VERSION "HNNBNNNYNNNNNNNNNNNNNNNNNNNNNNNNNNNNNNNNNN/4/%%%/4/'%**4NNN///"

NS_ :

BS_:

BU_: BAP_Tester BedienDisp_mi BedienDisp_vo_mi CDI ConMod_CD DashCAM Gateway_Max ICC_IO_Node LSH OCU RDK_RS3 Sound_MIB_ab_Gen3 STH ZR_MIB_EINSTIEG_ab_Gen3 ZR_MIB_OPTION_ab_Gen3 ZR_MIB_TOP_ab_Gen3

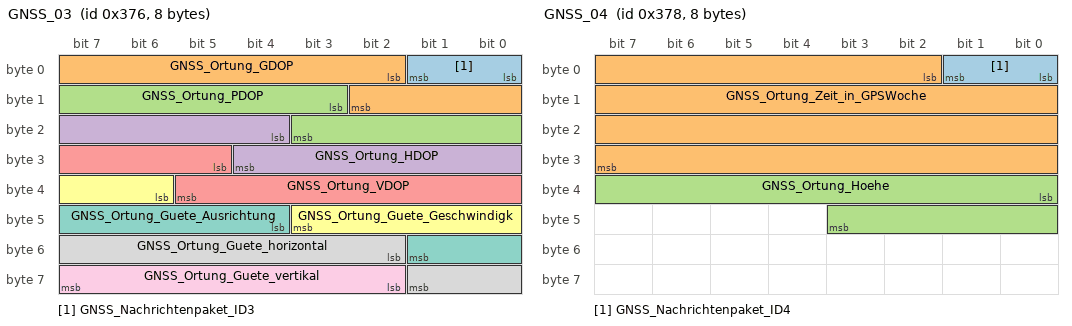
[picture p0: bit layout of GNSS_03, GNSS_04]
BO_ 886 GNSS_03: 8 OCU
 SG_ GNSS_Nachrichtenpaket_ID3 : 0|2@1+ (1,0) [0|3] "Unit_Bit"  Gateway_Max,ZR_MIB_EINSTIEG_ab_Gen3,ZR_MIB_TOP_ab_Gen3
 SG_ GNSS_Ortung_GDOP : 2|9@1+ (0.1,0) [0.0|50.0] "Unit_None"  Gateway_Max,ZR_MIB_EINSTIEG_ab_Gen3,ZR_MIB_TOP_ab_Gen3
 SG_ GNSS_Ortung_PDOP : 11|9@1+ (0.1,0) [0.0|50.0] "Unit_None"  Gateway_Max,ZR_MIB_EINSTIEG_ab_Gen3,ZR_MIB_TOP_ab_Gen3
 SG_ GNSS_Ortung_HDOP : 20|9@1+ (0.1,0) [0.0|50.0] "Unit_None"  Gateway_Max,ZR_MIB_EINSTIEG_ab_Gen3,ZR_MIB_TOP_ab_Gen3
 SG_ GNSS_Ortung_VDOP : 29|9@1+ (0.1,0) [0.0|50.0] "Unit_None"  Gateway_Max,ZR_MIB_EINSTIEG_ab_Gen3,ZR_MIB_TOP_ab_Gen3
 SG_ GNSS_Ortung_Guete_Geschwindigk : 38|6@1+ (0.05,0) [0.00|3.05] "Unit_MeterPerSecon"  Gateway_Max,ZR_MIB_EINSTIEG_ab_Gen3,ZR_MIB_TOP_ab_Gen3
 SG_ GNSS_Ortung_Guete_Ausrichtung : 44|6@1+ (0.15,0) [0.00|9.15] "Unit_DegreOfArc"  Gateway_Max,ZR_MIB_EINSTIEG_ab_Gen3,ZR_MIB_TOP_ab_Gen3
 SG_ GNSS_Ortung_Guete_horizontal : 50|8@1+ (1,0) [0|250] "Unit_Meter"  Gateway_Max,ZR_MIB_EINSTIEG_ab_Gen3,ZR_MIB_TOP_ab_Gen3
 SG_ GNSS_Ortung_Guete_vertikal : 58|6@1+ (2,0) [0|122] "Unit_Meter"  Gateway_Max,ZR_MIB_EINSTIEG_ab_Gen3,ZR_MIB_TOP_ab_Gen3

BO_ 888 GNSS_04: 8 OCU
 SG_ GNSS_Nachrichtenpaket_ID4 : 0|2@1+ (1,0) [0|3] "Unit_Bit"  Gateway_Max,ZR_MIB_EINSTIEG_ab_Gen3,ZR_MIB_TOP_ab_Gen3
 SG_ GNSS_Ortung_Zeit_in_GPSWoche : 2|30@1+ (1,0) [0|604800001] "Unit_MilliSecon"  Gateway_Max,ZR_MIB_EINSTIEG_ab_Gen3,ZR_MIB_TOP_ab_Gen3
 SG_ GNSS_Ortung_Hoehe : 32|12@1+ (2,-500) [-500|7686] "Unit_Meter"  Gateway_Max,ZR_MIB_EINSTIEG_ab_Gen3,ZR_MIB_TOP_ab_Gen3

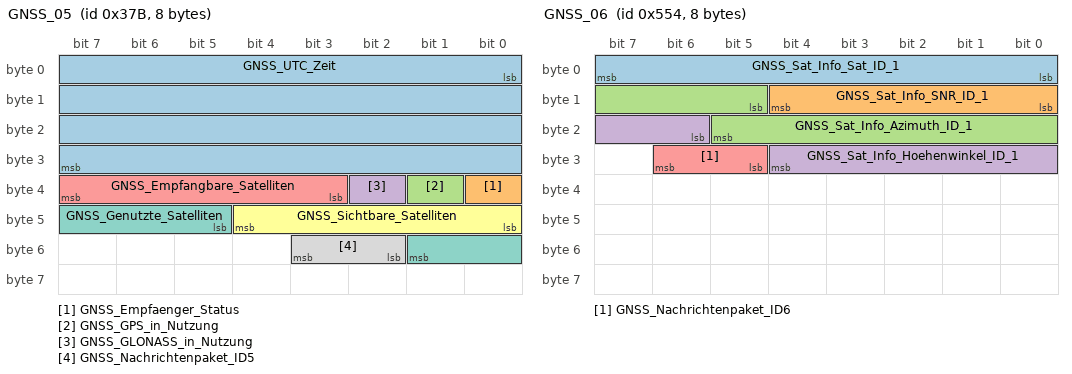
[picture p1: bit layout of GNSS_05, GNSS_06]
BO_ 891 GNSS_05: 8 OCU
 SG_ GNSS_UTC_Zeit : 0|32@1+ (1,0) [1|4294967295] "Unit_Secon"  Gateway_Max,ZR_MIB_EINSTIEG_ab_Gen3,ZR_MIB_TOP_ab_Gen3
 SG_ GNSS_Empfaenger_Status : 32|1@1+ (1.0,0.0) [0.0|1] ""  Gateway_Max,ZR_MIB_EINSTIEG_ab_Gen3,ZR_MIB_TOP_ab_Gen3
 SG_ GNSS_GPS_in_Nutzung : 33|1@1+ (1.0,0.0) [0.0|1] ""  Gateway_Max,ZR_MIB_EINSTIEG_ab_Gen3,ZR_MIB_TOP_ab_Gen3
 SG_ GNSS_GLONASS_in_Nutzung : 34|1@1+ (1.0,0.0) [0.0|1] ""  Gateway_Max,ZR_MIB_EINSTIEG_ab_Gen3,ZR_MIB_TOP_ab_Gen3
 SG_ GNSS_Empfangbare_Satelliten : 35|5@1+ (1,0) [1|30] "Unit_None"  Gateway_Max,ZR_MIB_EINSTIEG_ab_Gen3,ZR_MIB_TOP_ab_Gen3
 SG_ GNSS_Sichtbare_Satelliten : 40|5@1+ (1,0) [1|30] "Unit_None"  Gateway_Max,ZR_MIB_EINSTIEG_ab_Gen3,ZR_MIB_TOP_ab_Gen3
 SG_ GNSS_Genutzte_Satelliten : 45|5@1+ (1,0) [1|30] "Unit_None"  Gateway_Max,ZR_MIB_EINSTIEG_ab_Gen3,ZR_MIB_TOP_ab_Gen3
 SG_ GNSS_Nachrichtenpaket_ID5 : 50|2@1+ (1,0) [0|3] "Unit_Bit"  Gateway_Max,ZR_MIB_EINSTIEG_ab_Gen3,ZR_MIB_TOP_ab_Gen3

BO_ 1364 GNSS_06: 8 OCU
 SG_ GNSS_Sat_Info_Sat_ID_1 : 0|8@1+ (1,0) [0|255] ""  ZR_MIB_EINSTIEG_ab_Gen3,ZR_MIB_TOP_ab_Gen3
 SG_ GNSS_Sat_Info_SNR_ID_1 : 8|5@1+ (2,0) [0|60] "Unit_DeziBel"  ZR_MIB_EINSTIEG_ab_Gen3,ZR_MIB_TOP_ab_Gen3
 SG_ GNSS_Sat_Info_Azimuth_ID_1 : 13|9@1+ (1,0) [0|359] "Unit_DegreOfArc"  ZR_MIB_EINSTIEG_ab_Gen3,ZR_MIB_TOP_ab_Gen3
 SG_ GNSS_Sat_Info_Hoehenwinkel_ID_1 : 22|7@1+ (1,0) [0|90] "Unit_DegreOfArc"  ZR_MIB_EINSTIEG_ab_Gen3,ZR_MIB_TOP_ab_Gen3
 SG_ GNSS_Nachrichtenpaket_ID6 : 29|2@1+ (1,0) [0|3] "Unit_Bit"  ZR_MIB_EINSTIEG_ab_Gen3,ZR_MIB_TOP_ab_Gen3

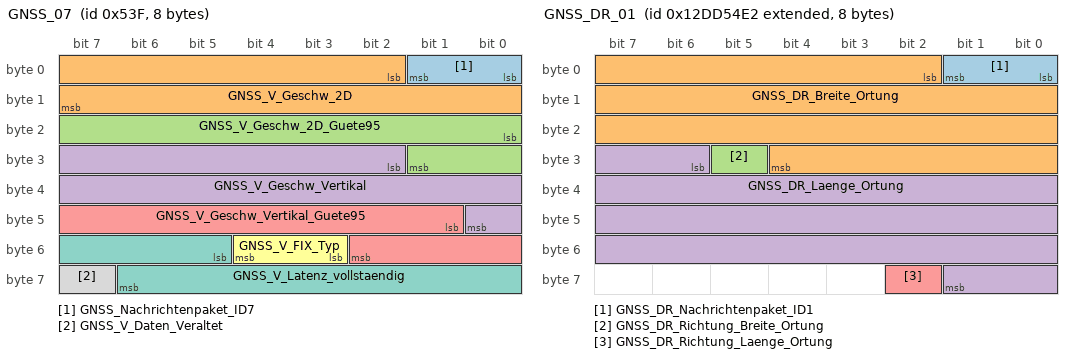
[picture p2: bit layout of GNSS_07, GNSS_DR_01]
BO_ 1343 GNSS_07: 8 OCU
 SG_ GNSS_Nachrichtenpaket_ID7 : 0|2@1+ (1,0) [0|3] "Unit_None"  Gateway_Max
 SG_ GNSS_V_Geschw_2D : 2|14@1+ (0.01,0) [0.00|163.00] "Unit_MeterPerSecon"  Gateway_Max
 SG_ GNSS_V_Geschw_2D_Guete95 : 16|10@1+ (0.01,0) [0.00|10.00] "Unit_MeterPerSecon"  Gateway_Max
 SG_ GNSS_V_Geschw_Vertikal : 26|15@1+ (0.01,-163) [-163.00|163.00] "Unit_MeterPerSecon"  Gateway_Max
 SG_ GNSS_V_Geschw_Vertikal_Guete95 : 41|10@1+ (0.01,0) [0.00|10.00] "Unit_MeterPerSecon"  Gateway_Max
 SG_ GNSS_V_FIX_Typ : 51|2@1+ (1.0,0.0) [0.0|3] ""  Gateway_Max
 SG_ GNSS_V_Latenz_vollstaendig : 53|10@1+ (1,0) [0|1021] "Unit_MilliSecon"  Gateway_Max
 SG_ GNSS_V_Daten_Veraltet : 63|1@1+ (1.0,0.0) [0.0|1] ""  Gateway_Max

BO_ 2463978722 GNSS_DR_01: 8 Gateway_Max
 SG_ GNSS_DR_Nachrichtenpaket_ID1 : 0|2@1+ (1,0) [0|3] "Unit_Bit"  Gateway_Max,ZR_MIB_EINSTIEG_ab_Gen3
 SG_ GNSS_DR_Breite_Ortung : 2|27@1+ (0.000001,0) [0.000000|90.000000] "Unit_DegreOfArc"  Gateway_Max,ZR_MIB_EINSTIEG_ab_Gen3
 SG_ GNSS_DR_Richtung_Breite_Ortung : 29|1@1+ (1.0,0.0) [0.0|1] ""  Gateway_Max,ZR_MIB_EINSTIEG_ab_Gen3
 SG_ GNSS_DR_Laenge_Ortung : 30|28@1+ (0.000001,0) [0.000000|180.000000] "Unit_DegreOfArc"  Gateway_Max,ZR_MIB_EINSTIEG_ab_Gen3
 SG_ GNSS_DR_Richtung_Laenge_Ortung : 58|1@1+ (1.0,0.0) [0.0|1] ""  Gateway_Max,ZR_MIB_EINSTIEG_ab_Gen3

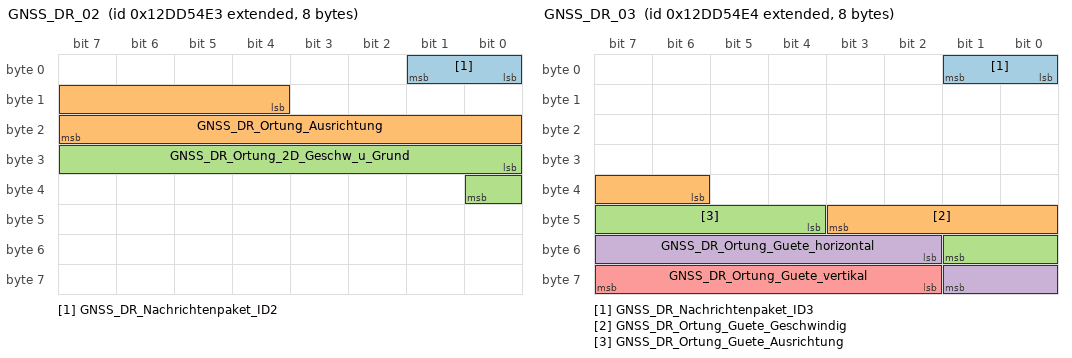
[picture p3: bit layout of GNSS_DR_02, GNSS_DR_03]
BO_ 2463978723 GNSS_DR_02: 8 Gateway_Max
 SG_ GNSS_DR_Nachrichtenpaket_ID2 : 0|2@1+ (1,0) [0|3] "Unit_Bit"  Gateway_Max,ZR_MIB_EINSTIEG_ab_Gen3
 SG_ GNSS_DR_Ortung_Ausrichtung : 12|12@1+ (0.1,0) [0.0|359.9] "Unit_DegreOfArc"  Gateway_Max,ZR_MIB_EINSTIEG_ab_Gen3
 SG_ GNSS_DR_Ortung_2D_Geschw_u_Grund : 24|9@1+ (0.25,0) [0.00|125.00] "Unit_MeterPerSecon"  Gateway_Max,ZR_MIB_EINSTIEG_ab_Gen3

BO_ 2463978724 GNSS_DR_03: 8 Gateway_Max
 SG_ GNSS_DR_Nachrichtenpaket_ID3 : 0|2@1+ (1,0) [0|3] "Unit_Bit"  Gateway_Max,ZR_MIB_EINSTIEG_ab_Gen3
 SG_ GNSS_DR_Ortung_Guete_Geschwindig : 38|6@1+ (0.05,0) [0.00|3.05] "Unit_MeterPerSecon"  ZR_MIB_EINSTIEG_ab_Gen3
 SG_ GNSS_DR_Ortung_Guete_Ausrichtung : 44|6@1+ (0.15,0) [0.00|9.15] "Unit_DegreOfArc"  ZR_MIB_EINSTIEG_ab_Gen3
 SG_ GNSS_DR_Ortung_Guete_horizontal : 50|8@1+ (1,0) [0|250] "Unit_Meter"  Gateway_Max,ZR_MIB_EINSTIEG_ab_Gen3
 SG_ GNSS_DR_Ortung_Guete_vertikal : 58|6@1+ (2,0) [0|122] "Unit_Meter"  ZR_MIB_EINSTIEG_ab_Gen3

BO_ 2463978726 GNSS_DR_05: 8 Gateway_Max
 SG_ GNSS_DR_UTC_Zeit : 0|32@1+ (1,0) [1|4294967295] "Unit_Secon"  Gateway_Max,ZR_MIB_EINSTIEG_ab_Gen3

BO_ 299 GRA_ACC_01: 8 Gateway_Max
 SG_ GRA_ACC_01_CRC : 0|8@1+ (1,0) [0|255] ""  OCU
 SG_ GRA_ACC_01_BZ : 8|4@1+ (1,0) [0|15] ""  OCU
 SG_ GRA_Hauptschalter : 12|1@1+ (1.0,0.0) [0.0|1] ""  OCU
 SG_ GRA_Abbrechen : 13|1@1+ (1.0,0.0) [0.0|1] ""  OCU
 SG_ GRA_Typ_Hauptschalter : 14|1@1+ (1.0,0.0) [0.0|1] ""  OCU
 SG_ GRA_Limiter : 15|1@1+ (1.0,0.0) [0.0|1] ""  OCU
 SG_ GRA_Tip_Setzen : 16|1@1+ (1.0,0.0) [0.0|1] ""  OCU
 SG_ GRA_Tip_Hoch : 17|1@1+ (1.0,0.0) [0.0|1] ""  OCU
 SG_ GRA_Tip_Runter : 18|1@1+ (1.0,0.0) [0.0|1] ""  OCU
 SG_ GRA_Tip_Wiederaufnahme : 19|1@1+ (1.0,0.0) [0.0|1] ""  OCU
 SG_ GRA_Verstellung_Zeitluecke : 20|2@1+ (1.0,0.0) [0.0|3] ""  OCU
 SG_ GRA_Codierung : 22|2@1+ (1.0,0.0) [0.0|3] ""  OCU
 SG_ GRA_Fehler : 24|1@1+ (1.0,0.0) [0.0|1] ""  OCU
 SG_ GRA_LIM_Taste_verfuegbar : 25|1@1+ (1.0,0.0) [0.0|1] ""  OCU
 SG_ GRA_Tip_Stufe_2 : 26|1@1+ (1.0,0.0) [0.0|1] ""  OCU
 SG_ GRA_Typ_Bedienteil : 27|3@1+ (1.0,0.0) [0.0|7] ""  OCU
 SG_ GRA_TravelAssist : 30|1@1+ (1.0,0.0) [0.0|1] ""  OCU
 SG_ GRA_PIT_Limiter : 31|1@1+ (1.0,0.0) [0.0|1] ""  OCU
 SG_ GRA_reserveByte5 : 32|8@1+ (1.0,0.0) [0.0|255] ""  OCU
 SG_ GRA_reserveByte6 : 40|8@1+ (1.0,0.0) [0.0|255] ""  OCU
 SG_ GRA_reserveByte7 : 48|8@1+ (1.0,0.0) [0.0|255] ""  OCU
 SG_ GRA_reserveByte8 : 56|8@1+ (1.0,0.0) [0.0|255] ""  OCU

BO_ 29 IMMO_OCU_Antwort: 8 Gateway_Max
 SG_ WFS_IMMO_OCU_CRC : 0|32@1+ (1.0,0.0) [0.0|4294967295] ""  OCU
 SG_ WFS_IMMO_OCU_RND : 32|32@1+ (1.0,0.0) [0.0|4294967295] ""  OCU

BO_ 2583720728 Info_El_AuthTime_Req: 8 ICC_IO_Node
 SG_ Info_El_AuthTime_Req_Data : 0|64@1+ (1.0,0.0) [0.0|18446744073709551615] ""  Gateway_Max

BO_ 2583851800 Info_El_AuthTime_Resp: 8 Gateway_Max
 SG_ Info_El_AuthTime_Resp_Data : 0|64@1+ (1.0,0.0) [0.0|18446744073709551615] ""  ICC_IO_Node,ZR_MIB_EINSTIEG_ab_Gen3,ZR_MIB_OPTION_ab_Gen3,ZR_MIB_TOP_ab_Gen3

BO_ 1895 ISO_eCall_Req: 8 Gateway_Max
 SG_ ISO_eCall_Req_Data : 0|64@1+ (1.0,0.0) [0.0|18446744073709551615] ""  ConMod_CD,OCU

BO_ 2001 ISO_eCall_Resp: 8 ConMod_CD
 SG_ ISO_eCall_Resp_Data : 0|64@1+ (1.0,0.0) [0.0|18446744073709551615] ""  Gateway_Max

BO_ 2549351183 ISO_FoD_ManFoD_Req: 8 Gateway_Max
 SG_ ISO_FoD_ManFoD_Req_Data : 0|64@1+ (1.0,0.0) [0.0|18446744073709551615] ""  ConMod_CD,OCU

BO_ 2549485315 ISO_FoD_ManFoD_Resp: 8 ConMod_CD
 SG_ ISO_FoD_ManFoD_Resp_Data : 0|64@1+ (1.0,0.0) [0.0|18446744073709551615] ""  Gateway_Max

BO_ 1792 ISO_Funktionaler_Req_All: 8 Gateway_Max
 SG_ ISO_ALL_01_Req_Data : 0|64@1+ (1.0,0.0) [0.0|18446744073709551615] ""  BedienDisp_mi,BedienDisp_vo_mi,ConMod_CD,ICC_IO_Node,LSH,OCU,RDK_RS3,STH,ZR_MIB_EINSTIEG_ab_Gen3,ZR_MIB_OPTION_ab_Gen3,ZR_MIB_TOP_ab_Gen3

BO_ 1907 ISO_Info_El_Req: 8 Gateway_Max
 SG_ ISO_Info_El_Req_Data : 0|64@1+ (1.0,0.0) [0.0|18446744073709551615] ""  ZR_MIB_EINSTIEG_ab_Gen3,ZR_MIB_OPTION_ab_Gen3,ZR_MIB_TOP_ab_Gen3

BO_ 2013 ISO_Info_El_Resp: 8 ZR_MIB_EINSTIEG_ab_Gen3
 SG_ ISO_Info_El_Resp_Data : 0|64@1+ (1.0,0.0) [0.0|18446744073709551615] ""  Gateway_Max

BO_ 2549354243 ISO_ManFoD_FoD_Req: 8 ConMod_CD
 SG_ ISO_ManFoD_FoD_Req_Data : 0|64@1+ (1.0,0.0) [0.0|18446744073709551615] ""  Gateway_Max

BO_ 2549482255 ISO_ManFoD_FoD_Resp: 8 Gateway_Max
 SG_ ISO_ManFoD_FoD_Resp_Data : 0|64@1+ (1.0,0.0) [0.0|18446744073709551615] ""  ConMod_CD,OCU

BO_ 1803 ISO_RDK_Req: 8 Gateway_Max
 SG_ ISO_RDK_Req_Data : 0|64@1+ (1.0,0.0) [0.0|18446744073709551615] ""  RDK_RS3

BO_ 1909 ISO_RDK_Resp: 8 RDK_RS3
 SG_ ISO_RDK_Resp_Data : 0|64@1+ (1.0,0.0) [0.0|18446744073709551615] ""  Gateway_Max

BO_ 1898 ISO_STH_Req: 8 Gateway_Max
 SG_ ISO_STH_Req_Data : 0|64@1+ (1.0,0.0) [0.0|18446744073709551615] ""  STH

BO_ 2004 ISO_STH_Resp: 8 STH
 SG_ ISO_STH_Resp_Data : 0|64@1+ (1.0,0.0) [0.0|18446744073709551615] ""  Gateway_Max

BO_ 1901 ISO_TV_Tuner_Req: 8 Gateway_Max
 SG_ ISO_TV_Tuner_Req_Data : 0|64@1+ (1.0,0.0) [0.0|18446744073709551615] ""  ZR_MIB_TOP_ab_Gen3

BO_ 2007 ISO_TV_Tuner_Resp: 8 ZR_MIB_TOP_ab_Gen3
 SG_ ISO_TV_Tuner_Resp_Data : 0|64@1+ (1.0,0.0) [0.0|18446744073709551615] ""  Gateway_Max

BO_ 2550399028 ISOx_BedienDisp_m_Req: 8 Gateway_Max
 SG_ ISOx_BedienDisp_m_Req_Data : 0|64@1+ (1.0,0.0) [0.0|18446744073709551615] ""  BedienDisp_mi

BO_ 2550530100 ISOx_BedienDisp_m_Resp: 8 BedienDisp_mi
 SG_ ISOx_BedienDisp_m_Resp_Data : 0|64@1+ (1.0,0.0) [0.0|18446744073709551615] ""  Gateway_Max

BO_ 2549874850 ISOx_BedienDisp_vm_Req: 8 Gateway_Max
 SG_ ISOx_BedienDisp_vm_Req_Data : 0|64@1+ (1.0,0.0) [0.0|18446744073709551615] ""  BedienDisp_vo_mi

BO_ 2550005922 ISOx_BedienDisp_vm_Resp: 8 BedienDisp_vo_mi
 SG_ ISOx_BedienDisp_vm_Resp_Data : 0|64@1+ (1.0,0.0) [0.0|18446744073709551615] ""  Gateway_Max

BO_ 2549874852 ISOx_LSH_Req: 8 Gateway_Max
 SG_ ISOx_LSH_Req_Data : 0|64@1+ (1.0,0.0) [0.0|18446744073709551615] ""  LSH

BO_ 2550005924 ISOx_LSH_Resp: 8 LSH
 SG_ ISOx_LSH_Resp_Data : 0|64@1+ (1.0,0.0) [0.0|18446744073709551615] ""  Gateway_Max

BO_ 2549874853 ISOx_WLC1_Req: 8 Gateway_Max
 SG_ ISOx_WLC1_Req_Data : 0|64@1+ (1.0,0.0) [0.0|18446744073709551615] ""  ZR_MIB_OPTION_ab_Gen3,ZR_MIB_TOP_ab_Gen3

BO_ 2550005925 ISOx_WLC1_Resp: 8 ZR_MIB_OPTION_ab_Gen3
 SG_ ISOx_WLC1_Resp_Data : 0|64@1+ (1.0,0.0) [0.0|18446744073709551615] ""  Gateway_Max

BO_ 1426 Kessy_04: 8 Gateway_Max
 SG_ KY_ID_Geber1_im_Fzg : 12|1@1+ (1.0,0.0) [0.0|1] ""  Vector__XXX
 SG_ KY_ID_Geber2_im_Fzg : 13|1@1+ (1.0,0.0) [0.0|1] ""  Vector__XXX
 SG_ KY_ID_Geber3_im_Fzg : 14|1@1+ (1.0,0.0) [0.0|1] ""  Vector__XXX
 SG_ KY_ID_Geber4_im_Fzg : 15|1@1+ (1.0,0.0) [0.0|1] ""  Vector__XXX
 SG_ KY_Startknopf_Bel : 16|1@1+ (1.0,0.0) [0.0|1] ""  Vector__XXX
 SG_ KY_ID_Geber_Suche : 17|1@1+ (1.0,0.0) [0.0|1] ""  Vector__XXX
 SG_ KY_Meldungen : 18|4@1+ (1.0,0.0) [0.0|15] ""  Vector__XXX
 SG_ KY_Gong_600 : 22|1@1+ (1.0,0.0) [0.0|1] ""  Vector__XXX
 SG_ KY_Passiv_Autolock_Menue : 23|1@1+ (1.0,0.0) [0.0|1] ""  Vector__XXX
 SG_ KY_Passiv_Autolock_Akt : 24|1@1+ (1.0,0.0) [0.0|1] ""  Vector__XXX
 SG_ KY_Passiv_Autolock : 25|1@1+ (1.0,0.0) [0.0|1] ""  Vector__XXX
 SG_ KY_Passiv_Autounlock : 26|1@1+ (1.0,0.0) [0.0|1] ""  Vector__XXX
 SG_ KY_Gestik_HD : 27|1@1+ (1.0,0.0) [0.0|1] ""  Vector__XXX
 SG_ KY_StartStopp_Info : 28|2@1+ (1.0,0.0) [0.0|3] ""  Vector__XXX
 SG_ KY_Fzg_Verlassen_erkannt : 30|1@1+ (1.0,0.0) [0.0|1] ""  Vector__XXX
 SG_ KY_Fzg_Zugang_erkannt : 31|1@1+ (1.0,0.0) [0.0|1] ""  Vector__XXX
 SG_ KY_EasyClose_Abbruch : 32|1@1+ (1.0,0.0) [0.0|1] ""  Vector__XXX
 SG_ KY_EasyClose_Status : 33|3@1+ (1.0,0.0) [0.0|7] ""  Vector__XXX
 SG_ KY_HD_Auffahrt : 36|1@1+ (1.0,0.0) [0.0|1] ""  Vector__XXX
 SG_ KY_HD_Zufahrt : 37|1@1+ (1.0,0.0) [0.0|1] ""  Vector__XXX
 SG_ KY_Aktive_LFScans : 38|4@1+ (1.0,0.0) [0.0|15] ""  Vector__XXX
 SG_ KY_LF_Aktiv : 42|1@1+ (1.0,0.0) [0.0|1] ""  ZR_MIB_EINSTIEG_ab_Gen3,ZR_MIB_OPTION_ab_Gen3,ZR_MIB_TOP_ab_Gen3
 SG_ KY_AnzKoord_Info : 43|2@1+ (1.0,0.0) [0.0|3] ""  Vector__XXX
 SG_ KY_Schluesselposition_9 : 45|2@1+ (1.0,0.0) [0.0|3] ""  Vector__XXX
 SG_ KY_Schluesselposition_1 : 48|2@1+ (1.0,0.0) [0.0|3] ""  Vector__XXX
 SG_ KY_Schluesselposition_2 : 50|2@1+ (1.0,0.0) [0.0|3] ""  Vector__XXX
 SG_ KY_Schluesselposition_3 : 52|2@1+ (1.0,0.0) [0.0|3] ""  Vector__XXX
 SG_ KY_Schluesselposition_4 : 54|2@1+ (1.0,0.0) [0.0|3] ""  Vector__XXX
 SG_ KY_Schluesselposition_5 : 56|2@1+ (1.0,0.0) [0.0|3] ""  Vector__XXX
 SG_ KY_Schluesselposition_6 : 58|2@1+ (1.0,0.0) [0.0|3] ""  Vector__XXX
 SG_ KY_Schluesselposition_7 : 60|2@1+ (1.0,0.0) [0.0|3] ""  Vector__XXX
 SG_ KY_Schluesselposition_8 : 62|2@1+ (1.0,0.0) [0.0|3] ""  Vector__XXX

BO_ 960 Klemmen_Status_01: 4 Gateway_Max
 SG_ Klemmen_Status_01_CRC : 0|8@1+ (1,0) [0|255] ""  ICC_IO_Node,ZR_MIB_EINSTIEG_ab_Gen3,ZR_MIB_OPTION_ab_Gen3,ZR_MIB_TOP_ab_Gen3
 SG_ Klemmen_Status_01_BZ : 8|4@1+ (1,0) [0|15] ""  ICC_IO_Node,ZR_MIB_EINSTIEG_ab_Gen3,ZR_MIB_OPTION_ab_Gen3,ZR_MIB_TOP_ab_Gen3
 SG_ RSt_Fahrerhinweise : 12|4@1+ (1.0,0.0) [0.0|15] ""  ICC_IO_Node,ZR_MIB_EINSTIEG_ab_Gen3,ZR_MIB_OPTION_ab_Gen3,ZR_MIB_TOP_ab_Gen3
 SG_ ZAS_Kl_S : 16|1@1+ (1.0,0.0) [0.0|1] ""  BedienDisp_mi,BedienDisp_vo_mi,CDI,ConMod_CD,ICC_IO_Node,LSH,OCU,STH,ZR_MIB_EINSTIEG_ab_Gen3,ZR_MIB_OPTION_ab_Gen3,ZR_MIB_TOP_ab_Gen3
 SG_ ZAS_Kl_15 : 17|1@1+ (1.0,0.0) [0.0|1] ""  BedienDisp_mi,BedienDisp_vo_mi,CDI,ConMod_CD,DashCAM,ICC_IO_Node,LSH,OCU,RDK_RS3,STH,ZR_MIB_EINSTIEG_ab_Gen3,ZR_MIB_OPTION_ab_Gen3,ZR_MIB_TOP_ab_Gen3
 SG_ ZAS_Kl_X : 18|1@1+ (1.0,0.0) [0.0|1] ""  ICC_IO_Node,ZR_MIB_EINSTIEG_ab_Gen3,ZR_MIB_OPTION_ab_Gen3,ZR_MIB_TOP_ab_Gen3
 SG_ ZAS_Kl_50_Startanforderung : 19|1@1+ (1.0,0.0) [0.0|1] ""  ICC_IO_Node,ZR_MIB_EINSTIEG_ab_Gen3,ZR_MIB_OPTION_ab_Gen3,ZR_MIB_TOP_ab_Gen3
 SG_ BCM_Remotestart_Betrieb : 20|1@1+ (1.0,0.0) [0.0|1] ""  ICC_IO_Node,OCU,ZR_MIB_EINSTIEG_ab_Gen3,ZR_MIB_OPTION_ab_Gen3,ZR_MIB_TOP_ab_Gen3
 SG_ ZAS_Kl_Infotainment : 21|1@1+ (1.0,0.0) [0.0|1] ""  ICC_IO_Node,ZR_MIB_EINSTIEG_ab_Gen3,ZR_MIB_OPTION_ab_Gen3,ZR_MIB_TOP_ab_Gen3
 SG_ BCM_Remotestart_KL15_Anf : 22|1@1+ (1.0,0.0) [0.0|1] ""  ICC_IO_Node,ZR_MIB_EINSTIEG_ab_Gen3,ZR_MIB_OPTION_ab_Gen3,ZR_MIB_TOP_ab_Gen3
 SG_ BCM_Remotestart_MO_Start : 23|1@1+ (1.0,0.0) [0.0|1] ""  ICC_IO_Node,ZR_MIB_EINSTIEG_ab_Gen3,ZR_MIB_OPTION_ab_Gen3,ZR_MIB_TOP_ab_Gen3
 SG_ KST_Warn_P1_ZST_def : 24|1@1+ (1.0,0.0) [0.0|1] ""  ICC_IO_Node,ZR_MIB_EINSTIEG_ab_Gen3,ZR_MIB_OPTION_ab_Gen3,ZR_MIB_TOP_ab_Gen3
 SG_ KST_Warn_P2_ZST_def : 25|1@1+ (1.0,0.0) [0.0|1] ""  ICC_IO_Node,ZR_MIB_EINSTIEG_ab_Gen3,ZR_MIB_OPTION_ab_Gen3,ZR_MIB_TOP_ab_Gen3
 SG_ KST_Fahrerhinweis_1 : 26|1@1+ (1.0,0.0) [0.0|1] ""  ICC_IO_Node,ZR_MIB_EINSTIEG_ab_Gen3,ZR_MIB_OPTION_ab_Gen3,ZR_MIB_TOP_ab_Gen3
 SG_ KST_Fahrerhinweis_2 : 27|1@1+ (1.0,0.0) [0.0|1] ""  ICC_IO_Node,ZR_MIB_EINSTIEG_ab_Gen3,ZR_MIB_OPTION_ab_Gen3,ZR_MIB_TOP_ab_Gen3
 SG_ BCM_Ausparken_Betrieb : 28|1@1+ (1.0,0.0) [0.0|1] ""  ICC_IO_Node,ZR_MIB_EINSTIEG_ab_Gen3,ZR_MIB_OPTION_ab_Gen3,ZR_MIB_TOP_ab_Gen3
 SG_ KST_Fahrerhinweis_4 : 29|1@1+ (1.0,0.0) [0.0|1] ""  ICC_IO_Node,ZR_MIB_EINSTIEG_ab_Gen3,ZR_MIB_OPTION_ab_Gen3,ZR_MIB_TOP_ab_Gen3
 SG_ KST_Fahrerhinweis_5 : 30|1@1+ (1.0,0.0) [0.0|1] ""  ICC_IO_Node,ZR_MIB_EINSTIEG_ab_Gen3,ZR_MIB_OPTION_ab_Gen3,ZR_MIB_TOP_ab_Gen3
 SG_ KST_Fahrerhinweis_6 : 31|1@1+ (1.0,0.0) [0.0|1] ""  ICC_IO_Node,ZR_MIB_EINSTIEG_ab_Gen3,ZR_MIB_OPTION_ab_Gen3,ZR_MIB_TOP_ab_Gen3

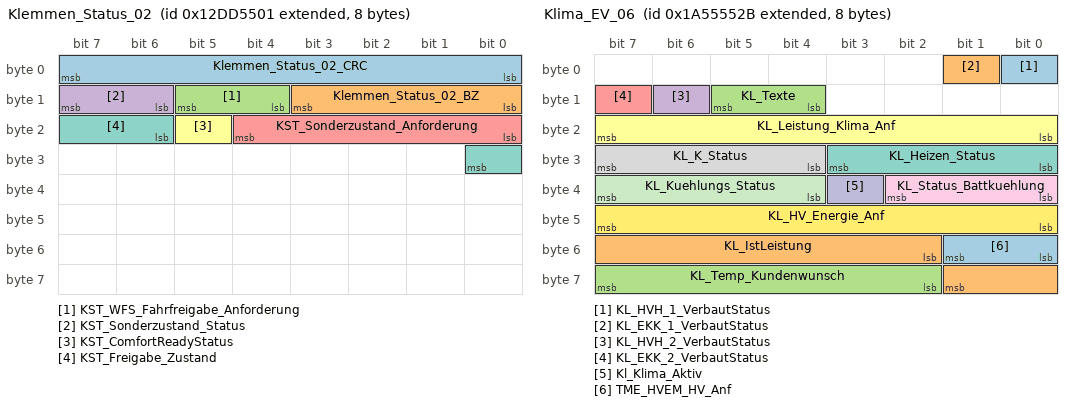
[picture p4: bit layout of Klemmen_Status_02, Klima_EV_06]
BO_ 2463978753 Klemmen_Status_02: 8 Gateway_Max
 SG_ Klemmen_Status_02_CRC : 0|8@1+ (1,0) [0|255] ""  Vector__XXX
 SG_ Klemmen_Status_02_BZ : 8|4@1+ (1,0) [0|15] ""  Vector__XXX
 SG_ KST_WFS_Fahrfreigabe_Anforderung : 12|2@1+ (1.0,0.0) [0.0|3] ""  Vector__XXX
 SG_ KST_Sonderzustand_Status : 14|2@1+ (1.0,0.0) [0.0|3] ""  ZR_MIB_EINSTIEG_ab_Gen3,ZR_MIB_OPTION_ab_Gen3,ZR_MIB_TOP_ab_Gen3
 SG_ KST_Sonderzustand_Anforderung : 16|5@1+ (1.0,0.0) [0.0|31] ""  ZR_MIB_EINSTIEG_ab_Gen3,ZR_MIB_OPTION_ab_Gen3,ZR_MIB_TOP_ab_Gen3
 SG_ KST_ComfortReadyStatus : 21|1@1+ (1.0,0.0) [0.0|1] ""  Vector__XXX
 SG_ KST_Freigabe_Zustand : 22|3@1+ (1.0,0.0) [0.0|7] ""  ZR_MIB_EINSTIEG_ab_Gen3,ZR_MIB_OPTION_ab_Gen3

BO_ 1646 Klima_03: 8 Gateway_Max
 SG_ KL_STL_aktiv : 0|1@1+ (1.0,0.0) [0.0|1] ""  LSH,STH
 SG_ KL_STH_aktiv : 1|1@1+ (1.0,0.0) [0.0|1] ""  LSH
 SG_ KL_Solarluefter_aktiv : 2|1@1+ (1.0,0.0) [0.0|1] ""  Vector__XXX
 SG_ KL_Umluft_Taste : 3|1@1+ (1.0,0.0) [0.0|1] ""  OCU
 SG_ KL_Geblaese_Fond_Status : 4|4@1+ (1.0,0.0) [0.0|15] ""  Vector__XXX
 SG_ KL_STH_Ansteuerung : 8|2@1+ (1.0,0.0) [0.0|3] ""  LSH,STH
 SG_ KL_STH_Betriebsdauer : 10|6@1+ (1,0) [0|60] "Unit_Minut"  LSH,STH
 SG_ KL_Magnetventil : 16|1@1+ (1.0,0.0) [0.0|1] ""  STH
 SG_ KL_WaPu : 17|1@1+ (1.0,0.0) [0.0|1] ""  STH
 SG_ KL_Geblaese_Status : 18|4@1+ (1.0,0.0) [0.0|15] ""  BedienDisp_vo_mi,OCU
 SG_ KL_Restwaerme_aktiv : 22|1@1+ (1.0,0.0) [0.0|1] ""  Vector__XXX
 SG_ KL_Kompressorkupplung : 23|1@1+ (1.0,0.0) [0.0|1] ""  Vector__XXX
 SG_ KL_BCmE_Livetip_Freigabe : 24|1@1+ (1.0,0.0) [0.0|1] ""  Vector__XXX
 SG_ KL_SH_Soll_hl : 25|3@1+ (1.0,0.0) [0.0|7] ""  OCU
 SG_ KL_SH_Soll_hr : 28|3@1+ (1.0,0.0) [0.0|7] ""  OCU
 SG_ KL_ErwVK_Anf : 31|1@1+ (1.0,0.0) [0.0|1] ""  Vector__XXX
 SG_ KL_Innen_Temp : 32|8@1+ (0.5,-50) [-50.0|76.0] "Unit_DegreCelsi"  ConMod_CD,OCU,ZR_MIB_EINSTIEG_ab_Gen3,ZR_MIB_OPTION_ab_Gen3
 SG_ KL_I_Geblaese_Fond : 40|8@1+ (0.25,0) [0.00|63.50] "Unit_Amper"  Vector__XXX
 SG_ KL_Anf_AussenspiegelHzg : 48|1@1+ (1.0,0.0) [0.0|1] ""  OCU
 SG_ KL_Heizkreisventilstellung : 49|2@1+ (1.0,0.0) [0.0|3] ""  STH
 SG_ KL_FSH_Automatikbetrieb : 51|1@1+ (1.0,0.0) [0.0|1] ""  Vector__XXX
 SG_ KL_SIH_LEH_Verteilung_VL : 52|3@1+ (1.0,0.0) [0.0|7] ""  Vector__XXX
 SG_ KL_SIH_LEL_Verteilung_VL : 55|3@1+ (1.0,0.0) [0.0|7] ""  Vector__XXX
 SG_ KL_SIH_LEH_Verteilung_VR : 58|3@1+ (1.0,0.0) [0.0|7] ""  Vector__XXX
 SG_ KL_SIH_LEL_Verteilung_VR : 61|3@1+ (1.0,0.0) [0.0|7] ""  Vector__XXX

BO_ 1649 Klima_06: 8 Gateway_Max
 SG_ KL_ZZ_Minute : 0|6@1+ (1,0) [0|59] "Unit_Minut"  Vector__XXX
 SG_ KL_ZZ_Status_Timer : 6|2@1+ (1.0,0.0) [0.0|3] ""  Vector__XXX
 SG_ KL_ZZ_Monat : 8|4@1+ (1,0) [1|12] "Unit_Month"  Vector__XXX
 SG_ KL_ErwVK_Scheibenheizung : 12|1@1+ (1.0,0.0) [0.0|1] ""  Vector__XXX
 SG_ KL_ErwVK_Heckzone2_links : 13|1@1+ (1.0,0.0) [0.0|1] ""  Vector__XXX
 SG_ KL_ErwVK_Heckzone2_rechts : 14|1@1+ (1.0,0.0) [0.0|1] ""  Vector__XXX
 SG_ KL_ZZ_Stunde : 16|5@1+ (1,0) [0|23] "Unit_Hours"  Vector__XXX
 SG_ KL_ZZ_Betriebsmodus : 21|3@1+ (1.0,0.0) [0.0|7] ""  Vector__XXX
 SG_ KL_ZZ_Tag : 24|5@1+ (1,0) [1|31] "Unit_Day"  Vector__XXX
 SG_ KL_Betriebsmodus_FH : 29|3@1+ (1.0,0.0) [0.0|7] ""  Vector__XXX
 SG_ KL_Stopp_Wiederstart_Anz_01 : 32|1@1+ (1.0,0.0) [0.0|1] ""  Vector__XXX
 SG_ KL_Stopp_Wiederstart_Anz_02 : 33|1@1+ (1.0,0.0) [0.0|1] ""  Vector__XXX
 SG_ KL_Stopp_Wiederstart_Anz_03 : 34|1@1+ (1.0,0.0) [0.0|1] ""  Vector__XXX
 SG_ KL_Stopp_Wiederstart_Anz_04 : 35|1@1+ (1.0,0.0) [0.0|1] ""  Vector__XXX
 SG_ KL_Stopp_Wiederstart_Anz_05 : 36|1@1+ (1.0,0.0) [0.0|1] ""  Vector__XXX
 SG_ KL_Stopp_Wiederstart_Anz_06 : 37|1@1+ (1.0,0.0) [0.0|1] ""  Vector__XXX
 SG_ KL_Stopp_Wiederstart_Anz_07 : 38|1@1+ (1.0,0.0) [0.0|1] ""  Vector__XXX
 SG_ KL_Stopp_Wiederstart_Anz_08 : 39|1@1+ (1.0,0.0) [0.0|1] ""  Vector__XXX
 SG_ KL_Stopp_Wiederstart_Anz_09 : 40|1@1+ (1.0,0.0) [0.0|1] ""  Vector__XXX
 SG_ KL_Stopp_Wiederstart_Anz_Std1 : 41|1@1+ (1.0,0.0) [0.0|1] ""  Vector__XXX
 SG_ KL_Stopp_Wiederstart_Anz_Std2 : 42|1@1+ (1.0,0.0) [0.0|1] ""  Vector__XXX
 SG_ KL_STH_Betriebsdauer_lang : 43|7@1+ (1,0) [0|120] "Unit_Minut"  STH
 SG_ KL_Meldung_Status : 50|4@1+ (1.0,0.0) [0.0|15] ""  Vector__XXX
 SG_ KL_ErwVK_Status : 54|4@1+ (1.0,0.0) [0.0|15] ""  Vector__XXX
 SG_ KL_Hinweis_Kuehlmodus : 58|2@1+ (1.0,0.0) [0.0|3] ""  Vector__XXX
 SG_ KL_ErwVK_Beifahrerzone : 60|1@1+ (1.0,0.0) [0.0|1] ""  Vector__XXX
 SG_ KL_ErwVK_Fahrerzone : 61|1@1+ (1.0,0.0) [0.0|1] ""  Vector__XXX
 SG_ KL_ErwVK_Heckzone_links : 62|1@1+ (1.0,0.0) [0.0|1] ""  Vector__XXX
 SG_ Kl_ErwVK_Heckzone_rechts : 63|1@1+ (1.0,0.0) [0.0|1] ""  Vector__XXX

BO_ 949 Klima_11: 8 Gateway_Max
 SG_ KL_Drehz_Anh : 0|1@1+ (1.0,0.0) [0.0|1] ""  Vector__XXX
 SG_ KL_Vorwarn_Komp_ein : 1|1@1+ (1.0,0.0) [0.0|1] ""  Vector__XXX
 SG_ KL_AC_Schalter : 2|1@1+ (1.0,0.0) [0.0|1] ""  OCU
 SG_ KL_Komp_Moment_alt : 3|1@1+ (1.0,0.0) [0.0|1] ""  Vector__XXX
 SG_ KL_Vorwarn_Zuheizer_ein : 6|1@1+ (1.0,0.0) [0.0|1] ""  Vector__XXX
 SG_ KL_Zustand : 7|1@1+ (1.0,0.0) [0.0|1] ""  OCU
 SG_ KL_Kompressorkupplung_linear : 8|8@1+ (20,0) [0|4000] "Unit_MilliAmper"  Vector__XXX
 SG_ KL_Charisma_FahrPr : 16|4@1+ (1.0,0.0) [0.0|15] ""  Vector__XXX
 SG_ KL_Charisma_Status : 20|2@1+ (1.0,0.0) [0.0|3] ""  Vector__XXX
 SG_ KL_nachtr_Stopp_Anf : 22|1@1+ (1.0,0.0) [0.0|1] ""  Vector__XXX
 SG_ KL_T_Charge : 23|1@1+ (1.0,0.0) [0.0|1] ""  Vector__XXX
 SG_ KL_Last_Kompr : 24|8@1+ (0.25,0) [0.00|63.50] "Unit_NewtoMeter"  Vector__XXX
 SG_ KL_Spannungs_Anf : 32|2@1+ (1.0,0.0) [0.0|3] ""  Vector__XXX
 SG_ KL_Thermomanagement : 34|2@1+ (1.0,0.0) [0.0|3] ""  OCU,STH
 SG_ KL_StartStopp_Info : 36|2@1+ (1.0,0.0) [0.0|3] ""  OCU
 SG_ KL_Freilauf_Info : 38|2@1+ (1.0,0.0) [0.0|3] ""  Vector__XXX
 SG_ KL_Anf_KL : 40|8@1+ (0.4,0) [0.0|101.6] "Unit_PerCent"  Vector__XXX
 SG_ KL_el_Zuheizer_Stufe : 48|3@1+ (1.0,0.0) [0.0|7] ""  Vector__XXX
 SG_ KL_Ausstattung_Klima : 51|3@1+ (1.0,0.0) [0.0|7] ""  Vector__XXX
 SG_ KL_Variante_Standheizung : 54|2@1+ (1.0,0.0) [0.0|3] ""  Vector__XXX
 SG_ KL_AirCleaner_aktiv : 56|1@1+ (1.0,0.0) [0.0|1] ""  Vector__XXX
 SG_ KL_Anf_KV : 57|7@1+ (1,0) [0|100] "Unit_PerCent"  Vector__XXX

BO_ 1640 Klima_12: 8 Gateway_Max
 SG_ KL_LRH_Taster : 0|1@1+ (1.0,0.0) [0.0|1] ""  OCU
 SG_ KL_LRH_Stufe : 1|2@1+ (1.0,0.0) [0.0|3] ""  OCU
 SG_ HSH_Taster : 3|2@1+ (1.0,0.0) [0.0|3] ""  Vector__XXX
 SG_ FSH_Taster : 5|1@1+ (1.0,0.0) [0.0|1] ""  Vector__XXX
 SG_ KL_Zuheizer_Freigabe : 6|1@1+ (1.0,0.0) [0.0|1] ""  LSH,STH
 SG_ KL_Beschlagsgefahr : 7|1@1+ (1.0,0.0) [0.0|1] ""  Vector__XXX
 SG_ KL_SIH_Soll_li : 8|3@1+ (1,0) [0|6] ""  OCU
 SG_ KL_SIH_Soll_re : 11|3@1+ (1,0) [0|6] ""  OCU
 SG_ KRH_Soll_li : 14|2@1+ (1.0,0.0) [0.0|3] ""  Vector__XXX
 SG_ KL_SIL_Soll_li : 16|3@1+ (1,0) [0|6] ""  OCU
 SG_ KL_SIL_Soll_re : 19|3@1+ (1,0) [0|6] ""  OCU
 SG_ KRH_Soll_re : 22|2@1+ (1.0,0.0) [0.0|3] ""  Vector__XXX
 SG_ KL_Geblspng_Soll : 24|8@1+ (0.05,1.45) [1.50|14.00] "Unit_Volt"  ZR_MIB_EINSTIEG_ab_Gen3,ZR_MIB_TOP_ab_Gen3
 SG_ KL_Geblspng_Fond_Soll : 32|8@1+ (0.05,1.45) [1.50|14.00] "Unit_Volt"  ZR_MIB_TOP_ab_Gen3
 SG_ KL_I_Geblaese : 40|8@1+ (0.25,0) [0.00|63.50] "Unit_Amper"  ZR_MIB_TOP_ab_Gen3
 SG_ KL_Kompressorstrom_soll : 48|10@1+ (1,0) [0|1021] ""  Vector__XXX
 SG_ KL_Umluftklappe_Status : 58|4@1+ (1.0,0.0) [0.0|15] ""  OCU
 SG_ KL_PTC_Verbauinfo : 62|2@1+ (1.0,0.0) [0.0|3] ""  Vector__XXX

BO_ 2527679635 Klima_16: 8 Gateway_Max
 SG_ KL_Voko_Status : 0|4@1+ (1.0,0.0) [0.0|15] ""  Vector__XXX
 SG_ KL_LRH_PWM : 4|7@1+ (1,0) [0|100] "Unit_PerCent"  Vector__XXX
 SG_ KL_LRH_Soll : 11|1@1+ (1.0,0.0) [0.0|1] ""  Vector__XXX
 SG_ KL_AL_VR_Anf : 12|2@1+ (1.0,0.0) [0.0|3] ""  Vector__XXX
 SG_ KL_AL_VL_Anf : 14|2@1+ (1.0,0.0) [0.0|3] ""  Vector__XXX
 SG_ KL_AL_HR_Anf : 16|2@1+ (1.0,0.0) [0.0|3] ""  Vector__XXX
 SG_ KL_AL_HL_Anf : 18|2@1+ (1.0,0.0) [0.0|3] ""  Vector__XXX
 SG_ KL_HSH_Soll : 20|1@1+ (1.0,0.0) [0.0|1] ""  Vector__XXX
 SG_ KL_FSH_Soll : 21|1@1+ (1.0,0.0) [0.0|1] ""  Vector__XXX
 SG_ KL_ZR_Anforderung : 22|2@1+ (1.0,0.0) [0.0|3] ""  ZR_MIB_EINSTIEG_ab_Gen3,ZR_MIB_OPTION_ab_Gen3,ZR_MIB_TOP_ab_Gen3
 SG_ KL_VoKo_LED : 24|1@1+ (1.0,0.0) [0.0|1] ""  Vector__XXX
 SG_ KL_Defrost_LED : 25|1@1+ (1.0,0.0) [0.0|1] ""  Vector__XXX
 SG_ KL_HSH_LED : 26|1@1+ (1.0,0.0) [0.0|1] ""  Vector__XXX
 SG_ HSH_Relais_Anf : 27|1@1+ (1.0,0.0) [0.0|1] ""  Vector__XXX
 SG_ FSH_Status : 28|2@1+ (1.0,0.0) [0.0|3] ""  Vector__XXX
 SG_ SIH_Stufe_LED_li : 30|3@1+ (1.0,0.0) [0.0|7] ""  Vector__XXX
 SG_ SIH_Stufe_LED_re : 33|3@1+ (1.0,0.0) [0.0|7] ""  Vector__XXX
 SG_ KL_FSH_LED : 36|1@1+ (1.0,0.0) [0.0|1] ""  Vector__XXX
 SG_ KL_HUP_aktiv : 37|1@1+ (1.0,0.0) [0.0|1] ""  STH
 SG_ KL_LSH_DBetr_Ein : 38|1@1+ (1.0,0.0) [0.0|1] ""  LSH
 SG_ KL_LSH_DBetr_Bestaet : 39|1@1+ (1.0,0.0) [0.0|1] ""  LSH
 SG_ KL_Klappe_Status : 40|3@1+ (1.0,0.0) [0.0|7] ""  LSH
 SG_ KL_LSH_Ansteuerung : 43|2@1+ (1.0,0.0) [0.0|3] ""  LSH
 SG_ KL_Heizstufe_LSH : 45|4@1+ (1.0,0.0) [0.0|15] ""  LSH
 SG_ KL_LSH_Betriebsdauer : 49|7@1+ (1,0) [0|120] "Unit_Minut"  LSH,STH
 SG_ KL_Temp_ZH_Soll : 56|8@1+ (0.5,0) [0.5|127.0] "Unit_DegreCelsi"  STH

BO_ 2589283627 Klima_EV_06: 8 Gateway_Max
 SG_ KL_HVH_1_VerbautStatus : 0|1@1+ (1.0,0.0) [0.0|1] ""  Vector__XXX
 SG_ KL_EKK_1_VerbautStatus : 1|1@1+ (1.0,0.0) [0.0|1] ""  Vector__XXX
 SG_ KL_Texte : 12|2@1+ (1.0,0.0) [0.0|3] ""  ZR_MIB_EINSTIEG_ab_Gen3,ZR_MIB_OPTION_ab_Gen3
 SG_ KL_HVH_2_VerbautStatus : 14|1@1+ (1.0,0.0) [0.0|1] ""  Vector__XXX
 SG_ KL_EKK_2_VerbautStatus : 15|1@1+ (1.0,0.0) [0.0|1] ""  Vector__XXX
 SG_ KL_Leistung_Klima_Anf : 16|8@1+ (50,0) [0|12650] "Unit_Watt"  Vector__XXX
 SG_ KL_Heizen_Status : 24|4@1+ (1.0,0.0) [0.0|15] ""  Vector__XXX
 SG_ KL_K_Status : 28|4@1+ (1.0,0.0) [0.0|15] ""  Vector__XXX
 SG_ KL_Status_Battkuehlung : 32|3@1+ (1.0,0.0) [0.0|7] ""  Vector__XXX
 SG_ Kl_Klima_Aktiv : 35|1@1+ (1.0,0.0) [0.0|1] ""  Vector__XXX
 SG_ KL_Kuehlungs_Status : 36|4@1+ (1.0,0.0) [0.0|15] ""  Vector__XXX
 SG_ KL_HV_Energie_Anf : 40|8@1+ (50,0) [0|12600] "Unit_WattHour"  Vector__XXX
 SG_ TME_HVEM_HV_Anf : 48|2@1+ (1.0,0.0) [0.0|3] ""  Vector__XXX
 SG_ KL_IstLeistung : 50|8@1+ (50,0) [0|12650] "Unit_Watt"  OCU
 SG_ KL_Temp_Kundenwunsch : 58|6@1+ (0.5,15) [16.0|29.5] "Unit_DegreCelsi"  OCU

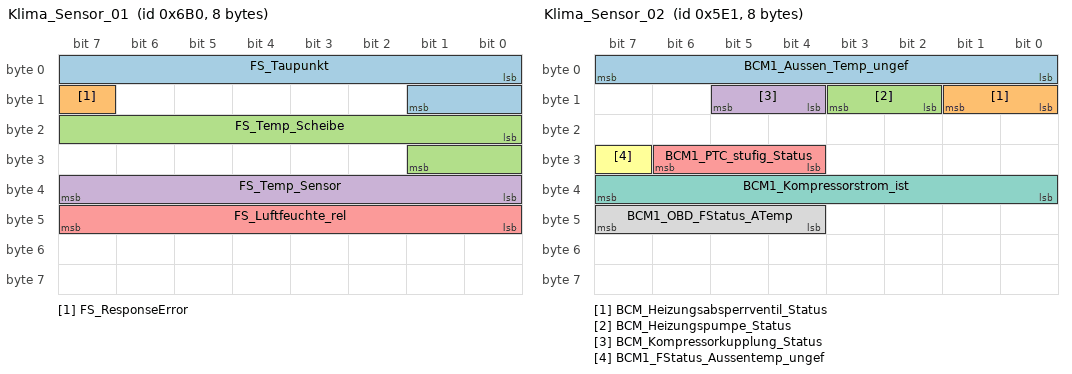
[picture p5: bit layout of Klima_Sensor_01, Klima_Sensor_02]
BO_ 1712 Klima_Sensor_01: 8 Gateway_Max
 SG_ FS_Taupunkt : 0|10@1+ (0.1,-39.6) [-39.5|60.4] "Unit_DegreCelsi"  Vector__XXX
 SG_ FS_ResponseError : 15|1@1+ (1.0,0.0) [0.0|1] ""  Vector__XXX
 SG_ FS_Temp_Scheibe : 16|10@1+ (0.1,-39.6) [-39.5|60.4] "Unit_DegreCelsi"  Vector__XXX
 SG_ FS_Temp_Sensor : 32|8@1+ (0.5,-40) [-39.5|87.0] "Unit_DegreCelsi"  Vector__XXX
 SG_ FS_Luftfeuchte_rel : 40|8@1+ (0.5,-0.5) [0.0|100.0] "Unit_PerCent"  OCU

BO_ 1505 Klima_Sensor_02: 8 Gateway_Max
 SG_ BCM1_Aussen_Temp_ungef : 0|8@1+ (0.5,-50) [-50.0|76.0] "Unit_DegreCelsi"  LSH,OCU,STH
 SG_ BCM_Heizungsabsperrventil_Status : 8|2@1+ (1.0,0.0) [0.0|3] ""  Vector__XXX
 SG_ BCM_Heizungspumpe_Status : 10|2@1+ (1.0,0.0) [0.0|3] ""  Vector__XXX
 SG_ BCM_Kompressorkupplung_Status : 12|2@1+ (1.0,0.0) [0.0|3] ""  Vector__XXX
 SG_ BCM1_PTC_stufig_Status : 28|3@1+ (1.0,0.0) [0.0|7] ""  Vector__XXX
 SG_ BCM1_FStatus_Aussentemp_ungef : 31|1@1+ (1.0,0.0) [0.0|1] ""  OCU
 SG_ BCM1_Kompressorstrom_ist : 32|8@1+ (4,0) [0|1000] "Unit_MilliAmper"  Vector__XXX
 SG_ BCM1_OBD_FStatus_ATemp : 44|4@1+ (1.0,0.0) [0.0|15] ""  OCU

BO_ 1717 Klima_Sensor_03: 8 Gateway_Max
 SG_ FSA_Taupunkt : 0|10@1+ (0.1,-40) [-40.0|60.0] "Unit_DegreCelsi"  Vector__XXX
 SG_ FSA_Err_Defekt_Tsens_TF : 10|1@1+ (1.0,0.0) [0.0|1] ""  Vector__XXX
 SG_ FSA_Luftfeuchte_TNCTOC : 11|1@1+ (1.0,0.0) [0.0|1] ""  Vector__XXX
 SG_ FSA_Luftfeuchte_TF : 12|1@1+ (1.0,0.0) [0.0|1] ""  Vector__XXX
 SG_ FSA_Err_Unterspannung_TF : 13|1@1+ (1.0,0.0) [0.0|1] ""  Vector__XXX
 SG_ FSA_Err_RAMROM_Check_TF : 14|1@1+ (1.0,0.0) [0.0|1] ""  Vector__XXX
 SG_ FSA_ResponseError : 15|1@1+ (1.0,0.0) [0.0|1] ""  Vector__XXX
 SG_ FSA_Temp_Luft : 16|10@1+ (0.1,-40) [-40.0|61.0] "Unit_DegreCelsi"  Vector__XXX
 SG_ FSA_Err_RAMROM_Check_TNCTOC : 26|1@1+ (1.0,0.0) [0.0|1] ""  Vector__XXX
 SG_ FSA_Err_Ueberspannung_TF : 30|1@1+ (1.0,0.0) [0.0|1] ""  Vector__XXX
 SG_ FSA_Luftfeuchte_rel : 32|8@1+ (0.5,0) [0.0|126.0] "Unit_PerCent"  OCU
 SG_ FSA_HW : 40|4@1+ (1,0) [0|15] ""  Vector__XXX
 SG_ FSA_SW : 44|4@1+ (1,0) [0|15] ""  Vector__XXX
 SG_ FSA_Temp_Sensor : 48|11@1+ (0.1,-40) [-40.0|90.0] "Unit_DegreCelsi"  OCU
 SG_ FSA_Sensorheizung_Status : 59|1@1+ (1.0,0.0) [0.0|1] ""  Vector__XXX
 SG_ FSA_Err_Defekt_HumSense_TF : 60|1@1+ (1.0,0.0) [0.0|1] ""  Vector__XXX
 SG_ FSA_Err_Defekt_HumSens_TNCTOC : 61|1@1+ (1.0,0.0) [0.0|1] ""  Vector__XXX
 SG_ FSA_ErrMemState : 62|2@1+ (1.0,0.0) [0.0|3] ""  Vector__XXX

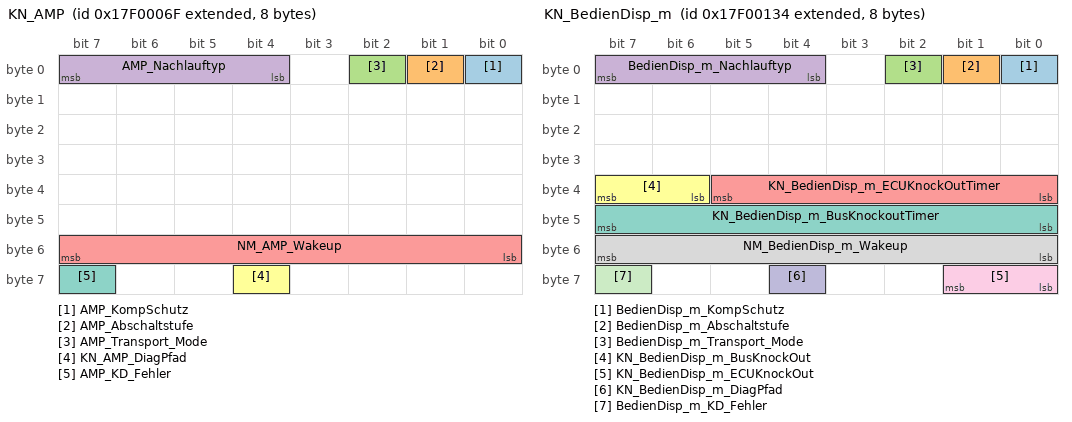
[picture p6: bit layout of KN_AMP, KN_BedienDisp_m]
BO_ 2549088367 KN_AMP: 8 Sound_MIB_ab_Gen3
 SG_ AMP_KompSchutz : 0|1@1+ (1.0,0.0) [0.0|1] ""  Vector__XXX
 SG_ AMP_Abschaltstufe : 1|1@1+ (1.0,0.0) [0.0|1] ""  Vector__XXX
 SG_ AMP_Transport_Mode : 2|1@1+ (1.0,0.0) [0.0|1] ""  Vector__XXX
 SG_ AMP_Nachlauftyp : 4|4@1+ (1.0,0.0) [0.0|15] ""  Gateway_Max
 SG_ NM_AMP_Wakeup : 48|8@1+ (1.0,0.0) [0.0|255] ""  Vector__XXX
 SG_ KN_AMP_DiagPfad : 60|1@1+ (1.0,0.0) [0.0|1] ""  Gateway_Max
 SG_ AMP_KD_Fehler : 63|1@1+ (1.0,0.0) [0.0|1] ""  Gateway_Max

BO_ 2549088564 KN_BedienDisp_m: 8 BedienDisp_mi
 SG_ BedienDisp_m_KompSchutz : 0|1@1+ (1.0,0.0) [0.0|1] ""  Vector__XXX
 SG_ BedienDisp_m_Abschaltstufe : 1|1@1+ (1.0,0.0) [0.0|1] ""  Vector__XXX
 SG_ BedienDisp_m_Transport_Mode : 2|1@1+ (1.0,0.0) [0.0|1] ""  Vector__XXX
 SG_ BedienDisp_m_Nachlauftyp : 4|4@1+ (1.0,0.0) [0.0|15] ""  Gateway_Max
 SG_ KN_BedienDisp_m_ECUKnockOutTimer : 32|6@1+ (1,0) [0|62] "Unit_Minut"  Vector__XXX
 SG_ KN_BedienDisp_m_BusKnockOut : 38|2@1+ (1.0,0.0) [0.0|3] ""  Vector__XXX
 SG_ KN_BedienDisp_m_BusKnockoutTimer : 40|8@1+ (1,0) [0|254] ""  Vector__XXX
 SG_ NM_BedienDisp_m_Wakeup : 48|8@1+ (1.0,0.0) [0.0|255] ""  Vector__XXX
 SG_ KN_BedienDisp_m_ECUKnockOut : 56|2@1+ (1.0,0.0) [0.0|3] ""  Vector__XXX
 SG_ KN_BedienDisp_m_DiagPfad : 60|1@1+ (1.0,0.0) [0.0|1] ""  Gateway_Max
 SG_ BedienDisp_m_KD_Fehler : 63|1@1+ (1.0,0.0) [0.0|1] ""  Gateway_Max

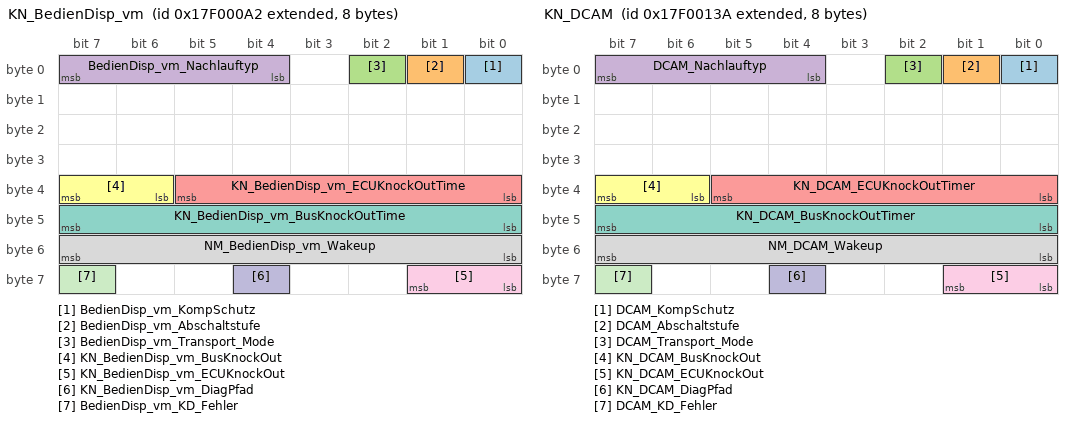
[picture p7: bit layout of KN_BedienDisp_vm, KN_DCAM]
BO_ 2549088418 KN_BedienDisp_vm: 8 BedienDisp_vo_mi
 SG_ BedienDisp_vm_KompSchutz : 0|1@1+ (1.0,0.0) [0.0|1] ""  Vector__XXX
 SG_ BedienDisp_vm_Abschaltstufe : 1|1@1+ (1.0,0.0) [0.0|1] ""  Vector__XXX
 SG_ BedienDisp_vm_Transport_Mode : 2|1@1+ (1.0,0.0) [0.0|1] ""  Vector__XXX
 SG_ BedienDisp_vm_Nachlauftyp : 4|4@1+ (1.0,0.0) [0.0|15] ""  Gateway_Max
 SG_ KN_BedienDisp_vm_ECUKnockOutTime : 32|6@1+ (1,0) [0|62] "Unit_Minut"  Vector__XXX
 SG_ KN_BedienDisp_vm_BusKnockOut : 38|2@1+ (1.0,0.0) [0.0|3] ""  Vector__XXX
 SG_ KN_BedienDisp_vm_BusKnockOutTime : 40|8@1+ (1,0) [0|254] ""  Vector__XXX
 SG_ NM_BedienDisp_vm_Wakeup : 48|8@1+ (1.0,0.0) [0.0|255] ""  Vector__XXX
 SG_ KN_BedienDisp_vm_ECUKnockOut : 56|2@1+ (1.0,0.0) [0.0|3] ""  Vector__XXX
 SG_ KN_BedienDisp_vm_DiagPfad : 60|1@1+ (1.0,0.0) [0.0|1] ""  Gateway_Max
 SG_ BedienDisp_vm_KD_Fehler : 63|1@1+ (1.0,0.0) [0.0|1] ""  Gateway_Max

BO_ 2549088570 KN_DCAM: 8 DashCAM
 SG_ DCAM_KompSchutz : 0|1@1+ (1.0,0.0) [0.0|1] ""  Vector__XXX
 SG_ DCAM_Abschaltstufe : 1|1@1+ (1.0,0.0) [0.0|1] ""  Vector__XXX
 SG_ DCAM_Transport_Mode : 2|1@1+ (1.0,0.0) [0.0|1] ""  Vector__XXX
 SG_ DCAM_Nachlauftyp : 4|4@1+ (1.0,0.0) [0.0|15] ""  Gateway_Max
 SG_ KN_DCAM_ECUKnockOutTimer : 32|6@1+ (1,0) [0|62] "Unit_Minut"  Vector__XXX
 SG_ KN_DCAM_BusKnockOut : 38|2@1+ (1.0,0.0) [0.0|3] ""  Vector__XXX
 SG_ KN_DCAM_BusKnockOutTimer : 40|8@1+ (1,0) [0|254] ""  Vector__XXX
 SG_ NM_DCAM_Wakeup : 48|8@1+ (1.0,0.0) [0.0|255] ""  Vector__XXX
 SG_ KN_DCAM_ECUKnockOut : 56|2@1+ (1.0,0.0) [0.0|3] ""  Vector__XXX
 SG_ KN_DCAM_DiagPfad : 60|1@1+ (1.0,0.0) [0.0|1] ""  Gateway_Max
 SG_ DCAM_KD_Fehler : 63|1@1+ (1.0,0.0) [0.0|1] ""  Gateway_Max

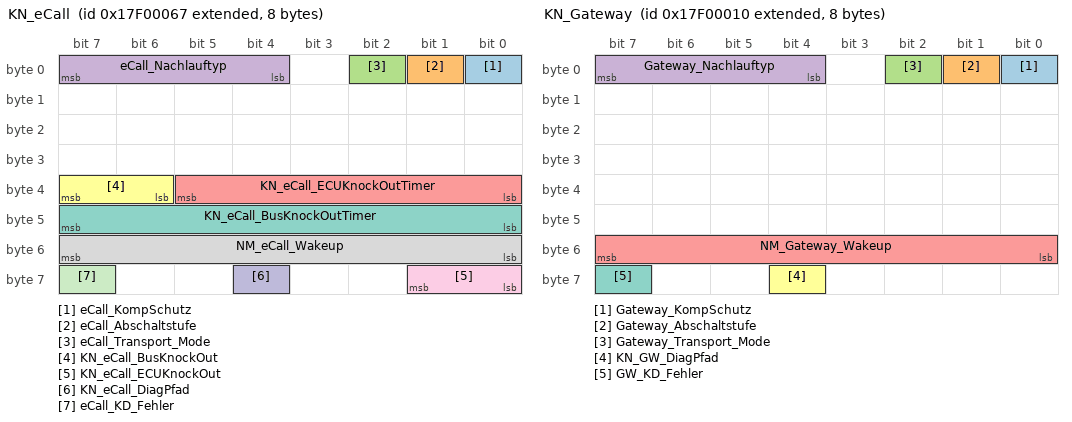
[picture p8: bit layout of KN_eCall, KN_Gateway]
BO_ 2549088359 KN_eCall: 8 ConMod_CD
 SG_ eCall_KompSchutz : 0|1@1+ (1.0,0.0) [0.0|1] ""  Vector__XXX
 SG_ eCall_Abschaltstufe : 1|1@1+ (1.0,0.0) [0.0|1] ""  Vector__XXX
 SG_ eCall_Transport_Mode : 2|1@1+ (1.0,0.0) [0.0|1] ""  Vector__XXX
 SG_ eCall_Nachlauftyp : 4|4@1+ (1.0,0.0) [0.0|15] ""  Gateway_Max
 SG_ KN_eCall_ECUKnockOutTimer : 32|6@1+ (1,0) [0|62] "Unit_Minut"  Vector__XXX
 SG_ KN_eCall_BusKnockOut : 38|2@1+ (1.0,0.0) [0.0|3] ""  Vector__XXX
 SG_ KN_eCall_BusKnockOutTimer : 40|8@1+ (1,0) [0|254] ""  Vector__XXX
 SG_ NM_eCall_Wakeup : 48|8@1+ (1.0,0.0) [0.0|255] ""  Vector__XXX
 SG_ KN_eCall_ECUKnockOut : 56|2@1+ (1.0,0.0) [0.0|3] ""  Vector__XXX
 SG_ KN_eCall_DiagPfad : 60|1@1+ (1.0,0.0) [0.0|1] ""  Gateway_Max
 SG_ eCall_KD_Fehler : 63|1@1+ (1.0,0.0) [0.0|1] ""  Gateway_Max

BO_ 2549088272 KN_Gateway: 8 Gateway_Max
 SG_ Gateway_KompSchutz : 0|1@1+ (1.0,0.0) [0.0|1] ""  Vector__XXX
 SG_ Gateway_Abschaltstufe : 1|1@1+ (1.0,0.0) [0.0|1] ""  Vector__XXX
 SG_ Gateway_Transport_Mode : 2|1@1+ (1.0,0.0) [0.0|1] ""  Vector__XXX
 SG_ Gateway_Nachlauftyp : 4|4@1+ (1.0,0.0) [0.0|15] ""  Vector__XXX
 SG_ NM_Gateway_Wakeup : 48|8@1+ (1.0,0.0) [0.0|255] ""  Vector__XXX
 SG_ KN_GW_DiagPfad : 60|1@1+ (1.0,0.0) [0.0|1] ""  Vector__XXX
 SG_ GW_KD_Fehler : 63|1@1+ (1.0,0.0) [0.0|1] ""  Vector__XXX

BO_TX_BU_ 2463978722 :Gateway_Max,OCU;
BO_TX_BU_ 2463978723 :Gateway_Max,OCU;
BO_TX_BU_ 2463978724 :Gateway_Max,OCU;
BO_TX_BU_ 2463978726 :Gateway_Max,OCU;
BO_TX_BU_ 2583720728 :ICC_IO_Node,ZR_MIB_EINSTIEG_ab_Gen3,ZR_MIB_OPTION_ab_Gen3,ZR_MIB_TOP_ab_Gen3;
BO_TX_BU_ 2001 :ConMod_CD,OCU;
BO_TX_BU_ 2549485315 :ConMod_CD,OCU;
BO_TX_BU_ 2013 :ZR_MIB_EINSTIEG_ab_Gen3,ZR_MIB_OPTION_ab_Gen3,ZR_MIB_TOP_ab_Gen3;
BO_TX_BU_ 2549354243 :ConMod_CD,OCU;
BO_TX_BU_ 2550005925 :ZR_MIB_OPTION_ab_Gen3,ZR_MIB_TOP_ab_Gen3;
BO_TX_BU_ 2549088359 :ConMod_CD,OCU;
CM_ BO_ 886 "Nachricht 3 für Ortung:
Qualität der Ortung.";
CM_ BO_ 888 "Nachricht 4 für Ortung:
Zeitstempel der Ortung.";
CM_ BO_ 891 "Nachricht 5:
Empfängerstatus und UTC.";
CM_ BO_ 1364 "Nachricht 6:
Enthält Informationen über die Satelliten. Die Daten des stärksten Satelliten werden übertragen";
CM_ BO_ 1343 "Nachricht 7:
Ermittlung genaue Geschwindigkeiten EURO/NCAP";
CM_ BO_ 960 "MQB";
CM_ BO_ 1646 "ab MQB 7.3";
CM_ BO_ 949 "ab MQB 7.4";
CM_ BO_ 1640 "ab MQB IS-4";
CM_ BO_ 1712 "1:1 LIN-CAN Botschaft, Originalsender ist Regen-/Licht-/Feuchtesensor auf dem BCM-LIN1";
CM_ BO_ 1505 "ab MQB 7.3";
CM_ BO_ 1717 "ab D4 gültig  --  geänderter Wertebereich und Signalnamen
1:1 LIN-CAN Botschaft vom BCM1, nur bei Kl.15 EIN gesendet";

CM_ SG_ 886 GNSS_Nachrichtenpaket_ID3 "+1 für jedes neue Paket. Zyklische ID-Vergabe (Zähler). Zur Identifizierung zusammenhängender Nachrichten, die die Daten derselben GNSS-Ortung enthalten und somit zum selben Zyklus gehören. D.h. Daten in den Nachrichten wurden zur selben Zeit erzeugt. Der";
CM_ SG_ 886 GNSS_Ortung_GDOP "Synthetischer Wert für den Verlust an Präzision der Postions- und Zeitmessung auf Grund der Satellitenkonstellation";
CM_ SG_ 886 GNSS_Ortung_Guete_Ausrichtung "Gesamtgenauigkeit bezüglich der Ausrichtung (Kurswinkel)";
CM_ SG_ 886 GNSS_Ortung_Guete_Geschwindigk "Gesamtgenauigkeit bezüglich Geschwindigkeit am Erdboden";
CM_ SG_ 886 GNSS_Ortung_Guete_horizontal "Gesamtgenauigkeit bezüglich der 2D-Position (horzontal)";
CM_ SG_ 886 GNSS_Ortung_Guete_vertikal "Gesamtgenauigkeit bezüglich der 1D-Position (vertikal)";
CM_ SG_ 886 GNSS_Ortung_HDOP "Synthetischer Wert für den Verlust an Präzision der 2D-Postionsmessung (horizontal) auf Grund der Satellitenkonstellation";
CM_ SG_ 886 GNSS_Ortung_PDOP "Synthetischer Wert für den Verlust an Präzision der Postionsmessung auf Grund der Satellitenkonstellation";
CM_ SG_ 886 GNSS_Ortung_VDOP "Synthetischer Wert für den Verlust an Präzision der 1D-Postionsmessung (vertikal) auf Grund der Satellitenkonstellation";

CM_ SG_ 888 GNSS_Nachrichtenpaket_ID4 "+1 für jedes neue Paket. Zyklische ID-Vergabe (Zähler). Zur Identifizierung zusammenhängender Nachrichten, die die Daten derselben GNSS-Ortung enthalten und somit zum selben Zyklus gehören. D.h. Daten in den Nachrichten wurden zur selben Zeit erzeugt. Der";
CM_ SG_ 888 GNSS_Ortung_Hoehe "Höhe über dem Meeresspiegel";
CM_ SG_ 888 GNSS_Ortung_Zeit_in_GPSWoche "Zeitstempel für die Jitter-Prüfung aso. Zeit muss sychron zur Zeit der GNSS-Ortung sein.";

CM_ SG_ 891 GNSS_Empfaenger_Status "Im 'Backup Mode' wird z.B. die UTC Zeit durch eine gepufferte 'Realtime Clock' bereitgestellt.
Im 'Live Mode' wird die UTC Zeit durch das GNSS Modul bereitgestellt. ";
CM_ SG_ 891 GNSS_Empfangbare_Satelliten "Anzahl der Satelliten, welche bei der aktuellen Satellitenkonfiguration ptentiell verfügbar sind";
CM_ SG_ 891 GNSS_Genutzte_Satelliten "Anzahl der Satelliten, welche für die aktuelle Ortung verwendet werden";
CM_ SG_ 891 GNSS_GLONASS_in_Nutzung "1: das genannte GNSS wurde für die Ortung verwendet";
CM_ SG_ 891 GNSS_GPS_in_Nutzung "1: das genannte GNSS wurde für die Ortung verwendet";
CM_ SG_ 891 GNSS_Nachrichtenpaket_ID5 "+1 für jedes neue Paket. Zyklische ID-Vergabe (Zähler). Zur Identifizierung zusammenhängender Nachrichten, die die Daten derselben GNSS-Ortung enthalten und somit zum selben Zyklus gehören. D.h. Daten in den Nachrichten wurden zur selben Zeit erzeugt. Der";
CM_ SG_ 891 GNSS_Sichtbare_Satelliten "Anzahl der Satelliten, welche aktuell empfangen werden";
CM_ SG_ 891 GNSS_UTC_Zeit "UTC-Zeit, Sekunden seit dem 01.01.1970 00:00";

CM_ SG_ 1364 GNSS_Nachrichtenpaket_ID6 "+1 für jedes neue Paket. Zyklische ID-Vergabe (Zähler). Zur Identifizierung zusammenhängender Nachrichten, die die Daten derselben GNSS-Ortung enthalten und somit zum selben Zyklus gehören. D.h. Daten in den Nachrichten wurden zur selben Zeit erzeugt. Der";
CM_ SG_ 1364 GNSS_Sat_Info_Azimuth_ID_1 "Azimut des Satelliten";
CM_ SG_ 1364 GNSS_Sat_Info_Hoehenwinkel_ID_1 "Höhenwinkel des Satelliten";
CM_ SG_ 1364 GNSS_Sat_Info_Sat_ID_1 "ID des Satelliten";
CM_ SG_ 1364 GNSS_Sat_Info_SNR_ID_1 "Signal-Rausch-Verhältnis des Satelliten";

CM_ SG_ 1343 GNSS_Nachrichtenpaket_ID7 "+1 für jedes neue Paket. Zyklische ID-Vergabe (Zähler). Zur Identifizierung zusammenhängender Nachrichten, die die Daten derselben GNSS-Ortung enthalten und somit zum selben Zyklus gehören. D.h. Daten in den Nachrichten wurden zur selben Zeit erzeugt. Der";
CM_ SG_ 1343 GNSS_V_Daten_Veraltet "Gibt an, ob der Sendezyklus einen neuen Datensatz vom GNSS-Chip enthält. Das heißt, der Datensatz wurde noch nicht in einem Zyklus zuvor verwendet.
Veraltet = Datensatz ist veraltet
Neu = Datensatz ist neu";
CM_ SG_ 1343 GNSS_V_FIX_Typ "Art des 'GNSS-Fix' für die aktuelle Position.";
CM_ SG_ 1343 GNSS_V_Geschw_2D "2D-Geschwindigkeit in m pro Sekunde entsprechend dem GNSS-Empfänger (= 2D-Geschwindigkeit bzgl. WGS-Oberfläche, WGS Geschwindigkeit über Grund)";
CM_ SG_ 1343 GNSS_V_Geschw_2D_Guete95 "Geschätzte Genauigkeit der 2D-Geschwindigkeit vom GNSS-Empfänger
Geforderte Konfidenz = 95%.";
CM_ SG_ 1343 GNSS_V_Geschw_Vertikal "Geschwindigkeit  in m pro Sekunde in vertikaler Richtung (aufwärts, vertikal bzgl. WGS-Oberfläche) entsprechend dem GNSS-Empfänger";
CM_ SG_ 1343 GNSS_V_Geschw_Vertikal_Guete95 "Geschätzte Genauigkeit der vertikalen GNSS-Geschwindigkeit (vertikal bzgl. WGS-Oberfläche). 
Geforderte Konfidenz = 95%.";
CM_ SG_ 1343 GNSS_V_Latenz_vollstaendig "Vollständige Latenz zwischen GNSS-Messung und aktueller Verteilung über CAN-Bus.
Wert = Latenz 1 + Latenz2; 
Latenz1 = interne Chip-Latenz (Zeidbedarf der GNSS-Messung; =Alter des GNSS-Zeitstempels beim Empfang am GNSS-Chip); 
Latenz2 =  Restzeit (Zeit";

CM_ SG_ 2463978722 GNSS_DR_Breite_Ortung "Dead Reckoning Breitengrad des Ortungsergebnisses nach WGS84 als Kombination von mehreren GNSSen";
CM_ SG_ 2463978722 GNSS_DR_Laenge_Ortung "Dead Reckoning Längengrad des Ortungsergebnisses nach WGS84 als Kombination von mehreren GNSSen";
CM_ SG_ 2463978722 GNSS_DR_Nachrichtenpaket_ID1 "+1 für jedes neue Paket. Zyklische ID-Vergabe (Zähler). Zur Identifizierung zusammenhängender Nachrichten, die die Daten derselben GNSS-Ortung enthalten und somit zum selben Zyklus gehören. D.h. Daten in den Nachrichten wurden zur selben Zeit erzeugt. Der";
CM_ SG_ 2463978722 GNSS_DR_Richtung_Breite_Ortung "Dead Reckoning Richtung des Breitengrads des Ortungsergebnisses nach WGS84 als Kombination von mehreren GNSSen";
CM_ SG_ 2463978722 GNSS_DR_Richtung_Laenge_Ortung "Dead Reckoning Richtung des Längengrads des Ortungsergebnisses nach WGS84 als Kombination von mehreren GNSSen";

CM_ SG_ 2463978723 GNSS_DR_Nachrichtenpaket_ID2 "+1 für jedes neue Paket. Zyklische ID-Vergabe (Zähler). Zur Identifizierung zusammenhängender Nachrichten, die die Daten derselben GNSS-Ortung enthalten und somit zum selben Zyklus gehören. D.h. Daten in den Nachrichten wurden zur selben Zeit erzeugt. Der";
CM_ SG_ 2463978723 GNSS_DR_Ortung_2D_Geschw_u_Grund "Dead Reckoning Geschwindigkeit in m pro Sekunde";
CM_ SG_ 2463978723 GNSS_DR_Ortung_Ausrichtung "Dead Reckoning Ausrichtung (Kurswinkel) der GNSS-Messung";

CM_ SG_ 2463978724 GNSS_DR_Nachrichtenpaket_ID3 "+1 für jedes neue Paket. Zyklische ID-Vergabe (Zähler). Zur Identifizierung zusammenhängender Nachrichten, die die Daten derselben GNSS-Ortung enthalten und somit zum selben Zyklus gehören. D.h. Daten in den Nachrichten wurden zur selben Zeit erzeugt. Der";
CM_ SG_ 2463978724 GNSS_DR_Ortung_Guete_Ausrichtung "Dead Reckoning Gesamtgenauigkeit bezüglich der Ausrichtung (Kurswinkel)";
CM_ SG_ 2463978724 GNSS_DR_Ortung_Guete_Geschwindig "Dead Reckoning Gesamtgenauigkeit bezüglich Geschwindigkeit am Erdboden";
CM_ SG_ 2463978724 GNSS_DR_Ortung_Guete_horizontal "Dead Reckoning Gesamtgenauigkeit bezüglich der 2D-Position (horzontal)";
CM_ SG_ 2463978724 GNSS_DR_Ortung_Guete_vertikal "Dead Reckoning Gesamtgenauigkeit bezüglich der 1D-Position (vertikal)";

CM_ SG_ 2463978726 GNSS_DR_UTC_Zeit "Dead Reckoning UTC-Zeit, Sekunden seit dem 01.01.1970 00:00";

CM_ SG_ 299 GRA_Abbrechen "GRA : aus mit speichern
ACC : Soft aus";
CM_ SG_ 299 GRA_ACC_01_BZ "4bit Botschaftszaehler, wird mit jeder Sendebotschaft inkrementiert";
CM_ SG_ 299 GRA_ACC_01_CRC "Für MLB:
'Berechnung siehe Lastenheft 'Kommunikationsabsicherung für FlexRay und CAN''

Ab MQB und MLBevo:
'Berechnung siehe Lastenheft 'End-to-End Kommunikationsabsicherung''

Endwerte siehe Begleitdokument 'S-PDU Kennungsfolgen'";
CM_ SG_ 299 GRA_Codierung "Das Signal zeigt an, ob das Sende-SG (SMLS/MFL) auf GRA- oder ACC-Bedienteil codiert ist:
0: kein GRA- oder ACC Bedienteil
1: GRA-Bedienteil
2: ACC-Bedienteil
3: Limiter_Only-Bedienteil";
CM_ SG_ 299 GRA_Fehler "Das Signal zeigt an, dass das Sende-SG (SMLS/MFG) einen Defekt des GRA-Bedienteils erkannt hat und hierzu ein FSPE abgelegt wurde.";
CM_ SG_ 299 GRA_Hauptschalter "Stellung des GRA/ACC-Hauptschalters: 
Bei gerastetem Hauptschalter:
0: Hauptschalter aus
1: Hauptschalter ein
Bei getastetem Hauptschalter:
0: Taster nicht betätigt
1: Taster betätigt";
CM_ SG_ 299 GRA_LIM_Taste_verfuegbar "Das Signal zeigt an, ob eine Limiter-Umschalttaste am jeweiligen GRA/ACC-Bedienelement vorhanden ist.";
CM_ SG_ 299 GRA_Limiter "Stellung des Limiter-Tasters";
CM_ SG_ 299 GRA_PIT_Limiter "Stellung der Taste PIT-Speed-Limiter";
CM_ SG_ 299 GRA_reserveByte5 "Zweck: Befüllen der reservierten Bitpositionen mit 0 (wg. LIN-Teilnehmer MFL)";
CM_ SG_ 299 GRA_reserveByte6 "Zweck: Befüllen der reservierten Bitpositionen mit 0 (wg. LIN-Teilnehmer MFL)";
CM_ SG_ 299 GRA_reserveByte7 "Zweck: Befüllen der reservierten Bitpositionen mit 0 (wg. LIN-Teilnehmer MFL)";
CM_ SG_ 299 GRA_reserveByte8 "Zweck: Befüllen der reservierten Bitpositionen mit 0 (wg. LIN-Teilnehmer MFL)";
CM_ SG_ 299 GRA_Tip_Hoch "Tippschalter Tip Up / Geschwindigkeit erhöhen";
CM_ SG_ 299 GRA_Tip_Runter "Tippschalter Tip Down / Geschwindigkeit reduzieren";
CM_ SG_ 299 GRA_Tip_Setzen "Tippschalter Set";
CM_ SG_ 299 GRA_Tip_Stufe_2 "Signal zeigt an, dass der zweistufige GRA/ACC-Hebel (8_Positions_Bedienteil) in der 2. Tip-Stufe betätigt wird. Das Signal wird nur gleichzeitig mit dem Signal GRA_Tip_Hoch oder GRA_Tip_Runter gesetzt, wobei die Bits GRA_Tip_Hoch bzw. GRA_Tip_Runter die R";
CM_ SG_ 299 GRA_Tip_Wiederaufnahme "Tippschalter Wiederaufnahme";
CM_ SG_ 299 GRA_TravelAssist "Taste für TravelAssist";
CM_ SG_ 299 GRA_Typ_Bedienteil "Das Signal kennzeichnet die Variante des GRA/ACC-Bedienteils:
0: Init
1: 4-Positionen-Bedienteil (z.B. GRA im Blinkerhebel)
2: 6-Positionen-Bedienteil (GRA/ACC-Bedienteil mit separaten Stellungen für Set/Resume/TipUp/TipDown) 
3: 8-Positionen-Bediente";
CM_ SG_ 299 GRA_Typ_Hauptschalter "Variante des GRA/ACC-Hauptschalters:
0: gerasteter Hauptschalter (bzw. Taster mit Speicherung des Status im SMLS (PAG))
1: getasteter Hauptschalter, keine Speicherung des Status im SMLS";
CM_ SG_ 299 GRA_Verstellung_Zeitluecke "Verstellung der Zeitlücke für ACC

DIST -1 = Zeitluecke um 1 Stufe kleiner
DIST +1 = Zeitluecke um 1 Stufe groeßer
DIST Toggle = Zeitlücke um 1 Stufe kleiner, von kleinster Stufe auf größte Stufe";

CM_ SG_ 29 WFS_IMMO_OCU_CRC "WFS_IMMO_OCU_CRC";
CM_ SG_ 29 WFS_IMMO_OCU_RND "WFS_IMMO_OCU_RND";

CM_ SG_ 2583720728 Info_El_AuthTime_Req_Data "AuthTime - Authentische Zeit
ISO-TP Datenkanal - NA2FID
Request Knoten 0x73 Info_El (Zentralrechner)

Zentralrechner an Funktion Authentische Zeit (Request)";

CM_ SG_ 2583851800 Info_El_AuthTime_Resp_Data "AuthTime - Authentische Zeit
ISO-TP Datenkanal - NA2FID
Response Funktion 0x18 AuthTime

Funktion Authentische Zeit an Zentralrechner (Response)";

CM_ SG_ 1895 ISO_eCall_Req_Data "OffBoard Tester Diagnose Request eCall";

CM_ SG_ 2001 ISO_eCall_Resp_Data "OffBoard Tester Diagnose Response eCall";

CM_ SG_ 2549351183 ISO_FoD_ManFoD_Req_Data "Function On Demand
ISO-TP Datenkanal - FID2FID
Request Funktion 0x03 FoD an Funktion 0x0F ManFoD
FoD Master -> FoD Manager";

CM_ SG_ 2549485315 ISO_FoD_ManFoD_Resp_Data "Function On Demand
ISO-TP Datenkanal - FID2FID
Response Funktion 0x0F ManFoD an Funktion 0x03 FoD
FoD Manager -> FoD Master";

CM_ SG_ 1792 ISO_ALL_01_Req_Data "Funktionaler Request ALL";

CM_ SG_ 1907 ISO_Info_El_Req_Data "OffBoard Tester Diagnose Request Info_El";

CM_ SG_ 2013 ISO_Info_El_Resp_Data "OffBoard Tester Diagnose Response Info_El";

CM_ SG_ 2549354243 ISO_ManFoD_FoD_Req_Data "Function On Demand
ISO-TP Datenkanal - FID2FID
Request Funktion 0x0F ManFoD an Funktion 0x03 FoD
FoD Manager -> FoD Master";

CM_ SG_ 2549482255 ISO_ManFoD_FoD_Resp_Data "Function On Demand
ISO-TP Datenkanal - FID2FID
Response Funktion 0x03 FoD an Funktion 0x0F ManFoD
FoD Master -> FoD Manager";

CM_ SG_ 1803 ISO_RDK_Req_Data "OffBoard Tester Diagnose Request RDK";

CM_ SG_ 1909 ISO_RDK_Resp_Data "OffBoard Tester Diagnose Response RDK";

CM_ SG_ 1898 ISO_STH_Req_Data "OffBoard Tester Diagnose Request STH";

CM_ SG_ 2004 ISO_STH_Resp_Data "OffBoard Tester Diagnose Response STH";

CM_ SG_ 1901 ISO_TV_Tuner_Req_Data "Diagnose Request TV-Tuner";

CM_ SG_ 2007 ISO_TV_Tuner_Resp_Data "Diagnose Response TV-Tuner";

CM_ SG_ 2550399028 ISOx_BedienDisp_m_Req_Data "Diagnose Request";

CM_ SG_ 2550530100 ISOx_BedienDisp_m_Resp_Data "Diagnose Response";

CM_ SG_ 2549874850 ISOx_BedienDisp_vm_Req_Data "Diagnose Request";

CM_ SG_ 2550005922 ISOx_BedienDisp_vm_Resp_Data "Diagnose Response";

CM_ SG_ 2549874852 ISOx_LSH_Req_Data "VWAG Diagnose";

CM_ SG_ 2550005924 ISOx_LSH_Resp_Data "VWAG Diagnose";

CM_ SG_ 2549874853 ISOx_WLC1_Req_Data "OffBoard Tester Diagnose Request WLC1";

CM_ SG_ 2550005925 ISOx_WLC1_Resp_Data "OffBoard Tester Diagnose Response WLC1";

CM_ SG_ 1426 KY_Aktive_LFScans "Signalisierung eines aktiven Kessy-Scans (LF auf 125kHz) mit Angabe der Scanart";
CM_ SG_ 1426 KY_AnzKoord_Info "Signalisierung, ob beim Kessy-Scan ein Schlüssel gefunden wurde (1) oder nicht (2)";
CM_ SG_ 1426 KY_EasyClose_Abbruch "ID-Geber während HD-Zufahrt im Nahbereich EasyClose erkannt";
CM_ SG_ 1426 KY_EasyClose_Status "Signal zur LED Ansteuerung im HD-Verriegelungstaster für die Funktion EasyClose.";
CM_ SG_ 1426 KY_Fzg_Verlassen_erkannt "Fahrer/Schlüssel hat das Fahrzeug verlassen und FT wurde geschlossen";
CM_ SG_ 1426 KY_Fzg_Zugang_erkannt "Fahrer/Schlüssel hat Fahrzeug betreten und die FT geschlossen";
CM_ SG_ 1426 KY_Gestik_HD "Aktive Funktion (Gestikgesteuerte Heckklappe) im Kessy-SG";
CM_ SG_ 1426 KY_Gong_600 "Gong zum Meldungstext (1=aktiv)";
CM_ SG_ 1426 KY_HD_Auffahrt "Auffahrt HD nach Wiedereintritt ID-Geber in EasyClose Nahbereich";
CM_ SG_ 1426 KY_HD_Zufahrt "Zufahrt HD nach erfolgreicher Funktion EasyClose";
CM_ SG_ 1426 KY_ID_Geber1_im_Fzg "1 = ID-Geber 1 im Innenraum erkannt";
CM_ SG_ 1426 KY_ID_Geber2_im_Fzg "1 = ID-Geber 2 im Innenraum erkannt";
CM_ SG_ 1426 KY_ID_Geber3_im_Fzg "1 = ID-Geber 3 im Innenraum erkannt";
CM_ SG_ 1426 KY_ID_Geber4_im_Fzg "1 = ID-Geber 4 im Innenraum erkannt";
CM_ SG_ 1426 KY_ID_Geber_Suche "1 = Transponder Scan aktiv";
CM_ SG_ 1426 KY_LF_Aktiv "LF Schluesselkommunikation
";
CM_ SG_ 1426 KY_Meldungen "Kessy-Meldungen:
0 = keine Meldung
1 = Meldung: 'Schlüssel nicht gefunden!' bei Kl.15 ein
2= Meldung: 'Schlüssel im Kofferraum!'
3 = Meldung: 'Schlüssel im Fahrzeug'
4 = Meldung: 'KESSY defekt'
5-15: tbd";
CM_ SG_ 1426 KY_Passiv_Autolock "Aktive Funktion (Passiv Autolock) im Kessy-SG";
CM_ SG_ 1426 KY_Passiv_Autolock_Akt "1 = Funktionszustand im Kessy-SG: 'Passiv Autolock / Autounlock'";
CM_ SG_ 1426 KY_Passiv_Autolock_Menue "1 = Menue-Eintrag 'Passiv Autolock / Autounlock' aktivieren";
CM_ SG_ 1426 KY_Passiv_Autounlock "Aktive Funktion (Passiv Autounlock) im Kessy-SG";
CM_ SG_ 1426 KY_Schluesselposition_1 "Status des ID-Gebers 1 aus der letzten durchgeführten Schlüsselsuche für Remote Parkfunktionen

0 = nicht_gefunden
1 = im_Innenraum_gefunden
2 = im_Außenraum_gefunden_nah, Distanz <= parametrierter Schwelle
3 = im_Außenraum_gefunden_fern, Distanz > p";
CM_ SG_ 1426 KY_Schluesselposition_2 "Status des ID-Gebers 2 aus der letzten durchgeführten Schlüsselsuche für Remote Parkfunktionen

0 = nicht_gefunden
1 = im_Innenraum_gefunden
2 = im_Außenraum_gefunden_nah, Distanz <= parametrierter Schwelle
3 = im_Außenraum_gefunden_fern, Distanz > p";
CM_ SG_ 1426 KY_Schluesselposition_3 "Status des ID-Gebers 3 aus der letzten durchgeführten Schlüsselsuche für Remote Parkfunktionen

0 = nicht_gefunden
1 = im_Innenraum_gefunden
2 = im_Außenraum_gefunden_nah, Distanz <= parametrierter Schwelle
3 = im_Außenraum_gefunden_fern, Distanz > p";
CM_ SG_ 1426 KY_Schluesselposition_4 "Status des ID-Gebers 4 aus der letzten durchgeführten Schlüsselsuche für Remote Parkfunktionen

0 = nicht_gefunden
1 = im_Innenraum_gefunden
2 = im_Außenraum_gefunden_nah, Distanz <= parametrierter Schwelle
3 = im_Außenraum_gefunden_fern, Distanz > p";
CM_ SG_ 1426 KY_Schluesselposition_5 "Status des ID-Gebers 5 aus der letzten durchgeführten Schlüsselsuche für Remote Parkfunktionen

0 = nicht_gefunden
1 = im_Innenraum_gefunden
2 = im_Außenraum_gefunden_nah, Distanz <= parametrierter Schwelle
3 = im_Außenraum_gefunden_fern, Distanz > p";
CM_ SG_ 1426 KY_Schluesselposition_6 "Status des ID-Gebers 6 aus der letzten durchgeführten Schlüsselsuche für Remote Parkfunktionen

0 = nicht_gefunden
1 = im_Innenraum_gefunden
2 = im_Außenraum_gefunden_nah, Distanz <= parametrierter Schwelle
3 = im_Außenraum_gefunden_fern, Distanz > p";
CM_ SG_ 1426 KY_Schluesselposition_7 "Status des ID-Gebers 7 aus der letzten durchgeführten Schlüsselsuche für Remote Parkfunktionen

0 = nicht_gefunden
1 = im_Innenraum_gefunden
2 = im_Außenraum_gefunden_nah, Distanz <= parametrierter Schwelle
3 = im_Außenraum_gefunden_fern, Distanz > p";
CM_ SG_ 1426 KY_Schluesselposition_8 "Status des ID-Gebers 8 aus der letzten durchgeführten Schlüsselsuche für Remote Parkfunktionen

0 = nicht_gefunden
1 = im_Innenraum_gefunden
2 = im_Außenraum_gefunden_nah, Distanz <= parametrierter Schwelle
3 = im_Außenraum_gefunden_fern, Distanz > p";
CM_ SG_ 1426 KY_Schluesselposition_9 "Status des ID-Gebers 9 (MDK) aus der letzten durchgeführten Schlüsselsuche für Remote Parkfunktionen

0 = nicht_gefunden
1 = im_Innenraum_gefunden
2 = im_Außenraum_gefunden_nah, Distanz <= parametrierter Schwelle
3 = im_Außenraum_gefunden_fern, Dista";
CM_ SG_ 1426 KY_Startknopf_Bel "Startknopf beleuchten";
CM_ SG_ 1426 KY_StartStopp_Info "Stopp-Freigabe und Start-Anforderung an den Start-Stopp-Koordinator";

CM_ SG_ 960 BCM_Ausparken_Betrieb "Anforderung zur erneuten Lampenaufprüfung und Anzeige von Warnhinweisen nach einem pilotierten Ausparkvorgang (Trigger: fallende Flanke)";
CM_ SG_ 960 BCM_Remotestart_Betrieb "Zeigt den Status des RemoteStarts an, d.h. KL15_RSt ist aktiviert und der Motorlauf ist im RSt-Betrieb aktiv.";
CM_ SG_ 960 BCM_Remotestart_KL15_Anf "Zeigt den Status der Aktivierung der KL15_RST durch das BCM an.";
CM_ SG_ 960 BCM_Remotestart_MO_Start "Nachdem das BCM die Remotestart MSG Freigabe sicher erkannt hat, fordert das BCM wiederum über dieses Signal vom MSG einen Motorstart durchzuführen.";
CM_ SG_ 960 Klemmen_Status_01_BZ "4bit Botschaftszaehler; wird in jeder Sendebotschaft inkrementiert";
CM_ SG_ 960 Klemmen_Status_01_CRC "Für MLB:
'Berechnung siehe Lastenheft 'Kommunikationsabsicherung für FlexRay und CAN''

Ab MQB und MLBevo:
'Berechnung siehe Lastenheft 'End-to-End Kommunikationsabsicherung''

Endwerte siehe Begleitdokument 'S-PDU Kennungsfolgen'";
CM_ SG_ 960 KST_Fahrerhinweis_1 "Signalisierung Fahrerhinweis 1 der Klemmensteuerung an das Kombi";
CM_ SG_ 960 KST_Fahrerhinweis_2 "Signalisierung Fahrerhinweis 2 der Klemmensteuerung an das Kombi";
CM_ SG_ 960 KST_Fahrerhinweis_4 "Signalisierung Fahrerhinweis 4 der Klemmensteuerung an das Kombi";
CM_ SG_ 960 KST_Fahrerhinweis_5 "Anzeigesignal für RemoteStart";
CM_ SG_ 960 KST_Fahrerhinweis_6 "Signal aktiviert die Kombi-Anzeigeinstrumente (Drehzahl, Tankinhalt, Kühlmitteltemperatur) während aktiviertem RemoteStart-Betrieb";
CM_ SG_ 960 KST_Warn_P1_ZST_def "Kombi Prio Warnung Klemmensteuerung 
Zündschloß defekt, Service aufsuchen!";
CM_ SG_ 960 KST_Warn_P2_ZST_def "Kombi Prio Warnung Klemmensteuerung
Zündschloß defekt!
";
CM_ SG_ 960 RSt_Fahrerhinweise "Über das Signal fordert das BCM Fahrerhinweise im Kombi für die Funktion RemoteStart an.";
CM_ SG_ 960 ZAS_Kl_15 "Klemme 15: Zuendung (SW-Kl.15)
";
CM_ SG_ 960 ZAS_Kl_50_Startanforderung "Klemme 50: Startwunsch Fahrer
";
CM_ SG_ 960 ZAS_Kl_Infotainment "Separate Klemmeninformation für das Infotainment. Signal entspricht im wesentlichen einer Klemme S Information, kann aber über einen Vor - bzw. Nachlauf zu Klemme S verfügen. 
Ein konkreter Anwendungsfall für einen Nachlauf ist die Abschaltung der Klemme";
CM_ SG_ 960 ZAS_Kl_S "Klemme S: S-Kontakt (Schluessel steckt)
";
CM_ SG_ 960 ZAS_Kl_X "Klemme 75
";

CM_ SG_ 2463978753 Klemmen_Status_02_BZ "4bit Botschaftszähler, wird mit jeder Sendebotschaft inkrementiert";
CM_ SG_ 2463978753 Klemmen_Status_02_CRC "Für MLB:
Berechnung siehe Lastenheft 'Kommunikationsabsicherung für FlexRay und CAN'
Ab MQB und MLBevo:
Berechnung siehe Lastenheft 'End-to-End Kommunikationsabsicherung'

Endwerte siehe Begleitdokument 'S-PDU Kennungsfolgen'";
CM_ SG_ 2463978753 KST_ComfortReadyStatus "Zustand des ComfortReadyStatus über den Komfortfunktionen aktiviert werden können.";
CM_ SG_ 2463978753 KST_Freigabe_Zustand "Gibt den Sperr- bzw. Freigabezustand der Klemmensteuerung während SW-Update (z. B. Infotainment) an";
CM_ SG_ 2463978753 KST_Sonderzustand_Anforderung "Hiermit wird die aktive bzw. aktuell angeforderte (s. KST_Sonderzustand_Status) Sonderfunktion identifiziert";
CM_ SG_ 2463978753 KST_Sonderzustand_Status "Hiermit wird signalisiert, dass eine Sonderfunktion aktiv ist und die Klemme 15 durch diese angefordert wurde bzw. ein Übergang von Sonderfunktionen stattfindet";
CM_ SG_ 2463978753 KST_WFS_Fahrfreigabe_Anforderung "Hiermit wird den Wegfahrsperren-Teilnehmern signalisiert welche Art der Fahrfreigabe von der anfordernden Sonderfunktion benötigt wird";

CM_ SG_ 1646 KL_Anf_AussenspiegelHzg "Anforderung Außenspiegelheizung seitens Klimafunktion (z.B. bei Erweiterter VoKo)";
CM_ SG_ 1646 KL_BCmE_Livetip_Freigabe "Status der Klimaanlage. 
Zeigt an, ob der Livetip 'Fenster schließen wegen Ineffizienz Klimaanlage' sinvollerweise angezeigt werden soll";
CM_ SG_ 1646 KL_ErwVK_Anf "Erweiterte Voko angefordertert / aktiv";
CM_ SG_ 1646 KL_FSH_Automatikbetrieb "Ermöglicht eine Unterscheidung von Anforderung FSH durch Kundenwunsch und Anforderung FSH durch Regelung des Klimasteuergeräts.
Das Signal liegt als Pegel an.";
CM_ SG_ 1646 KL_Geblaese_Fond_Status "Status Geblaese









";
CM_ SG_ 1646 KL_Geblaese_Status "Status Geblaese









";
CM_ SG_ 1646 KL_Heizkreisventilstellung "Bei MQB PHEV: Stellung Heizkreisventil Motor";
CM_ SG_ 1646 KL_I_Geblaese_Fond "Stromaufnahme Gebläse Heck";
CM_ SG_ 1646 KL_Innen_Temp "Innentemperatur

";
CM_ SG_ 1646 KL_Kompressorkupplung "Signal zur Aktivierung/Deaktivierung der Kompressorkupplung";
CM_ SG_ 1646 KL_Magnetventil "Anforderung des Bypassventils.";
CM_ SG_ 1646 KL_Restwaerme_aktiv "Signal zur Aktivierung/Deaktivierung der Wasserpumpe bei Restwärme; 
reduzierte IRÜ Empfindlichkeit";
CM_ SG_ 1646 KL_SH_Soll_hl "Einstellung Sitzheizung hinten links (0...6)";
CM_ SG_ 1646 KL_SH_Soll_hr "Einstellung Sitzheizung hinten rechts (0...6)";
CM_ SG_ 1646 KL_SIH_LEH_Verteilung_VL "Vom Kunden eingestellte Aufteilung der Heizleistung auf Sitzfläche und Lehnefläche für Sitz vorne links";
CM_ SG_ 1646 KL_SIH_LEH_Verteilung_VR "Vom Kunden eingestellte Aufteilung der Heizleistung auf Sitzfläche und Lehnefläche für Sitz vorne rechts";
CM_ SG_ 1646 KL_SIH_LEL_Verteilung_VL "Vom Kunden eingestellte Aufteilung der Lüftungsleistung auf Sitzfläche und Lehnenfläche für Sitz vorne links";
CM_ SG_ 1646 KL_SIH_LEL_Verteilung_VR "Vom Kunden eingestellte Aufteilung der Lüftungsleistung auf Sitzfläche und Lehnenfläche für Sitz vorne rechts";
CM_ SG_ 1646 KL_Solarluefter_aktiv "Betriebsstatus Solarluefter
";
CM_ SG_ 1646 KL_STH_aktiv "Betriebsstatus Standheizung
";
CM_ SG_ 1646 KL_STH_Ansteuerung "Ansteuerung STH

";
CM_ SG_ 1646 KL_STH_Betriebsdauer "Betriebsdauer STH";
CM_ SG_ 1646 KL_STL_aktiv "Betriebsstatus Standlueftung
";
CM_ SG_ 1646 KL_Umluft_Taste "Betaetigung Umlufttaste
";
CM_ SG_ 1646 KL_WaPu "Ansteuerung der Standheizungswasserpumpe";

CM_ SG_ 1649 KL_Betriebsmodus_FH "Synchronisation des Betriebsmodus zwischen Front und Fond";
CM_ SG_ 1649 KL_ErwVK_Beifahrerzone "Erweiterte Voko Beifahrerseite";
CM_ SG_ 1649 KL_ErwVK_Fahrerzone "Erweiterte Voko Fahrerseite";
CM_ SG_ 1649 KL_ErwVK_Heckzone2_links "Anforderung der Heckzone dritte Sitzreihe links";
CM_ SG_ 1649 KL_ErwVK_Heckzone2_rechts "Anforderung der Heckzone dritte Sitzreihe rechts";
CM_ SG_ 1649 KL_ErwVK_Heckzone_links "Erweiterte Voko Heckzone links";
CM_ SG_ 1649 Kl_ErwVK_Heckzone_rechts "Erweiterte Voko Heckzone rechts.";
CM_ SG_ 1649 KL_ErwVK_Scheibenheizung "Erweiterte Voko Scheibenheizung";
CM_ SG_ 1649 KL_ErwVK_Status "Erweiterte Voko angefordert für
   Fahrerzone_aktiv
   Alle Zonen_aktiv
   Beifahrerzone_aktiv
   Heckzone_aktiv
   Scheibenheizung_aktiv";
CM_ SG_ 1649 KL_Hinweis_Kuehlmodus "Signal generiert einen Kundenhinweis, ob eine normale Klimatisierung umgesetzt werden kann, oder ein Sondermodus aktiv ist";
CM_ SG_ 1649 KL_Meldung_Status "Klima gibt den Status der Fahrermeldungen aus.";
CM_ SG_ 1649 KL_STH_Betriebsdauer_lang "Betriebsdauer STH im Falle eines möglichen 120min Betriebes.";
CM_ SG_ 1649 KL_Stopp_Wiederstart_Anz_01 "Dieses Signal gibt die detaillierte Begründung für eine Stoppverbot-/Wiederstartanfrage der Klima-SG an.";
CM_ SG_ 1649 KL_Stopp_Wiederstart_Anz_02 "Dieses Signal gibt die detaillierte Begründung für eine Stoppverbot-/Wiederstartanfrage der Klima-SG an.";
CM_ SG_ 1649 KL_Stopp_Wiederstart_Anz_03 "Dieses Signal gibt die detaillierte Begründung für eine Stoppverbot-/Wiederstartanfrage der Klima-SG an.";
CM_ SG_ 1649 KL_Stopp_Wiederstart_Anz_04 "Dieses Signal gibt die detaillierte Begründung für eine Stoppverbot-/Wiederstartanfrage der Klima-SG an.";
CM_ SG_ 1649 KL_Stopp_Wiederstart_Anz_05 "Dieses Signal gibt die detaillierte Begründung für eine Stoppverbot-/Wiederstartanfrage der Klima-SG an.";
CM_ SG_ 1649 KL_Stopp_Wiederstart_Anz_06 "Dieses Signal gibt die detaillierte Begründung für eine Stoppverbot-/Wiederstartanfrage der Klima-SG an.";
CM_ SG_ 1649 KL_Stopp_Wiederstart_Anz_07 "Dieses Signal gibt die detaillierte Begründung für eine Stoppverbot-/Wiederstartanfrage der Klima-SG an.";
CM_ SG_ 1649 KL_Stopp_Wiederstart_Anz_08 "Dieses Signal gibt die detaillierte Begründung für eine Stoppverbot-/Wiederstartanfrage der Klima-SG an.";
CM_ SG_ 1649 KL_Stopp_Wiederstart_Anz_09 "Dieses Signal gibt die detaillierte Begründung für eine Stoppverbot-/Wiederstartanfrage der Klima-SG an.";
CM_ SG_ 1649 KL_Stopp_Wiederstart_Anz_Std1 "Dieses Signal gibt die detaillierte Begründung für eine Stoppverbot-/Wiederstartanfrage der Klima-SG an.";
CM_ SG_ 1649 KL_Stopp_Wiederstart_Anz_Std2 "Dieses Signal gibt die detaillierte Begründung für eine Stoppverbot-/Wiederstartanfrage der Klima-SG an.";
CM_ SG_ 1649 KL_ZZ_Betriebsmodus "Betriebsdauerberechnung anhand Aussentemperaturauswertung mit Faktor 'ZZ_Betriebsmodus'";
CM_ SG_ 1649 KL_ZZ_Minute "Zielzeittimeranzeige im Display der Funkfernbedienung (Minute); Initwert ist der zuletzt gültige Wert";
CM_ SG_ 1649 KL_ZZ_Monat "Zielzeittimeranzeige im Display der Funkfernbedienung (Datum, Monat); Initwert ist der zuletzt gültige Wert";
CM_ SG_ 1649 KL_ZZ_Status_Timer "Timerstatusanzeige im Display der Funkfernbedienung (Timer aktiv/n.aktiv)";
CM_ SG_ 1649 KL_ZZ_Stunde "Zielzeittimeranzeige im Display der Funkfernbedienung (Stunde); Initwert ist der zuletzt gültige Wert";
CM_ SG_ 1649 KL_ZZ_Tag "Zielzeittimeranzeige im Display der Funkfernbedienung (Datum, Tag); Initwert ist der zuletzt gültige Wert";

CM_ SG_ 949 KL_AC_Schalter "AC Schalter
";
CM_ SG_ 949 KL_AirCleaner_aktiv "Status des Zustands der AirCare Funktion (Umluft) im Fahrzeug";
CM_ SG_ 949 KL_Anf_KL "Anforderung Kühlerlüfter der Klimaanlage in Prozent

";
CM_ SG_ 949 KL_Anf_KV "Anforderung des Kühlerrollos in %";
CM_ SG_ 949 KL_Ausstattung_Klima "Austtattungsart der Klimabedienung";
CM_ SG_ 949 KL_Charisma_FahrPr "MLBevo: Aktuelles Fahrprogramm des Charisma-Teilnehmers (siehe Systemlastenheft Drive Select)
MQB: Istwert der Kennlinie (siehe Systemlastenheft MQB FPA)";
CM_ SG_ 949 KL_Charisma_Status "Charisma Systemstatus des Charisma-Teilnehmers

Wert 0x3 ist nur für Fahrzeuge ab MQB relevant";
CM_ SG_ 949 KL_Drehz_Anh "Drehzahlanhebung vom Motor angefordert

";
CM_ SG_ 949 KL_el_Zuheizer_Stufe "Vorgabe für Motorsteuergeraet PTC-Stufe; im MLB-B8 und MQB nur Stufe 0...3

";
CM_ SG_ 949 KL_Freilauf_Info "Freilauf Informationssignal von Klima zum Freilaufkoordinator. Klima kann über dieses Signal den Freilauf freigeben, verhindern bzw. explizit anfordern.";
CM_ SG_ 949 KL_Kompressorkupplung_linear "Sollwert zur Ansteuerung der Kompressorkupplung";
CM_ SG_ 949 KL_Last_Kompr "Aktuelles Verlustmoment der Klimaanlage bezogen auf die Kurbelwelle. Wird der Klimakompressor nicht angesteuert, ist das Schleppmoment bezogen auf die Kurbelwelle zu senden.";
CM_ SG_ 949 KL_nachtr_Stopp_Anf "Dieses Signal dient dem Motor als Trigger, dass ein nachträglicher Motorstopp eingeleitet werden kann, wenn es die Bedingungen des StSt Koordinators dies zulassen. ";
CM_ SG_ 949 KL_Spannungs_Anf "Forderung des Klima-SG's zur Spannungsanhebung.";
CM_ SG_ 949 KL_StartStopp_Info "Stopp-Freigabe und Start-Anforderung an den Start-Stopp-Koordinator";
CM_ SG_ 949 KL_T_Charge "Signal für Tastenbetätigung Charge-Taste (SOC Increasing)";
CM_ SG_ 949 KL_Thermomanagement "Stufen des Thermomanagements;
Bei Klemme 15 AUS und erkannten Timeout zum Klimabedienteil (z.B. Klimabedienteil während des Motorsteuergeräte-Kommunikations-Nachlaufs bereits im NM-Zustand ¿Bus Sleep¿)
erfolgt keine Ansteuerung der Wasserpumpe durch die";
CM_ SG_ 949 KL_Variante_Standheizung "Identifikation der Variante der Standheizungen zur Berechnung der energetischen Zielzeit";
CM_ SG_ 949 KL_Vorwarn_Komp_ein "Vorwarnung Kompressor ein; 140ms vorher; Information für Motor zum Aufbau Momentenreserve";
CM_ SG_ 949 KL_Vorwarn_Zuheizer_ein "Vorwarnung Zuheizerbetrieb
";
CM_ SG_ 949 KL_Zustand "Beschreibt den Zustand des Klima-/Heizungsbedienteils. (OFF-Mode Bedienteil)

PAG (MLB): Beschreibt den Zustand des Kompressors";

CM_ SG_ 1640 FSH_Taster "Tasterbetätigung Frontscheibenheizung
";
CM_ SG_ 1640 HSH_Taster "An-/Abforderung Heckscheibenheizung über spezielles Tastersignal
";
CM_ SG_ 1640 KL_Beschlagsgefahr "Beschlagsgefahr auf der Frontscheibe im Bereich des Spiegelfusses. Dient zur präventiven Ansteuerung der  Kamera-Scheibenheizung, um Kamera-Blindheit zu vermeiden
PHEV: volle Leistungsfreigabe 
HV Heizer und HV EKK bei Scheibenbeschlag ";
CM_ SG_ 1640 KL_Geblspng_Fond_Soll "Ausgabe des Sollwertes für die Spannung des Klimagebläsemotores hinten.






";
CM_ SG_ 1640 KL_Geblspng_Soll "Ausgabe des Sollwertes für die Spannung des Klimagebläsemotores vorne.







";
CM_ SG_ 1640 KL_I_Geblaese "Stromaufnahme Gebläse";
CM_ SG_ 1640 KL_Kompressorstrom_soll "Sollvorgabe Klima-Kompressorstrom";
CM_ SG_ 1640 KL_LRH_Stufe "Eingestellte Temperaturstufe der Lenkradheizung";
CM_ SG_ 1640 KL_LRH_Taster "Tasterbetätigung Lenkradheizung";
CM_ SG_ 1640 KL_PTC_Verbauinfo "Im Klima- bzw. Heizungsbedienteil wird der Verbau eines PTCs und dessen elektr. Leistungsklasse codiert";
CM_ SG_ 1640 KL_SIH_Soll_li "Einstellung Sitzheizung Fahrer (0...6)";
CM_ SG_ 1640 KL_SIH_Soll_re "Einstellung Sitzheizung Beifahrer (0...6)";
CM_ SG_ 1640 KL_SIL_Soll_li "Einstellung Sitzlüftung Fahrer (0...6)";
CM_ SG_ 1640 KL_SIL_Soll_re "Einstellung Sitzlüftung Beifahrer (0...6)";
CM_ SG_ 1640 KL_Umluftklappe_Status "Status Umluftklappe";
CM_ SG_ 1640 KL_Zuheizer_Freigabe "Freigabe Zuheizer
";
CM_ SG_ 1640 KRH_Soll_li "Ausgabe des Sollwertes für die Kopfraumheizung links.";
CM_ SG_ 1640 KRH_Soll_re "Ausgabe des Sollwertes für die Kopfraumheizung rechts.";

CM_ SG_ 2527679635 FSH_Status "Fehlerstatus der Frontscheibenheizung
";
CM_ SG_ 2527679635 HSH_Relais_Anf "Relaisanforderung Heckscheibenheizung";
CM_ SG_ 2527679635 KL_AL_HL_Anf "Anforderung an das funktionale Ambientelicht eine Solltemperaturveränderung hinten links darzustellen.";
CM_ SG_ 2527679635 KL_AL_HR_Anf "Anforderung an das funktionale Ambientelicht eine Solltemperaturveränderung hinten rechts darzustellen.";
CM_ SG_ 2527679635 KL_AL_VL_Anf "Anforderung an das funktionale Ambientelicht eine Solltemperaturveränderung vorn links darzustellen.";
CM_ SG_ 2527679635 KL_AL_VR_Anf "Anforderung an das funktionale Ambientelicht eine Solltemperaturveränderung vorn rechts darzustellen.";
CM_ SG_ 2527679635 KL_Defrost_LED "Beleuchtung LED Defrost";
CM_ SG_ 2527679635 KL_FSH_LED "Beleuchtung LED Frontscheibenheizung";
CM_ SG_ 2527679635 KL_FSH_Soll "Sollstatus der Frontscheibenheizung";
CM_ SG_ 2527679635 KL_Heizstufe_LSH "Vom Klimabedienteil gesendete Heizstufe der Luftstandheizung";
CM_ SG_ 2527679635 KL_HSH_LED "Beleuchtung LED Heckscheibenheizung";
CM_ SG_ 2527679635 KL_HSH_Soll "Sollstatus Heckscheibenheizung";
CM_ SG_ 2527679635 KL_HUP_aktiv "Signal des Klimabedienteils ob HUP aktiv ist.

0 = HUP aus
1 = HUP ein";
CM_ SG_ 2527679635 KL_Klappe_Status "Status Luftklappe";
CM_ SG_ 2527679635 KL_LRH_PWM "LRH PWM Signal zur Ansteuerung der Treiberstufe im SMLS (0% - 100%)";
CM_ SG_ 2527679635 KL_LRH_Soll "Sollstatus der Lenkradheizung";
CM_ SG_ 2527679635 KL_LSH_Ansteuerung "Ansteuerung LSH";
CM_ SG_ 2527679635 KL_LSH_Betriebsdauer "Betriebsdauer LSH";
CM_ SG_ 2527679635 KL_LSH_DBetr_Bestaet "Bestätigung des Klimabedienteils an die LSH das Dauerbetrieb tatsächlich angefordert ist.";
CM_ SG_ 2527679635 KL_LSH_DBetr_Ein "Dauerbetrieb der Luftstandheizung Ein";
CM_ SG_ 2527679635 KL_Temp_ZH_Soll "Übertragung der Temperaturvorgabe der Klimaanlage an die Wasserzusatzheizung";
CM_ SG_ 2527679635 KL_VoKo_LED "Signalisierung Vorkonditionierung";
CM_ SG_ 2527679635 KL_Voko_Status "Status der Vorkonditionierung.

0 = aus
1 = ein

14 = Init
15 = Fehler";
CM_ SG_ 2527679635 KL_ZR_Anforderung "Anforderung an MIB die Displays zu aktivieren";
CM_ SG_ 2527679635 SIH_Stufe_LED_li "Statusmeldung Sitzheizung links";
CM_ SG_ 2527679635 SIH_Stufe_LED_re "Statusmeldung Sitzheizung rechts";

CM_ SG_ 2589283627 KL_EKK_1_VerbautStatus "Verbaustatus EKK1";
CM_ SG_ 2589283627 KL_EKK_2_VerbautStatus "Verbau Information zweiter EKK";
CM_ SG_ 2589283627 KL_Heizen_Status "Anforderungspriorität Unterkomponente zur Priorisierung und Leistungsverteilung im HV-EM";
CM_ SG_ 2589283627 KL_HV_Energie_Anf "Anforderung HV - Energiebedarf, für VoKo 
";
CM_ SG_ 2589283627 KL_HVH_1_VerbautStatus "Verbau Information HV_Heizer1";
CM_ SG_ 2589283627 KL_HVH_2_VerbautStatus "Verbau Information zusaetzlicher Heizer";
CM_ SG_ 2589283627 KL_IstLeistung "Gesamt-Ist-Leistung für Komfort- und Thermomanagement";
CM_ SG_ 2589283627 KL_K_Status "Satus der Klimatisierung und Wärmepumpe wird ausgegeben.";
CM_ SG_ 2589283627 Kl_Klima_Aktiv "Rückmeldung über HV Klimaaktivität durch Klimasteuergerät für BEV/PHEV";
CM_ SG_ 2589283627 KL_Kuehlungs_Status "Anforderungspriorität Unterkomponente zur Priorisierung und Leistungsverteilung im HV-EM";
CM_ SG_ 2589283627 KL_Leistung_Klima_Anf "Leistungsanforderung ans HVEM von Klima";
CM_ SG_ 2589283627 KL_Status_Battkuehlung "Statusinformation über den akuellen Zustand der aktiven Batteriekühlung durch die Klimaanlage";
CM_ SG_ 2589283627 KL_Temp_Kundenwunsch "Temeratur, die auf der Fahrerseite der Climatronic vom Kunden vorgegeben wird.";
CM_ SG_ 2589283627 KL_Texte "Ein Defizit in Heizleistung bzw. Kühlleistung soll dem Kunden angezeigt werden";
CM_ SG_ 2589283627 TME_HVEM_HV_Anf "Anforderung 'HV-Netz aktivieren' wegen Innenraumkonditionierung mit HV-Komponente";

CM_ SG_ 1712 FS_Luftfeuchte_rel "gemessene relative Luftfeuchte";
CM_ SG_ 1712 FS_ResponseError "siehe LIN2.0-Specification
(Darf nicht über ein Fehlergueltigkeitsbit abgesichtert werden!)";
CM_ SG_ 1712 FS_Taupunkt "berechneter Taupunkt";
CM_ SG_ 1712 FS_Temp_Scheibe "gemessene Frontscheibentemperatur";
CM_ SG_ 1712 FS_Temp_Sensor "gemessene Sensortemperatur";

CM_ SG_ 1505 BCM1_Aussen_Temp_ungef "ungefilterter Wert des Aussentemperatursensors
";
CM_ SG_ 1505 BCM1_FStatus_Aussentemp_ungef "Fehlerstatus für Aussentemperatur (Kombianzeige)";
CM_ SG_ 1505 BCM1_Kompressorstrom_ist "IST-Strom vom Klima-Kompressor";
CM_ SG_ 1505 BCM1_OBD_FStatus_ATemp "Fehlerstatus Umgebungstemperatursensor (OBD relevanter Sensor)
";
CM_ SG_ 1505 BCM1_PTC_stufig_Status "Status des BCM1-Heizverbrauchers PTC (stufig)";
CM_ SG_ 1505 BCM_Heizungsabsperrventil_Status "Das Signal beschreibt den Zustand des Heizungsabsperrventils, welches als Portexpander vom BCM1 elektrisch angesteuert wird.";
CM_ SG_ 1505 BCM_Heizungspumpe_Status "Das Signal beschreibt den Zustand der Heizungspumpe, welche als Portexpander vom BCM1 elektrisch angesteuert wird.";
CM_ SG_ 1505 BCM_Kompressorkupplung_Status "Das Signal beschreibt den Zustand der Klimakompressorkupplung, welche als Portexpander vom BCM1 elektrisch angesteuert wird.";

CM_ SG_ 1717 FSA_Err_Defekt_HumSens_TNCTOC "OBD TestNotCompletedThisOperationCycle nach LIN LAH für Feuchteelement, testNotCompletedThisOperationCycle (TNCTOC)";
CM_ SG_ 1717 FSA_Err_Defekt_HumSense_TF "OBD TestFailed Flag, Statusbotschaft für Feuchtesensor außen, testFailed (TF)";
CM_ SG_ 1717 FSA_Err_Defekt_Tsens_TF "OBD TestFailed Flag, Statusbotschaft für diden Feuchtesensor, testFailed (TF)";
CM_ SG_ 1717 FSA_Err_RAMROM_Check_TF "OBD TestFailed Flag, Statusbotschaft für den Feuchtesensor, testFailed (TF)";
CM_ SG_ 1717 FSA_Err_RAMROM_Check_TNCTOC "Signal meldet den Status der Diagnosen nach OBD LIN-LAH, testNotCompletedThisOperationCycle (TNCTOC)";
CM_ SG_ 1717 FSA_Err_Ueberspannung_TF "OBD TestFailed Flag, Statusbotschaft für den Feuchtesensor Außen, testFailed (TF)";
CM_ SG_ 1717 FSA_Err_Unterspannung_TF "OBD TestFailed Flag, Statusbotschaft für den Feuchtesensor, testFailed (TF)";
CM_ SG_ 1717 FSA_ErrMemState "OBD Signal statusbotschaft für den Feuchtesensor außen";
CM_ SG_ 1717 FSA_HW "Hardwarestand";
CM_ SG_ 1717 FSA_Luftfeuchte_rel "Maximaler Feuchtebereich bis 126% für theoretisch errechnete Feuchtewerte des Sensors. Signalwerte >100% bedeuten  rel. Feuchte = 100%";
CM_ SG_ 1717 FSA_Luftfeuchte_TF "OBD TestFailed Flag, Statusbotschaft für den Feuchtesensor, testFailed (TF)";
CM_ SG_ 1717 FSA_Luftfeuchte_TNCTOC "Signal meldet den Status der Diagnosen nach OBD LIN-LAH, testNotCompletedThisOperationCycle (TNCTOC)";
CM_ SG_ 1717 FSA_ResponseError "siehe LIN2.0-Specification
(Darf nicht über ein Fehlergueltigkeitsbit abgesichtert werden!)";
CM_ SG_ 1717 FSA_Sensorheizung_Status "Status der Heizung im Feuchteelement (z.B. SHT10).
0 (=inaktiv) auch bei nicht verbaut";
CM_ SG_ 1717 FSA_SW "Softwarestand";
CM_ SG_ 1717 FSA_Taupunkt "'Init' falls nicht verbaut";
CM_ SG_ 1717 FSA_Temp_Luft "gemessene Temperatur im Luftstrom (z.B. NTC am Sensor)
'Init' falls nicht verbaut
(+61°C bedeutet: Temp_Luft > 60,9°C !)";

CM_ SG_ 2549088367 AMP_Abschaltstufe "Funktionseinschränkung aufgrund aktiver Abschaltstufe";
CM_ SG_ 2549088367 AMP_KD_Fehler "Bei gesetztem Bit ist mindestens ein Kundendienstfehler eingetragen";
CM_ SG_ 2549088367 AMP_KompSchutz "Funktionseinschränkung aufgrund Komponentenschutz aktiv";
CM_ SG_ 2549088367 AMP_Nachlauftyp "Abgebildet wird die von der Hardware vorgegebene Möglichkeit, die Kommunikation nach Klemme 15 = AUS aufrecht zu erhalten. Es wird ein Init-Wert gesendet.";
CM_ SG_ 2549088367 AMP_Transport_Mode "Funktionseinschränkung aufgrund aktivem Transport Mode und/oder Transport Schutz";
CM_ SG_ 2549088367 KN_AMP_DiagPfad "Kennzeichnung der Diagnosefähigkeit des BusInterfaces eines Steuergerätes (Knoten)
Umfang LAH 80127

Bei Nutzung des Signal explizit pro angebundenem BusInterface zu setzen:
MQB AB auf I-CAN = 0 (aktiv)
MQB A0 auf K-CAN = 0 (aktiv)
MQB2020 auf VLAN-";
CM_ SG_ 2549088367 NM_AMP_Wakeup "enthält die Weckursache; stehen mehrere Weckursachen parallel an, dann muss der kleinste Wert übertragen werden";

CM_ SG_ 2549088564 BedienDisp_m_Abschaltstufe "Funktionseinschränkung aufgrund aktiver Abschaltstufe";
CM_ SG_ 2549088564 BedienDisp_m_KD_Fehler "Bei gesetztem Bit ist mindestens ein Kundendienstfehler eingetragen";
CM_ SG_ 2549088564 BedienDisp_m_KompSchutz "Funktionseinschränkung aufgrund Komponentenschutz aktiv";
CM_ SG_ 2549088564 BedienDisp_m_Nachlauftyp "Abgebildet wird die von der Hardware vorgegebene Möglichkeit, die Kommunikation nach Klemme 15 = AUS aufrecht zu erhalten. Es wird ein Init-Wert gesendet.
0 = Kommunikation nur bei KL15=EIN (kein Nachlauf, nicht weckfähig)
1 = Kommunikation nach KL15=AU";
CM_ SG_ 2549088564 BedienDisp_m_Transport_Mode "Funktionseinschränkung aufgrund aktivem Transport Mode und/oder Transport Schutz";
CM_ SG_ 2549088564 KN_BedienDisp_m_BusKnockOut "Ausgabe des BusKnockout-Status in der Knotenbotschaft";
CM_ SG_ 2549088564 KN_BedienDisp_m_BusKnockoutTimer "Ausgabe des BusKnockOut-Timer in der Knotenbotschaft";
CM_ SG_ 2549088564 KN_BedienDisp_m_DiagPfad "Kennzeichnung der Diagnosefähigkeit des BusInterfaces eines Steuergerätes (Knoten)
Umfang LAH 80127

Bei Nutzung des Signal explizit pro angebundenem BusInterface zu setzen:
MQBw_Baseline auf I-CANHS = 0 (aktiv)";
CM_ SG_ 2549088564 KN_BedienDisp_m_ECUKnockOut "Ausgabe des ECUKnockout-Status in der Knotenbotschaft";
CM_ SG_ 2549088564 KN_BedienDisp_m_ECUKnockOutTimer "Ausgabe des ECUKnockOut-Timer in der Knotenbotschaft";
CM_ SG_ 2549088564 NM_BedienDisp_m_Wakeup "enthält die Weckursache; stehen mehrere Weckursachen parallel an, dann muss der kleinste Wert übertragen werden";

CM_ SG_ 2549088418 BedienDisp_vm_Abschaltstufe "Funktionseinschränkung aufgrund aktiver Abschaltstufe";
CM_ SG_ 2549088418 BedienDisp_vm_KD_Fehler "Bei gesetztem Bit ist mindestens ein Kundendienstfehler eingetragen";
CM_ SG_ 2549088418 BedienDisp_vm_KompSchutz "Funktionseinschränkung aufgrund Komponentenschutz aktiv";
CM_ SG_ 2549088418 BedienDisp_vm_Nachlauftyp "Abgebildet wird die von der Hardware vorgegebene Möglichkeit, die Kommunikation nach Klemme 15 = AUS aufrecht zu erhalten. Es wird ein Init-Wert gesendet.
0 = Kommunikation nur bei KL15=EIN (kein Nachlauf, nicht weckfähig)
1 = Kommunikation nach KL15=AU";
CM_ SG_ 2549088418 BedienDisp_vm_Transport_Mode "Funktionseinschränkung aufgrund aktivem Transport Mode und/oder Transport Schutz";
CM_ SG_ 2549088418 KN_BedienDisp_vm_BusKnockOut "Ausgabe des BusKnockout-Status";
CM_ SG_ 2549088418 KN_BedienDisp_vm_BusKnockOutTime "Ausgabe des BusKnockOut-Timer";
CM_ SG_ 2549088418 KN_BedienDisp_vm_DiagPfad "Kennzeichnung der Diagnosefähigkeit des BusInterfaces eines Steuergerätes (Knoten)
Umfang LAH 80127

Bei Nutzung des Signal explizit pro angebundenem BusInterface zu setzen:
MQBw_Baseline auf I-CANHS = 0 (aktiv)
E_1_1_UNECE auf AB-CANFD = 0 (aktiv)";
CM_ SG_ 2549088418 KN_BedienDisp_vm_ECUKnockOut "Ausgabe des ECUKnockout-Status";
CM_ SG_ 2549088418 KN_BedienDisp_vm_ECUKnockOutTime "Ausgabe des ECUKnockOut-Timer";
CM_ SG_ 2549088418 NM_BedienDisp_vm_Wakeup "enthält die Weckursache; stehen mehrere Weckursachen parallel an, dann muss der kleinste Wert übertragen werden";

CM_ SG_ 2549088570 DCAM_Abschaltstufe "Funktionseinschränkung aufgrund aktiver Abschaltstufe";
CM_ SG_ 2549088570 DCAM_KD_Fehler "Bei gesetztem Bit ist mindestens ein Kundendienstfehler eingetragen";
CM_ SG_ 2549088570 DCAM_KompSchutz "Funktionseinschränkung aufgrund Komponentenschutz aktiv";
CM_ SG_ 2549088570 DCAM_Nachlauftyp "Abgebildet wird die von der Hardware vorgegebene Möglichkeit, die Kommunikation nach Klemme 15 = AUS aufrecht zu erhalten. Es wird ein Init-Wert gesendet.";
CM_ SG_ 2549088570 DCAM_Transport_Mode "Funktionseinschränkung aufgrund aktivem Transport Mode und/oder Transport Schutz";
CM_ SG_ 2549088570 KN_DCAM_BusKnockOut "Ausgabe des BusKnockout-Status in der Knotenbotschaft";
CM_ SG_ 2549088570 KN_DCAM_BusKnockOutTimer "Ausgabe des BusKnockOut-Timer in der Knotenbotschaft";
CM_ SG_ 2549088570 KN_DCAM_DiagPfad "Kennzeichnung der Diagnosefähigkeit des BusInterfaces eines Steuergerätes (Knoten)
Umfang LAH 80127

Bei Nutzung des Signal explizit pro angebundenem BusInterface zu setzen:
MQBw_Baseline auf VLAN Infotainment = 0 (aktiv)";
CM_ SG_ 2549088570 KN_DCAM_ECUKnockOut "Ausgabe des ECUKnockout-Status in der Knotenbotschaft";
CM_ SG_ 2549088570 KN_DCAM_ECUKnockOutTimer "Ausgabe des ECUKnockOut-Timer in der Knotenbotschaft";
CM_ SG_ 2549088570 NM_DCAM_Wakeup "enthält die Weckursache; stehen mehrere Weckursachen parallel an, dann muss der kleinste Wert übertragen werden";

CM_ SG_ 2549088359 eCall_Abschaltstufe "Funktionseinschränkung aufgrund aktiver Abschaltstufe";
CM_ SG_ 2549088359 eCall_KompSchutz "Funktionseinschränkung aufgrund Komponentenschutz aktiv";
CM_ SG_ 2549088359 eCall_Nachlauftyp "Abgebildet wird die von der Hardware vorgegebene Möglichkeit, die Kommunikation nach Klemme 15 = AUS aufrecht zu erhalten. Es wird ein Init-Wert gesendet.
0 = Kommunikation nur bei KL15=EIN (kein Nachlauf, nicht weckfähig)
1 = Kommunikation nach KL15=AU";
CM_ SG_ 2549088359 eCall_Transport_Mode "Funktionseinschränkung aufgrund aktivem Transport Mode und/oder Transport Schutz";
CM_ SG_ 2549088359 KN_eCall_BusKnockOut "Ausgabe des BusKnockout-Status";
CM_ SG_ 2549088359 KN_eCall_BusKnockOutTimer "Ausgabe des BusKnockOut-Timer";
CM_ SG_ 2549088359 KN_eCall_DiagPfad "Kennzeichnung der Diagnosefähigkeit des BusInterfaces eines Steuergerätes (Knoten)
Umfang LAH 80127

Bei Nutzung des Signal explizit pro angebundenem BusInterface zu setzen:
MQB AB auf K-CAN, I-CAN, T-CAN = 0 (aktiv)
MQB A0 auf K-CAN = 0 (aktiv)
MQB";
CM_ SG_ 2549088359 KN_eCall_ECUKnockOut "Ausgabe des ECUKnockout-Status";
CM_ SG_ 2549088359 KN_eCall_ECUKnockOutTimer "Ausgabe des ECUKnockOut-Timer";
CM_ SG_ 2549088359 NM_eCall_Wakeup "enthält die Weckursache; stehen mehrere Weckursachen parallel an, dann muss der kleinste Wert übertragen werden";

CM_ SG_ 2549088272 Gateway_Abschaltstufe "Funktionseinschränkung aufgrund aktiver Abschaltstufe";
CM_ SG_ 2549088272 Gateway_KompSchutz "Funktionseinschränkung aufgrund Komponentenschutz aktiv";
CM_ SG_ 2549088272 Gateway_Nachlauftyp "Abgebildet wird die von der Hardware vorgegebene Möglichkeit, die Kommunikation nach Klemme 15 = AUS aufrecht zu erhalten. Es wird ein Init-Wert gesendet.";
CM_ SG_ 2549088272 Gateway_Transport_Mode "Funktionseinschränkung aufgrund aktivem Transport Mode und/oder Transport Schutz";
CM_ SG_ 2549088272 GW_KD_Fehler "Kundendienstfehlerbit Gateway zur Anzeige eines im Gateway abgelegten Fehlerspeichereintrages.";
CM_ SG_ 2549088272 KN_GW_DiagPfad "Kennzeichnung der Diagnosefähigkeit des BusInterfaces eines Steuergerätes (Knoten)
Umfang LAH 80127

Bei Nutzung des Signal explizit pro angebundenem BusInterface zu setzen:
MQB auf Diag-CAN = 0 (aktiv)
MLBevo auf Diag-CAN = 0 (aktiv)
alle weiteren ";
CM_ SG_ 2549088272 NM_Gateway_Wakeup "enthält die Weckursache; stehen mehrere Weckursachen parallel an, dann muss der kleinste Wert übertragen werden";
BA_DEF_REL_ BU_SG_REL_  "GenSigTimeoutTime" INT 0 65535;
BA_DEF_ BO_  "DiagRequest" ENUM "No", "Yes";
BA_DEF_ BO_  "DiagResponse" ENUM "No", "Yes";
BA_DEF_ BO_  "DiagState" ENUM "No", "Yes";
BA_DEF_ BO_  "GenMsgChkConstant" HEX 0 4095;
BA_DEF_ BO_  "GenMsgCycleTime" INT 0 65535;
BA_DEF_ BO_  "GenMsgCycleTimeFast" INT 0 65535;
BA_DEF_ BO_  "GenMsgDelayTime" INT 0 100000;
BA_DEF_ BO_  "GenMsgILSupport" ENUM "No", "Yes";
BA_DEF_ BO_  "GenMsgNrOfRepetition" INT 0 100;
BA_DEF_ BO_  "GenMsgPDUConstants" STRING;
BA_DEF_ BO_  "GenMsgSendType" ENUM "Cyclic", "not_used", "not_used", "not_used", "not_used", "not_used", "not_used", "IfActive", "NoMsgSendType";
BA_DEF_ BO_  "GenMsgStartDelayTime" INT 0 100000;
BA_DEF_ BO_  "NmMessage" ENUM "No", "Yes";
BA_DEF_ BO_  "NmhMessage" ENUM "No", "Yes";
BA_DEF_ BO_  "MsgType" ENUM "Application", "NM ", "NMH", "TP2.0", "ISO-TP ", "BAP", "EID", "KS", "XCP_PRE_CONFIGURED", "XCP_RUNTIME_CONFIGURED";
BA_DEF_ BO_  "VAGTP20_API" HEX 0 255;
BA_DEF_ BO_  "VAGTP20_DynConnection" ENUM "No", "Yes";
BA_DEF_ BO_  "VAGTP20_DynSetup" ENUM "No", "Yes";
BA_DEF_ BO_  "VAGTP20_StatConnection" ENUM "No", "Yes";
BA_DEF_ SG_  "GenSigActiveRepetitions" INT -2147483648 2147483647;
BA_DEF_ SG_  "GenSigInactiveValue" INT -2147483648 2147483647;
BA_DEF_ SG_  "GenSigSendType" ENUM "Cyclic", "OnWrite", "OnWriteWithRepetition", "OnChange", "OnChangeWithRepetition", "IfActive", "IfActiveWithRepetition", "NoSigSendType", "OnChangeAndIfActive", "OnChangeAndIfActiveWithRepetition";
BA_DEF_ SG_  "GenSigStartValue" INT -2147483648 2147483647;
BA_DEF_ SG_  "NWM-WakeupAllowed" ENUM "No", "Yes";
BA_DEF_ SG_  "GenSigFuncType" ENUM "NoFunction", "MsgCounter", "CRC-8", "XOR", "XOR-2", "DatedBit", "SW-Kl15", "CHK", "Constant", "Protocol", "CRC-8-SAE_J1850", "CRC-32", "DataLength", "DataID", "MsgCounter16", "SOK-Signatur", "Cluster";
BA_DEF_ SG_  "GenSigSwitchedByIgnition" ENUM "No", "Yes";
BA_DEF_ SG_  "Fehlerwert" HEX 0 2147483647;
BA_DEF_ SG_  "GenSigMissingSourceValue" HEX 0 2147483647;
BA_DEF_DEF_REL_  "GenSigTimeoutTime" 0;
BA_DEF_DEF_  "DiagRequest" "No";
BA_DEF_DEF_  "DiagResponse" "No";
BA_DEF_DEF_  "DiagState" "No";
BA_DEF_DEF_  "GenMsgChkConstant" 0;
BA_DEF_DEF_  "GenMsgCycleTime" 0;
BA_DEF_DEF_  "GenMsgCycleTimeFast" 0;
BA_DEF_DEF_  "GenMsgDelayTime" 0;
BA_DEF_DEF_  "GenMsgILSupport" "No";
BA_DEF_DEF_  "GenMsgNrOfRepetition" 0;
BA_DEF_DEF_  "GenMsgPDUConstants" "";
BA_DEF_DEF_  "GenMsgSendType" "NoMsgSendType";
BA_DEF_DEF_  "GenMsgStartDelayTime" 0;
BA_DEF_DEF_  "NmMessage" "No";
BA_DEF_DEF_  "NmhMessage" "No";
BA_DEF_DEF_  "MsgType" "Application";
BA_DEF_DEF_  "VAGTP20_API" 0;
BA_DEF_DEF_  "VAGTP20_DynConnection" "No";
BA_DEF_DEF_  "VAGTP20_DynSetup" "No";
BA_DEF_DEF_  "VAGTP20_StatConnection" "No";
BA_DEF_DEF_  "GenSigActiveRepetitions" 0;
BA_DEF_DEF_  "GenSigInactiveValue" 0;
BA_DEF_DEF_  "GenSigSendType" "NoSigSendType";
BA_DEF_DEF_  "GenSigStartValue" 0;
BA_DEF_DEF_  "NWM-WakeupAllowed" "No";
BA_DEF_DEF_  "GenSigFuncType" "NoFunction";
BA_DEF_DEF_  "GenSigSwitchedByIgnition" "Yes";
BA_DEF_DEF_  "Fehlerwert" 0;
BA_DEF_DEF_  "GenSigMissingSourceValue" 0;
BA_ "GenMsgCycleTime" BO_ 886 1000;
BA_ "GenMsgILSupport" BO_ 886 1;
BA_ "GenMsgSendType" BO_ 886 0;
BA_ "GenMsgCycleTime" BO_ 888 1000;
BA_ "GenMsgILSupport" BO_ 888 1;
BA_ "GenMsgSendType" BO_ 888 0;
BA_ "GenMsgCycleTime" BO_ 891 1000;
BA_ "GenMsgILSupport" BO_ 891 1;
BA_ "GenMsgSendType" BO_ 891 0;
BA_ "GenMsgCycleTime" BO_ 1364 1000;
BA_ "GenMsgILSupport" BO_ 1364 1;
BA_ "GenMsgSendType" BO_ 1364 0;
BA_ "GenMsgCycleTime" BO_ 1343 1000;
BA_ "GenMsgILSupport" BO_ 1343 1;
BA_ "GenMsgSendType" BO_ 1343 0;
BA_ "GenMsgCycleTime" BO_ 2463978722 100;
BA_ "GenMsgILSupport" BO_ 2463978722 1;
BA_ "GenMsgSendType" BO_ 2463978722 0;
BA_ "GenMsgCycleTime" BO_ 2463978723 100;
BA_ "GenMsgILSupport" BO_ 2463978723 1;
BA_ "GenMsgSendType" BO_ 2463978723 0;
BA_ "GenMsgCycleTime" BO_ 2463978724 100;
BA_ "GenMsgILSupport" BO_ 2463978724 1;
BA_ "GenMsgSendType" BO_ 2463978724 0;
BA_ "GenMsgCycleTime" BO_ 2463978726 100;
BA_ "GenMsgILSupport" BO_ 2463978726 1;
BA_ "GenMsgSendType" BO_ 2463978726 0;
BA_ "GenMsgCycleTime" BO_ 299 30;
BA_ "GenMsgILSupport" BO_ 299 1;
BA_ "GenMsgPDUConstants" BO_ 299 "0x6a,0x38,0xb4,0x27,0x22,0xef,0xe1,0xbb,0xf8,0x80,0x84,0x49,0xc7,0x9e,0x1e,0x2b";
BA_ "GenMsgSendType" BO_ 299 0;
BA_ "MsgType" BO_ 2583720728 4;
BA_ "MsgType" BO_ 2583851800 4;
BA_ "DiagRequest" BO_ 1895 1;
BA_ "MsgType" BO_ 1895 4;
BA_ "DiagResponse" BO_ 2001 1;
BA_ "MsgType" BO_ 2001 4;
BA_ "MsgType" BO_ 2549351183 4;
BA_ "MsgType" BO_ 2549485315 4;
BA_ "DiagState" BO_ 1792 1;
BA_ "MsgType" BO_ 1792 4;
BA_ "DiagRequest" BO_ 1907 1;
BA_ "MsgType" BO_ 1907 4;
BA_ "DiagResponse" BO_ 2013 1;
BA_ "MsgType" BO_ 2013 4;
BA_ "MsgType" BO_ 2549354243 4;
BA_ "MsgType" BO_ 2549482255 4;
BA_ "DiagRequest" BO_ 1803 1;
BA_ "MsgType" BO_ 1803 4;
BA_ "DiagResponse" BO_ 1909 1;
BA_ "MsgType" BO_ 1909 4;
BA_ "DiagRequest" BO_ 1898 1;
BA_ "MsgType" BO_ 1898 4;
BA_ "DiagResponse" BO_ 2004 1;
BA_ "MsgType" BO_ 2004 4;
BA_ "DiagRequest" BO_ 1901 1;
BA_ "MsgType" BO_ 1901 4;
BA_ "DiagResponse" BO_ 2007 1;
BA_ "MsgType" BO_ 2007 4;
BA_ "DiagRequest" BO_ 2550399028 1;
BA_ "MsgType" BO_ 2550399028 4;
BA_ "DiagResponse" BO_ 2550530100 1;
BA_ "MsgType" BO_ 2550530100 4;
BA_ "DiagRequest" BO_ 2549874850 1;
BA_ "MsgType" BO_ 2549874850 4;
BA_ "DiagResponse" BO_ 2550005922 1;
BA_ "MsgType" BO_ 2550005922 4;
BA_ "DiagRequest" BO_ 2549874852 1;
BA_ "MsgType" BO_ 2549874852 4;
BA_ "DiagResponse" BO_ 2550005924 1;
BA_ "MsgType" BO_ 2550005924 4;
BA_ "DiagRequest" BO_ 2549874853 1;
BA_ "MsgType" BO_ 2549874853 4;
BA_ "DiagResponse" BO_ 2550005925 1;
BA_ "MsgType" BO_ 2550005925 4;
BA_ "GenMsgCycleTime" BO_ 1426 200;
BA_ "GenMsgDelayTime" BO_ 1426 20;
BA_ "GenMsgILSupport" BO_ 1426 1;
BA_ "GenMsgSendType" BO_ 1426 0;
BA_ "GenMsgChkConstant" BO_ 960 195;
BA_ "GenMsgCycleTime" BO_ 960 100;
BA_ "GenMsgDelayTime" BO_ 960 10;
BA_ "GenMsgILSupport" BO_ 960 1;
BA_ "GenMsgPDUConstants" BO_ 960 "0xc3,0xc3,0xc3,0xc3,0xc3,0xc3,0xc3,0xc3,0xc3,0xc3,0xc3,0xc3,0xc3,0xc3,0xc3,0xc3";
BA_ "GenMsgSendType" BO_ 960 0;
BA_ "GenMsgCycleTime" BO_ 2463978753 1000;
BA_ "GenMsgCycleTimeFast" BO_ 2463978753 100;
BA_ "GenMsgDelayTime" BO_ 2463978753 10;
BA_ "GenMsgILSupport" BO_ 2463978753 1;
BA_ "GenMsgNrOfRepetition" BO_ 2463978753 5;
BA_ "GenMsgPDUConstants" BO_ 2463978753 "0x80,0xf1,0xa5,0xaf,0x94,0x59,0xe8,0x8c,0x03,0xd4,0xf5,0x5e,0xec,0x73,0x81,0x50";
BA_ "GenMsgSendType" BO_ 2463978753 0;
BA_ "GenMsgCycleTime" BO_ 1646 2000;
BA_ "GenMsgDelayTime" BO_ 1646 200;
BA_ "GenMsgILSupport" BO_ 1646 1;
BA_ "GenMsgSendType" BO_ 1646 0;
BA_ "GenMsgCycleTime" BO_ 1649 2000;
BA_ "GenMsgDelayTime" BO_ 1649 200;
BA_ "GenMsgILSupport" BO_ 1649 1;
BA_ "GenMsgSendType" BO_ 1649 0;
BA_ "GenMsgCycleTime" BO_ 949 100;
BA_ "GenMsgILSupport" BO_ 949 1;
BA_ "GenMsgSendType" BO_ 949 0;
BA_ "GenMsgCycleTime" BO_ 1640 200;
BA_ "GenMsgCycleTimeFast" BO_ 1640 100;
BA_ "GenMsgDelayTime" BO_ 1640 50;
BA_ "GenMsgILSupport" BO_ 1640 1;
BA_ "GenMsgNrOfRepetition" BO_ 1640 5;
BA_ "GenMsgSendType" BO_ 1640 0;
BA_ "GenMsgCycleTime" BO_ 2527679635 2000;
BA_ "GenMsgDelayTime" BO_ 2527679635 200;
BA_ "GenMsgILSupport" BO_ 2527679635 1;
BA_ "GenMsgSendType" BO_ 2527679635 0;
BA_ "GenMsgCycleTime" BO_ 2589283627 500;
BA_ "GenMsgILSupport" BO_ 2589283627 1;
BA_ "GenMsgSendType" BO_ 2589283627 0;
BA_ "GenMsgCycleTime" BO_ 1712 500;
BA_ "GenMsgILSupport" BO_ 1712 1;
BA_ "GenMsgSendType" BO_ 1712 0;
BA_ "GenMsgCycleTime" BO_ 1505 200;
BA_ "GenMsgILSupport" BO_ 1505 1;
BA_ "GenMsgSendType" BO_ 1505 0;
BA_ "GenMsgCycleTime" BO_ 1717 500;
BA_ "GenMsgILSupport" BO_ 1717 1;
BA_ "GenMsgSendType" BO_ 1717 0;
BA_ "GenMsgCycleTime" BO_ 2549088367 500;
BA_ "GenMsgILSupport" BO_ 2549088367 1;
BA_ "GenMsgSendType" BO_ 2549088367 0;
BA_ "GenMsgCycleTime" BO_ 2549088564 500;
BA_ "GenMsgILSupport" BO_ 2549088564 1;
BA_ "GenMsgSendType" BO_ 2549088564 0;
BA_ "GenMsgCycleTime" BO_ 2549088418 500;
BA_ "GenMsgILSupport" BO_ 2549088418 1;
BA_ "GenMsgSendType" BO_ 2549088418 0;
BA_ "GenMsgCycleTime" BO_ 2549088570 500;
BA_ "GenMsgILSupport" BO_ 2549088570 1;
BA_ "GenMsgSendType" BO_ 2549088570 0;
BA_ "GenMsgCycleTime" BO_ 2549088359 500;
BA_ "GenMsgILSupport" BO_ 2549088359 1;
BA_ "GenMsgSendType" BO_ 2549088359 0;
BA_ "GenMsgCycleTime" BO_ 2549088272 500;
BA_ "GenMsgILSupport" BO_ 2549088272 1;
BA_ "GenMsgSendType" BO_ 2549088272 0;
BA_ "GenSigSendType" SG_ 886 GNSS_Nachrichtenpaket_ID3 0;
BA_ "GenSigSwitchedByIgnition" SG_ 886 GNSS_Nachrichtenpaket_ID3 0;
BA_ "GenSigSendType" SG_ 886 GNSS_Ortung_GDOP 0;
BA_ "GenSigStartValue" SG_ 886 GNSS_Ortung_GDOP 510;
BA_ "GenSigSwitchedByIgnition" SG_ 886 GNSS_Ortung_GDOP 0;
BA_ "Fehlerwert" SG_ 886 GNSS_Ortung_GDOP 511;
BA_ "GenSigSendType" SG_ 886 GNSS_Ortung_Guete_Ausrichtung 0;
BA_ "GenSigStartValue" SG_ 886 GNSS_Ortung_Guete_Ausrichtung 62;
BA_ "GenSigSwitchedByIgnition" SG_ 886 GNSS_Ortung_Guete_Ausrichtung 0;
BA_ "Fehlerwert" SG_ 886 GNSS_Ortung_Guete_Ausrichtung 63;
BA_ "GenSigSendType" SG_ 886 GNSS_Ortung_Guete_Geschwindigk 0;
BA_ "GenSigStartValue" SG_ 886 GNSS_Ortung_Guete_Geschwindigk 62;
BA_ "GenSigSwitchedByIgnition" SG_ 886 GNSS_Ortung_Guete_Geschwindigk 0;
BA_ "Fehlerwert" SG_ 886 GNSS_Ortung_Guete_Geschwindigk 63;
BA_ "GenSigSendType" SG_ 886 GNSS_Ortung_Guete_horizontal 0;
BA_ "GenSigStartValue" SG_ 886 GNSS_Ortung_Guete_horizontal 254;
BA_ "GenSigSwitchedByIgnition" SG_ 886 GNSS_Ortung_Guete_horizontal 0;
BA_ "Fehlerwert" SG_ 886 GNSS_Ortung_Guete_horizontal 255;
BA_ "GenSigSendType" SG_ 886 GNSS_Ortung_Guete_vertikal 0;
BA_ "GenSigStartValue" SG_ 886 GNSS_Ortung_Guete_vertikal 62;
BA_ "GenSigSwitchedByIgnition" SG_ 886 GNSS_Ortung_Guete_vertikal 0;
BA_ "Fehlerwert" SG_ 886 GNSS_Ortung_Guete_vertikal 63;
BA_ "GenSigSendType" SG_ 886 GNSS_Ortung_HDOP 0;
BA_ "GenSigStartValue" SG_ 886 GNSS_Ortung_HDOP 510;
BA_ "GenSigSwitchedByIgnition" SG_ 886 GNSS_Ortung_HDOP 0;
BA_ "Fehlerwert" SG_ 886 GNSS_Ortung_HDOP 511;
BA_ "GenSigSendType" SG_ 886 GNSS_Ortung_PDOP 0;
BA_ "GenSigStartValue" SG_ 886 GNSS_Ortung_PDOP 510;
BA_ "GenSigSwitchedByIgnition" SG_ 886 GNSS_Ortung_PDOP 0;
BA_ "Fehlerwert" SG_ 886 GNSS_Ortung_PDOP 511;
BA_ "GenSigSendType" SG_ 886 GNSS_Ortung_VDOP 0;
BA_ "GenSigStartValue" SG_ 886 GNSS_Ortung_VDOP 510;
BA_ "GenSigSwitchedByIgnition" SG_ 886 GNSS_Ortung_VDOP 0;
BA_ "Fehlerwert" SG_ 886 GNSS_Ortung_VDOP 511;
BA_ "GenSigSendType" SG_ 888 GNSS_Nachrichtenpaket_ID4 0;
BA_ "GenSigSwitchedByIgnition" SG_ 888 GNSS_Nachrichtenpaket_ID4 0;
BA_ "GenSigSendType" SG_ 888 GNSS_Ortung_Hoehe 0;
BA_ "GenSigStartValue" SG_ 888 GNSS_Ortung_Hoehe 4094;
BA_ "GenSigSwitchedByIgnition" SG_ 888 GNSS_Ortung_Hoehe 0;
BA_ "Fehlerwert" SG_ 888 GNSS_Ortung_Hoehe 4095;
BA_ "GenSigSendType" SG_ 888 GNSS_Ortung_Zeit_in_GPSWoche 0;
BA_ "GenSigStartValue" SG_ 888 GNSS_Ortung_Zeit_in_GPSWoche 1073741822;
BA_ "GenSigSwitchedByIgnition" SG_ 888 GNSS_Ortung_Zeit_in_GPSWoche 0;
BA_ "Fehlerwert" SG_ 888 GNSS_Ortung_Zeit_in_GPSWoche 1073741823;
BA_ "GenSigSendType" SG_ 891 GNSS_Empfaenger_Status 0;
BA_ "GenSigSwitchedByIgnition" SG_ 891 GNSS_Empfaenger_Status 0;
BA_ "GenSigSendType" SG_ 891 GNSS_Empfangbare_Satelliten 0;
BA_ "GenSigSwitchedByIgnition" SG_ 891 GNSS_Empfangbare_Satelliten 0;
BA_ "GenSigSendType" SG_ 891 GNSS_Genutzte_Satelliten 0;
BA_ "GenSigSwitchedByIgnition" SG_ 891 GNSS_Genutzte_Satelliten 0;
BA_ "GenSigSendType" SG_ 891 GNSS_GLONASS_in_Nutzung 0;
BA_ "GenSigSwitchedByIgnition" SG_ 891 GNSS_GLONASS_in_Nutzung 0;
BA_ "GenSigSendType" SG_ 891 GNSS_GPS_in_Nutzung 0;
BA_ "GenSigSwitchedByIgnition" SG_ 891 GNSS_GPS_in_Nutzung 0;
BA_ "GenSigSendType" SG_ 891 GNSS_Nachrichtenpaket_ID5 0;
BA_ "GenSigSwitchedByIgnition" SG_ 891 GNSS_Nachrichtenpaket_ID5 0;
BA_ "GenSigSendType" SG_ 891 GNSS_Sichtbare_Satelliten 0;
BA_ "GenSigSwitchedByIgnition" SG_ 891 GNSS_Sichtbare_Satelliten 0;
BA_ "GenSigSendType" SG_ 891 GNSS_UTC_Zeit 0;
BA_ "GenSigSwitchedByIgnition" SG_ 891 GNSS_UTC_Zeit 0;
BA_ "GenSigSendType" SG_ 1364 GNSS_Nachrichtenpaket_ID6 0;
BA_ "GenSigSwitchedByIgnition" SG_ 1364 GNSS_Nachrichtenpaket_ID6 0;
BA_ "GenSigSendType" SG_ 1364 GNSS_Sat_Info_Azimuth_ID_1 0;
BA_ "GenSigStartValue" SG_ 1364 GNSS_Sat_Info_Azimuth_ID_1 511;
BA_ "GenSigSwitchedByIgnition" SG_ 1364 GNSS_Sat_Info_Azimuth_ID_1 0;
BA_ "GenSigSendType" SG_ 1364 GNSS_Sat_Info_Hoehenwinkel_ID_1 0;
BA_ "GenSigStartValue" SG_ 1364 GNSS_Sat_Info_Hoehenwinkel_ID_1 127;
BA_ "GenSigSwitchedByIgnition" SG_ 1364 GNSS_Sat_Info_Hoehenwinkel_ID_1 0;
BA_ "GenSigSendType" SG_ 1364 GNSS_Sat_Info_Sat_ID_1 0;
BA_ "GenSigSwitchedByIgnition" SG_ 1364 GNSS_Sat_Info_Sat_ID_1 0;
BA_ "GenSigSendType" SG_ 1364 GNSS_Sat_Info_SNR_ID_1 0;
BA_ "GenSigStartValue" SG_ 1364 GNSS_Sat_Info_SNR_ID_1 31;
BA_ "GenSigSwitchedByIgnition" SG_ 1364 GNSS_Sat_Info_SNR_ID_1 0;
BA_ "GenSigSendType" SG_ 1343 GNSS_Nachrichtenpaket_ID7 0;
BA_ "GenSigSwitchedByIgnition" SG_ 1343 GNSS_Nachrichtenpaket_ID7 0;
BA_ "GenSigSendType" SG_ 1343 GNSS_V_Daten_Veraltet 0;
BA_ "GenSigSwitchedByIgnition" SG_ 1343 GNSS_V_Daten_Veraltet 0;
BA_ "GenSigSendType" SG_ 1343 GNSS_V_FIX_Typ 0;
BA_ "GenSigSwitchedByIgnition" SG_ 1343 GNSS_V_FIX_Typ 0;
BA_ "GenSigSendType" SG_ 1343 GNSS_V_Geschw_2D 0;
BA_ "GenSigStartValue" SG_ 1343 GNSS_V_Geschw_2D 16382;
BA_ "GenSigSwitchedByIgnition" SG_ 1343 GNSS_V_Geschw_2D 0;
BA_ "Fehlerwert" SG_ 1343 GNSS_V_Geschw_2D 16383;
BA_ "GenSigSendType" SG_ 1343 GNSS_V_Geschw_2D_Guete95 0;
BA_ "GenSigStartValue" SG_ 1343 GNSS_V_Geschw_2D_Guete95 1022;
BA_ "GenSigSwitchedByIgnition" SG_ 1343 GNSS_V_Geschw_2D_Guete95 0;
BA_ "Fehlerwert" SG_ 1343 GNSS_V_Geschw_2D_Guete95 1023;
BA_ "GenSigSendType" SG_ 1343 GNSS_V_Geschw_Vertikal 0;
BA_ "GenSigStartValue" SG_ 1343 GNSS_V_Geschw_Vertikal 32766;
BA_ "GenSigSwitchedByIgnition" SG_ 1343 GNSS_V_Geschw_Vertikal 0;
BA_ "Fehlerwert" SG_ 1343 GNSS_V_Geschw_Vertikal 32767;
BA_ "GenSigSendType" SG_ 1343 GNSS_V_Geschw_Vertikal_Guete95 0;
BA_ "GenSigStartValue" SG_ 1343 GNSS_V_Geschw_Vertikal_Guete95 1022;
BA_ "GenSigSwitchedByIgnition" SG_ 1343 GNSS_V_Geschw_Vertikal_Guete95 0;
BA_ "Fehlerwert" SG_ 1343 GNSS_V_Geschw_Vertikal_Guete95 1023;
BA_ "GenSigSendType" SG_ 1343 GNSS_V_Latenz_vollstaendig 0;
BA_ "GenSigStartValue" SG_ 1343 GNSS_V_Latenz_vollstaendig 1022;
BA_ "GenSigSwitchedByIgnition" SG_ 1343 GNSS_V_Latenz_vollstaendig 0;
BA_ "Fehlerwert" SG_ 1343 GNSS_V_Latenz_vollstaendig 1023;
BA_ "GenSigSendType" SG_ 2463978722 GNSS_DR_Breite_Ortung 0;
BA_ "GenSigStartValue" SG_ 2463978722 GNSS_DR_Breite_Ortung 134217726;
BA_ "GenSigSwitchedByIgnition" SG_ 2463978722 GNSS_DR_Breite_Ortung 0;
BA_ "Fehlerwert" SG_ 2463978722 GNSS_DR_Breite_Ortung 134217727;
BA_ "GenSigSendType" SG_ 2463978722 GNSS_DR_Laenge_Ortung 0;
BA_ "GenSigStartValue" SG_ 2463978722 GNSS_DR_Laenge_Ortung 268435454;
BA_ "GenSigSwitchedByIgnition" SG_ 2463978722 GNSS_DR_Laenge_Ortung 0;
BA_ "Fehlerwert" SG_ 2463978722 GNSS_DR_Laenge_Ortung 268435455;
BA_ "GenSigSendType" SG_ 2463978722 GNSS_DR_Nachrichtenpaket_ID1 0;
BA_ "GenSigSwitchedByIgnition" SG_ 2463978722 GNSS_DR_Nachrichtenpaket_ID1 0;
BA_ "GenSigSendType" SG_ 2463978722 GNSS_DR_Richtung_Breite_Ortung 0;
BA_ "GenSigStartValue" SG_ 2463978722 GNSS_DR_Richtung_Breite_Ortung 1;
BA_ "GenSigSwitchedByIgnition" SG_ 2463978722 GNSS_DR_Richtung_Breite_Ortung 0;
BA_ "GenSigSendType" SG_ 2463978722 GNSS_DR_Richtung_Laenge_Ortung 0;
BA_ "GenSigStartValue" SG_ 2463978722 GNSS_DR_Richtung_Laenge_Ortung 1;
BA_ "GenSigSwitchedByIgnition" SG_ 2463978722 GNSS_DR_Richtung_Laenge_Ortung 0;
BA_ "GenSigSendType" SG_ 2463978723 GNSS_DR_Nachrichtenpaket_ID2 0;
BA_ "GenSigSwitchedByIgnition" SG_ 2463978723 GNSS_DR_Nachrichtenpaket_ID2 0;
BA_ "GenSigSendType" SG_ 2463978723 GNSS_DR_Ortung_2D_Geschw_u_Grund 0;
BA_ "GenSigStartValue" SG_ 2463978723 GNSS_DR_Ortung_2D_Geschw_u_Grund 510;
BA_ "GenSigSwitchedByIgnition" SG_ 2463978723 GNSS_DR_Ortung_2D_Geschw_u_Grund 0;
BA_ "Fehlerwert" SG_ 2463978723 GNSS_DR_Ortung_2D_Geschw_u_Grund 511;
BA_ "GenSigSendType" SG_ 2463978723 GNSS_DR_Ortung_Ausrichtung 0;
BA_ "GenSigStartValue" SG_ 2463978723 GNSS_DR_Ortung_Ausrichtung 4094;
BA_ "GenSigSwitchedByIgnition" SG_ 2463978723 GNSS_DR_Ortung_Ausrichtung 0;
BA_ "Fehlerwert" SG_ 2463978723 GNSS_DR_Ortung_Ausrichtung 4095;
BA_ "GenSigSendType" SG_ 2463978724 GNSS_DR_Nachrichtenpaket_ID3 0;
BA_ "GenSigSwitchedByIgnition" SG_ 2463978724 GNSS_DR_Nachrichtenpaket_ID3 0;
BA_ "GenSigSendType" SG_ 2463978724 GNSS_DR_Ortung_Guete_Ausrichtung 0;
BA_ "GenSigStartValue" SG_ 2463978724 GNSS_DR_Ortung_Guete_Ausrichtung 62;
BA_ "GenSigSwitchedByIgnition" SG_ 2463978724 GNSS_DR_Ortung_Guete_Ausrichtung 0;
BA_ "Fehlerwert" SG_ 2463978724 GNSS_DR_Ortung_Guete_Ausrichtung 63;
BA_ "GenSigSendType" SG_ 2463978724 GNSS_DR_Ortung_Guete_Geschwindig 0;
BA_ "GenSigStartValue" SG_ 2463978724 GNSS_DR_Ortung_Guete_Geschwindig 62;
BA_ "GenSigSwitchedByIgnition" SG_ 2463978724 GNSS_DR_Ortung_Guete_Geschwindig 0;
BA_ "Fehlerwert" SG_ 2463978724 GNSS_DR_Ortung_Guete_Geschwindig 63;
BA_ "GenSigSendType" SG_ 2463978724 GNSS_DR_Ortung_Guete_horizontal 0;
BA_ "GenSigStartValue" SG_ 2463978724 GNSS_DR_Ortung_Guete_horizontal 254;
BA_ "GenSigSwitchedByIgnition" SG_ 2463978724 GNSS_DR_Ortung_Guete_horizontal 0;
BA_ "Fehlerwert" SG_ 2463978724 GNSS_DR_Ortung_Guete_horizontal 255;
BA_ "GenSigSendType" SG_ 2463978724 GNSS_DR_Ortung_Guete_vertikal 0;
BA_ "GenSigStartValue" SG_ 2463978724 GNSS_DR_Ortung_Guete_vertikal 62;
BA_ "GenSigSwitchedByIgnition" SG_ 2463978724 GNSS_DR_Ortung_Guete_vertikal 0;
BA_ "Fehlerwert" SG_ 2463978724 GNSS_DR_Ortung_Guete_vertikal 63;
BA_ "GenSigSendType" SG_ 2463978726 GNSS_DR_UTC_Zeit 0;
BA_ "GenSigSwitchedByIgnition" SG_ 2463978726 GNSS_DR_UTC_Zeit 0;
BA_ "GenSigSendType" SG_ 299 GRA_Abbrechen 0;
BA_ "GenSigSendType" SG_ 299 GRA_ACC_01_BZ 0;
BA_ "GenSigFuncType" SG_ 299 GRA_ACC_01_BZ 1;
BA_ "GenSigSendType" SG_ 299 GRA_ACC_01_CRC 0;
BA_ "GenSigFuncType" SG_ 299 GRA_ACC_01_CRC 2;
BA_ "GenSigSendType" SG_ 299 GRA_Codierung 0;
BA_ "GenSigSendType" SG_ 299 GRA_Fehler 0;
BA_ "Fehlerwert" SG_ 299 GRA_Fehler 1;
BA_ "GenSigSendType" SG_ 299 GRA_Hauptschalter 0;
BA_ "GenSigSendType" SG_ 299 GRA_LIM_Taste_verfuegbar 0;
BA_ "GenSigFuncType" SG_ 299 GRA_LIM_Taste_verfuegbar 8;
BA_ "GenSigSendType" SG_ 299 GRA_Limiter 0;
BA_ "GenSigSendType" SG_ 299 GRA_PIT_Limiter 0;
BA_ "GenSigSwitchedByIgnition" SG_ 299 GRA_PIT_Limiter 0;
BA_ "GenSigSendType" SG_ 299 GRA_reserveByte5 0;
BA_ "GenSigSendType" SG_ 299 GRA_reserveByte6 0;
BA_ "GenSigSendType" SG_ 299 GRA_reserveByte7 0;
BA_ "GenSigSendType" SG_ 299 GRA_reserveByte8 0;
BA_ "GenSigSendType" SG_ 299 GRA_Tip_Hoch 0;
BA_ "GenSigSendType" SG_ 299 GRA_Tip_Runter 0;
BA_ "GenSigSendType" SG_ 299 GRA_Tip_Setzen 0;
BA_ "GenSigSendType" SG_ 299 GRA_Tip_Stufe_2 0;
BA_ "GenSigSendType" SG_ 299 GRA_Tip_Wiederaufnahme 0;
BA_ "GenSigSendType" SG_ 299 GRA_TravelAssist 0;
BA_ "GenSigSwitchedByIgnition" SG_ 299 GRA_TravelAssist 0;
BA_ "GenSigSendType" SG_ 299 GRA_Typ_Bedienteil 0;
BA_ "GenSigSendType" SG_ 299 GRA_Typ_Hauptschalter 0;
BA_ "GenSigSendType" SG_ 299 GRA_Verstellung_Zeitluecke 0;
BA_ "GenSigSwitchedByIgnition" SG_ 29 WFS_IMMO_OCU_CRC 0;
BA_ "GenSigSwitchedByIgnition" SG_ 29 WFS_IMMO_OCU_RND 0;
BA_ "GenSigSendType" SG_ 2583720728 Info_El_AuthTime_Req_Data 3;
BA_ "GenSigFuncType" SG_ 2583720728 Info_El_AuthTime_Req_Data 9;
BA_ "GenSigSwitchedByIgnition" SG_ 2583720728 Info_El_AuthTime_Req_Data 0;
BA_ "GenSigSendType" SG_ 2583851800 Info_El_AuthTime_Resp_Data 3;
BA_ "GenSigFuncType" SG_ 2583851800 Info_El_AuthTime_Resp_Data 9;
BA_ "GenSigSwitchedByIgnition" SG_ 2583851800 Info_El_AuthTime_Resp_Data 0;
BA_ "GenSigSendType" SG_ 1895 ISO_eCall_Req_Data 3;
BA_ "GenSigFuncType" SG_ 1895 ISO_eCall_Req_Data 9;
BA_ "GenSigSwitchedByIgnition" SG_ 1895 ISO_eCall_Req_Data 0;
BA_ "GenSigSendType" SG_ 2001 ISO_eCall_Resp_Data 3;
BA_ "GenSigFuncType" SG_ 2001 ISO_eCall_Resp_Data 9;
BA_ "GenSigSwitchedByIgnition" SG_ 2001 ISO_eCall_Resp_Data 0;
BA_ "GenSigSendType" SG_ 2549351183 ISO_FoD_ManFoD_Req_Data 3;
BA_ "GenSigFuncType" SG_ 2549351183 ISO_FoD_ManFoD_Req_Data 9;
BA_ "GenSigSwitchedByIgnition" SG_ 2549351183 ISO_FoD_ManFoD_Req_Data 0;
BA_ "GenSigSendType" SG_ 2549485315 ISO_FoD_ManFoD_Resp_Data 3;
BA_ "GenSigFuncType" SG_ 2549485315 ISO_FoD_ManFoD_Resp_Data 9;
BA_ "GenSigSwitchedByIgnition" SG_ 2549485315 ISO_FoD_ManFoD_Resp_Data 0;
BA_ "GenSigSendType" SG_ 1792 ISO_ALL_01_Req_Data 3;
BA_ "GenSigFuncType" SG_ 1792 ISO_ALL_01_Req_Data 9;
BA_ "GenSigSwitchedByIgnition" SG_ 1792 ISO_ALL_01_Req_Data 0;
BA_ "GenSigSendType" SG_ 1907 ISO_Info_El_Req_Data 3;
BA_ "GenSigFuncType" SG_ 1907 ISO_Info_El_Req_Data 9;
BA_ "GenSigSwitchedByIgnition" SG_ 1907 ISO_Info_El_Req_Data 0;
BA_ "GenSigSendType" SG_ 2013 ISO_Info_El_Resp_Data 3;
BA_ "GenSigFuncType" SG_ 2013 ISO_Info_El_Resp_Data 9;
BA_ "GenSigSwitchedByIgnition" SG_ 2013 ISO_Info_El_Resp_Data 0;
BA_ "GenSigSendType" SG_ 2549354243 ISO_ManFoD_FoD_Req_Data 3;
BA_ "GenSigFuncType" SG_ 2549354243 ISO_ManFoD_FoD_Req_Data 9;
BA_ "GenSigSwitchedByIgnition" SG_ 2549354243 ISO_ManFoD_FoD_Req_Data 0;
BA_ "GenSigSendType" SG_ 2549482255 ISO_ManFoD_FoD_Resp_Data 3;
BA_ "GenSigFuncType" SG_ 2549482255 ISO_ManFoD_FoD_Resp_Data 9;
BA_ "GenSigSwitchedByIgnition" SG_ 2549482255 ISO_ManFoD_FoD_Resp_Data 0;
BA_ "GenSigSendType" SG_ 1803 ISO_RDK_Req_Data 3;
BA_ "GenSigFuncType" SG_ 1803 ISO_RDK_Req_Data 9;
BA_ "GenSigSwitchedByIgnition" SG_ 1803 ISO_RDK_Req_Data 0;
BA_ "GenSigSendType" SG_ 1909 ISO_RDK_Resp_Data 3;
BA_ "GenSigFuncType" SG_ 1909 ISO_RDK_Resp_Data 9;
BA_ "GenSigSwitchedByIgnition" SG_ 1909 ISO_RDK_Resp_Data 0;
BA_ "GenSigSendType" SG_ 1898 ISO_STH_Req_Data 3;
BA_ "GenSigFuncType" SG_ 1898 ISO_STH_Req_Data 9;
BA_ "GenSigSwitchedByIgnition" SG_ 1898 ISO_STH_Req_Data 0;
BA_ "GenSigSendType" SG_ 2004 ISO_STH_Resp_Data 3;
BA_ "GenSigFuncType" SG_ 2004 ISO_STH_Resp_Data 9;
BA_ "GenSigSwitchedByIgnition" SG_ 2004 ISO_STH_Resp_Data 0;
BA_ "GenSigSendType" SG_ 1901 ISO_TV_Tuner_Req_Data 3;
BA_ "GenSigFuncType" SG_ 1901 ISO_TV_Tuner_Req_Data 9;
BA_ "GenSigSwitchedByIgnition" SG_ 1901 ISO_TV_Tuner_Req_Data 0;
BA_ "GenSigSendType" SG_ 2007 ISO_TV_Tuner_Resp_Data 3;
BA_ "GenSigFuncType" SG_ 2007 ISO_TV_Tuner_Resp_Data 9;
BA_ "GenSigSwitchedByIgnition" SG_ 2007 ISO_TV_Tuner_Resp_Data 0;
BA_ "GenSigSendType" SG_ 2550399028 ISOx_BedienDisp_m_Req_Data 3;
BA_ "GenSigFuncType" SG_ 2550399028 ISOx_BedienDisp_m_Req_Data 9;
BA_ "GenSigSwitchedByIgnition" SG_ 2550399028 ISOx_BedienDisp_m_Req_Data 0;
BA_ "GenSigSendType" SG_ 2550530100 ISOx_BedienDisp_m_Resp_Data 3;
BA_ "GenSigFuncType" SG_ 2550530100 ISOx_BedienDisp_m_Resp_Data 9;
BA_ "GenSigSwitchedByIgnition" SG_ 2550530100 ISOx_BedienDisp_m_Resp_Data 0;
BA_ "GenSigSendType" SG_ 2549874850 ISOx_BedienDisp_vm_Req_Data 3;
BA_ "GenSigFuncType" SG_ 2549874850 ISOx_BedienDisp_vm_Req_Data 9;
BA_ "GenSigSwitchedByIgnition" SG_ 2549874850 ISOx_BedienDisp_vm_Req_Data 0;
BA_ "GenSigSendType" SG_ 2550005922 ISOx_BedienDisp_vm_Resp_Data 3;
BA_ "GenSigFuncType" SG_ 2550005922 ISOx_BedienDisp_vm_Resp_Data 9;
BA_ "GenSigSwitchedByIgnition" SG_ 2550005922 ISOx_BedienDisp_vm_Resp_Data 0;
BA_ "GenSigSendType" SG_ 2549874852 ISOx_LSH_Req_Data 3;
BA_ "GenSigFuncType" SG_ 2549874852 ISOx_LSH_Req_Data 9;
BA_ "GenSigSwitchedByIgnition" SG_ 2549874852 ISOx_LSH_Req_Data 0;
BA_ "GenSigSendType" SG_ 2550005924 ISOx_LSH_Resp_Data 3;
BA_ "GenSigFuncType" SG_ 2550005924 ISOx_LSH_Resp_Data 9;
BA_ "GenSigSwitchedByIgnition" SG_ 2550005924 ISOx_LSH_Resp_Data 0;
BA_ "GenSigSendType" SG_ 2549874853 ISOx_WLC1_Req_Data 3;
BA_ "GenSigFuncType" SG_ 2549874853 ISOx_WLC1_Req_Data 9;
BA_ "GenSigSwitchedByIgnition" SG_ 2549874853 ISOx_WLC1_Req_Data 0;
BA_ "GenSigSendType" SG_ 2550005925 ISOx_WLC1_Resp_Data 3;
BA_ "GenSigFuncType" SG_ 2550005925 ISOx_WLC1_Resp_Data 9;
BA_ "GenSigSwitchedByIgnition" SG_ 2550005925 ISOx_WLC1_Resp_Data 0;
BA_ "GenSigSendType" SG_ 1426 KY_Aktive_LFScans 3;
BA_ "GenSigSwitchedByIgnition" SG_ 1426 KY_Aktive_LFScans 0;
BA_ "GenSigSendType" SG_ 1426 KY_AnzKoord_Info 3;
BA_ "GenSigSwitchedByIgnition" SG_ 1426 KY_AnzKoord_Info 0;
BA_ "GenSigSendType" SG_ 1426 KY_EasyClose_Abbruch 3;
BA_ "GenSigSwitchedByIgnition" SG_ 1426 KY_EasyClose_Abbruch 0;
BA_ "GenSigSendType" SG_ 1426 KY_EasyClose_Status 3;
BA_ "GenSigSwitchedByIgnition" SG_ 1426 KY_EasyClose_Status 0;
BA_ "GenSigSendType" SG_ 1426 KY_Fzg_Verlassen_erkannt 3;
BA_ "GenSigSwitchedByIgnition" SG_ 1426 KY_Fzg_Verlassen_erkannt 0;
BA_ "GenSigSendType" SG_ 1426 KY_Fzg_Zugang_erkannt 3;
BA_ "GenSigSwitchedByIgnition" SG_ 1426 KY_Fzg_Zugang_erkannt 0;
BA_ "GenSigSendType" SG_ 1426 KY_Gestik_HD 3;
BA_ "GenSigSwitchedByIgnition" SG_ 1426 KY_Gestik_HD 0;
BA_ "GenSigSendType" SG_ 1426 KY_Gong_600 3;
BA_ "GenSigSwitchedByIgnition" SG_ 1426 KY_Gong_600 0;
BA_ "GenSigSendType" SG_ 1426 KY_HD_Auffahrt 3;
BA_ "GenSigSwitchedByIgnition" SG_ 1426 KY_HD_Auffahrt 0;
BA_ "GenSigSendType" SG_ 1426 KY_HD_Zufahrt 3;
BA_ "GenSigSwitchedByIgnition" SG_ 1426 KY_HD_Zufahrt 0;
BA_ "GenSigSendType" SG_ 1426 KY_ID_Geber1_im_Fzg 3;
BA_ "GenSigSwitchedByIgnition" SG_ 1426 KY_ID_Geber1_im_Fzg 0;
BA_ "GenSigSendType" SG_ 1426 KY_ID_Geber2_im_Fzg 3;
BA_ "GenSigSwitchedByIgnition" SG_ 1426 KY_ID_Geber2_im_Fzg 0;
BA_ "GenSigSendType" SG_ 1426 KY_ID_Geber3_im_Fzg 3;
BA_ "GenSigSwitchedByIgnition" SG_ 1426 KY_ID_Geber3_im_Fzg 0;
BA_ "GenSigSendType" SG_ 1426 KY_ID_Geber4_im_Fzg 3;
BA_ "GenSigSwitchedByIgnition" SG_ 1426 KY_ID_Geber4_im_Fzg 0;
BA_ "GenSigSendType" SG_ 1426 KY_ID_Geber_Suche 3;
BA_ "GenSigSwitchedByIgnition" SG_ 1426 KY_ID_Geber_Suche 0;
BA_ "GenSigSendType" SG_ 1426 KY_LF_Aktiv 3;
BA_ "GenSigSwitchedByIgnition" SG_ 1426 KY_LF_Aktiv 0;
BA_ "GenSigSendType" SG_ 1426 KY_Meldungen 3;
BA_ "GenSigSwitchedByIgnition" SG_ 1426 KY_Meldungen 0;
BA_ "GenSigSendType" SG_ 1426 KY_Passiv_Autolock 3;
BA_ "GenSigSwitchedByIgnition" SG_ 1426 KY_Passiv_Autolock 0;
BA_ "GenSigSendType" SG_ 1426 KY_Passiv_Autolock_Akt 3;
BA_ "GenSigSwitchedByIgnition" SG_ 1426 KY_Passiv_Autolock_Akt 0;
BA_ "GenSigSendType" SG_ 1426 KY_Passiv_Autolock_Menue 3;
BA_ "GenSigSwitchedByIgnition" SG_ 1426 KY_Passiv_Autolock_Menue 0;
BA_ "GenSigSendType" SG_ 1426 KY_Passiv_Autounlock 3;
BA_ "GenSigSwitchedByIgnition" SG_ 1426 KY_Passiv_Autounlock 0;
BA_ "GenSigSendType" SG_ 1426 KY_Schluesselposition_1 3;
BA_ "GenSigSwitchedByIgnition" SG_ 1426 KY_Schluesselposition_1 0;
BA_ "GenSigSendType" SG_ 1426 KY_Schluesselposition_2 3;
BA_ "GenSigSwitchedByIgnition" SG_ 1426 KY_Schluesselposition_2 0;
BA_ "GenSigSendType" SG_ 1426 KY_Schluesselposition_3 3;
BA_ "GenSigSwitchedByIgnition" SG_ 1426 KY_Schluesselposition_3 0;
BA_ "GenSigSendType" SG_ 1426 KY_Schluesselposition_4 3;
BA_ "GenSigSwitchedByIgnition" SG_ 1426 KY_Schluesselposition_4 0;
BA_ "GenSigSendType" SG_ 1426 KY_Schluesselposition_5 3;
BA_ "GenSigSwitchedByIgnition" SG_ 1426 KY_Schluesselposition_5 0;
BA_ "GenSigSendType" SG_ 1426 KY_Schluesselposition_6 3;
BA_ "GenSigSwitchedByIgnition" SG_ 1426 KY_Schluesselposition_6 0;
BA_ "GenSigSendType" SG_ 1426 KY_Schluesselposition_7 3;
BA_ "GenSigSwitchedByIgnition" SG_ 1426 KY_Schluesselposition_7 0;
BA_ "GenSigSendType" SG_ 1426 KY_Schluesselposition_8 3;
BA_ "GenSigSwitchedByIgnition" SG_ 1426 KY_Schluesselposition_8 0;
BA_ "GenSigSendType" SG_ 1426 KY_Schluesselposition_9 3;
BA_ "GenSigSwitchedByIgnition" SG_ 1426 KY_Schluesselposition_9 0;
BA_ "GenSigSendType" SG_ 1426 KY_Startknopf_Bel 3;
BA_ "GenSigSwitchedByIgnition" SG_ 1426 KY_Startknopf_Bel 0;
BA_ "GenSigSendType" SG_ 1426 KY_StartStopp_Info 3;
BA_ "GenSigSwitchedByIgnition" SG_ 1426 KY_StartStopp_Info 0;
BA_ "GenSigSendType" SG_ 960 BCM_Ausparken_Betrieb 3;
BA_ "GenSigSwitchedByIgnition" SG_ 960 BCM_Ausparken_Betrieb 0;
BA_ "GenSigSendType" SG_ 960 BCM_Remotestart_Betrieb 3;
BA_ "GenSigSwitchedByIgnition" SG_ 960 BCM_Remotestart_Betrieb 0;
BA_ "GenSigSendType" SG_ 960 BCM_Remotestart_KL15_Anf 3;
BA_ "GenSigSwitchedByIgnition" SG_ 960 BCM_Remotestart_KL15_Anf 0;
BA_ "GenSigSendType" SG_ 960 BCM_Remotestart_MO_Start 3;
BA_ "GenSigSwitchedByIgnition" SG_ 960 BCM_Remotestart_MO_Start 0;
BA_ "GenSigSendType" SG_ 960 Klemmen_Status_01_BZ 0;
BA_ "GenSigFuncType" SG_ 960 Klemmen_Status_01_BZ 1;
BA_ "GenSigSwitchedByIgnition" SG_ 960 Klemmen_Status_01_BZ 0;
BA_ "GenSigSendType" SG_ 960 Klemmen_Status_01_CRC 0;
BA_ "GenSigFuncType" SG_ 960 Klemmen_Status_01_CRC 2;
BA_ "GenSigSwitchedByIgnition" SG_ 960 Klemmen_Status_01_CRC 0;
BA_ "GenSigSendType" SG_ 960 KST_Fahrerhinweis_1 3;
BA_ "GenSigSwitchedByIgnition" SG_ 960 KST_Fahrerhinweis_1 0;
BA_ "GenSigSendType" SG_ 960 KST_Fahrerhinweis_2 3;
BA_ "GenSigSwitchedByIgnition" SG_ 960 KST_Fahrerhinweis_2 0;
BA_ "GenSigSendType" SG_ 960 KST_Fahrerhinweis_4 3;
BA_ "GenSigSwitchedByIgnition" SG_ 960 KST_Fahrerhinweis_4 0;
BA_ "GenSigSendType" SG_ 960 KST_Fahrerhinweis_5 3;
BA_ "GenSigSwitchedByIgnition" SG_ 960 KST_Fahrerhinweis_5 0;
BA_ "GenSigSendType" SG_ 960 KST_Fahrerhinweis_6 3;
BA_ "GenSigSwitchedByIgnition" SG_ 960 KST_Fahrerhinweis_6 0;
BA_ "GenSigSendType" SG_ 960 KST_Warn_P1_ZST_def 3;
BA_ "GenSigSwitchedByIgnition" SG_ 960 KST_Warn_P1_ZST_def 0;
BA_ "GenSigSendType" SG_ 960 KST_Warn_P2_ZST_def 3;
BA_ "GenSigSwitchedByIgnition" SG_ 960 KST_Warn_P2_ZST_def 0;
BA_ "GenSigSendType" SG_ 960 RSt_Fahrerhinweise 3;
BA_ "GenSigSwitchedByIgnition" SG_ 960 RSt_Fahrerhinweise 0;
BA_ "GenSigSendType" SG_ 960 ZAS_Kl_15 3;
BA_ "NWM-WakeupAllowed" SG_ 960 ZAS_Kl_15 1;
BA_ "GenSigFuncType" SG_ 960 ZAS_Kl_15 6;
BA_ "GenSigSwitchedByIgnition" SG_ 960 ZAS_Kl_15 0;
BA_ "GenSigSendType" SG_ 960 ZAS_Kl_50_Startanforderung 3;
BA_ "GenSigSwitchedByIgnition" SG_ 960 ZAS_Kl_50_Startanforderung 0;
BA_ "GenSigSendType" SG_ 960 ZAS_Kl_Infotainment 3;
BA_ "GenSigSwitchedByIgnition" SG_ 960 ZAS_Kl_Infotainment 0;
BA_ "GenSigSendType" SG_ 960 ZAS_Kl_S 3;
BA_ "GenSigSwitchedByIgnition" SG_ 960 ZAS_Kl_S 0;
BA_ "GenSigSendType" SG_ 960 ZAS_Kl_X 3;
BA_ "GenSigSwitchedByIgnition" SG_ 960 ZAS_Kl_X 0;
BA_ "GenSigSendType" SG_ 2463978753 Klemmen_Status_02_BZ 0;
BA_ "GenSigFuncType" SG_ 2463978753 Klemmen_Status_02_BZ 1;
BA_ "GenSigSwitchedByIgnition" SG_ 2463978753 Klemmen_Status_02_BZ 0;
BA_ "GenSigSendType" SG_ 2463978753 Klemmen_Status_02_CRC 0;
BA_ "GenSigFuncType" SG_ 2463978753 Klemmen_Status_02_CRC 2;
BA_ "GenSigSwitchedByIgnition" SG_ 2463978753 Klemmen_Status_02_CRC 0;
BA_ "GenSigSendType" SG_ 2463978753 KST_ComfortReadyStatus 4;
BA_ "GenSigSwitchedByIgnition" SG_ 2463978753 KST_ComfortReadyStatus 0;
BA_ "GenSigSendType" SG_ 2463978753 KST_Freigabe_Zustand 4;
BA_ "GenSigSwitchedByIgnition" SG_ 2463978753 KST_Freigabe_Zustand 0;
BA_ "GenSigSendType" SG_ 2463978753 KST_Sonderzustand_Anforderung 4;
BA_ "GenSigSwitchedByIgnition" SG_ 2463978753 KST_Sonderzustand_Anforderung 0;
BA_ "Fehlerwert" SG_ 2463978753 KST_Sonderzustand_Anforderung 31;
BA_ "GenSigSendType" SG_ 2463978753 KST_Sonderzustand_Status 4;
BA_ "GenSigSwitchedByIgnition" SG_ 2463978753 KST_Sonderzustand_Status 0;
BA_ "Fehlerwert" SG_ 2463978753 KST_Sonderzustand_Status 3;
BA_ "GenSigSendType" SG_ 2463978753 KST_WFS_Fahrfreigabe_Anforderung 4;
BA_ "GenSigSwitchedByIgnition" SG_ 2463978753 KST_WFS_Fahrfreigabe_Anforderung 0;
BA_ "GenSigSendType" SG_ 1646 KL_Anf_AussenspiegelHzg 3;
BA_ "GenSigSwitchedByIgnition" SG_ 1646 KL_Anf_AussenspiegelHzg 0;
BA_ "GenSigSendType" SG_ 1646 KL_BCmE_Livetip_Freigabe 3;
BA_ "GenSigSwitchedByIgnition" SG_ 1646 KL_BCmE_Livetip_Freigabe 0;
BA_ "GenSigSendType" SG_ 1646 KL_ErwVK_Anf 3;
BA_ "GenSigSwitchedByIgnition" SG_ 1646 KL_ErwVK_Anf 0;
BA_ "GenSigSendType" SG_ 1646 KL_FSH_Automatikbetrieb 3;
BA_ "GenSigSwitchedByIgnition" SG_ 1646 KL_FSH_Automatikbetrieb 0;
BA_ "GenSigSendType" SG_ 1646 KL_Geblaese_Fond_Status 0;
BA_ "GenSigStartValue" SG_ 1646 KL_Geblaese_Fond_Status 14;
BA_ "GenSigSwitchedByIgnition" SG_ 1646 KL_Geblaese_Fond_Status 0;
BA_ "Fehlerwert" SG_ 1646 KL_Geblaese_Fond_Status 15;
BA_ "GenSigSendType" SG_ 1646 KL_Geblaese_Status 0;
BA_ "GenSigStartValue" SG_ 1646 KL_Geblaese_Status 14;
BA_ "GenSigSwitchedByIgnition" SG_ 1646 KL_Geblaese_Status 0;
BA_ "Fehlerwert" SG_ 1646 KL_Geblaese_Status 15;
BA_ "GenSigSendType" SG_ 1646 KL_Heizkreisventilstellung 0;
BA_ "GenSigSwitchedByIgnition" SG_ 1646 KL_Heizkreisventilstellung 0;
BA_ "Fehlerwert" SG_ 1646 KL_Heizkreisventilstellung 3;
BA_ "GenSigSendType" SG_ 1646 KL_I_Geblaese_Fond 3;
BA_ "GenSigSwitchedByIgnition" SG_ 1646 KL_I_Geblaese_Fond 0;
BA_ "Fehlerwert" SG_ 1646 KL_I_Geblaese_Fond 255;
BA_ "GenSigSendType" SG_ 1646 KL_Innen_Temp 0;
BA_ "GenSigStartValue" SG_ 1646 KL_Innen_Temp 254;
BA_ "GenSigSwitchedByIgnition" SG_ 1646 KL_Innen_Temp 0;
BA_ "Fehlerwert" SG_ 1646 KL_Innen_Temp 255;
BA_ "GenSigSendType" SG_ 1646 KL_Kompressorkupplung 3;
BA_ "GenSigSwitchedByIgnition" SG_ 1646 KL_Kompressorkupplung 0;
BA_ "GenSigSendType" SG_ 1646 KL_Magnetventil 3;
BA_ "GenSigSwitchedByIgnition" SG_ 1646 KL_Magnetventil 0;
BA_ "GenSigSendType" SG_ 1646 KL_Restwaerme_aktiv 3;
BA_ "GenSigSwitchedByIgnition" SG_ 1646 KL_Restwaerme_aktiv 0;
BA_ "GenSigSendType" SG_ 1646 KL_SH_Soll_hl 3;
BA_ "GenSigSwitchedByIgnition" SG_ 1646 KL_SH_Soll_hl 0;
BA_ "GenSigSendType" SG_ 1646 KL_SH_Soll_hr 3;
BA_ "GenSigSwitchedByIgnition" SG_ 1646 KL_SH_Soll_hr 0;
BA_ "GenSigSendType" SG_ 1646 KL_SIH_LEH_Verteilung_VL 3;
BA_ "GenSigSwitchedByIgnition" SG_ 1646 KL_SIH_LEH_Verteilung_VL 0;
BA_ "GenSigSendType" SG_ 1646 KL_SIH_LEH_Verteilung_VR 3;
BA_ "GenSigSwitchedByIgnition" SG_ 1646 KL_SIH_LEH_Verteilung_VR 0;
BA_ "GenSigSendType" SG_ 1646 KL_SIH_LEL_Verteilung_VL 3;
BA_ "GenSigSwitchedByIgnition" SG_ 1646 KL_SIH_LEL_Verteilung_VL 0;
BA_ "GenSigSendType" SG_ 1646 KL_SIH_LEL_Verteilung_VR 3;
BA_ "GenSigSwitchedByIgnition" SG_ 1646 KL_SIH_LEL_Verteilung_VR 0;
BA_ "GenSigSendType" SG_ 1646 KL_Solarluefter_aktiv 3;
BA_ "GenSigSwitchedByIgnition" SG_ 1646 KL_Solarluefter_aktiv 0;
BA_ "GenSigSendType" SG_ 1646 KL_STH_aktiv 3;
BA_ "GenSigSwitchedByIgnition" SG_ 1646 KL_STH_aktiv 0;
BA_ "GenSigSendType" SG_ 1646 KL_STH_Ansteuerung 3;
BA_ "GenSigSwitchedByIgnition" SG_ 1646 KL_STH_Ansteuerung 0;
BA_ "GenSigSendType" SG_ 1646 KL_STH_Betriebsdauer 3;
BA_ "GenSigSwitchedByIgnition" SG_ 1646 KL_STH_Betriebsdauer 0;
BA_ "GenSigSendType" SG_ 1646 KL_STL_aktiv 3;
BA_ "GenSigSwitchedByIgnition" SG_ 1646 KL_STL_aktiv 0;
BA_ "GenSigSendType" SG_ 1646 KL_Umluft_Taste 3;
BA_ "GenSigSwitchedByIgnition" SG_ 1646 KL_Umluft_Taste 0;
BA_ "GenSigSendType" SG_ 1646 KL_WaPu 3;
BA_ "GenSigSwitchedByIgnition" SG_ 1646 KL_WaPu 0;
BA_ "GenSigSendType" SG_ 1649 KL_Betriebsmodus_FH 3;
BA_ "GenSigSwitchedByIgnition" SG_ 1649 KL_Betriebsmodus_FH 0;
BA_ "GenSigSendType" SG_ 1649 KL_ErwVK_Beifahrerzone 3;
BA_ "GenSigSwitchedByIgnition" SG_ 1649 KL_ErwVK_Beifahrerzone 0;
BA_ "GenSigSendType" SG_ 1649 KL_ErwVK_Fahrerzone 3;
BA_ "GenSigSwitchedByIgnition" SG_ 1649 KL_ErwVK_Fahrerzone 0;
BA_ "GenSigSendType" SG_ 1649 KL_ErwVK_Heckzone2_links 3;
BA_ "GenSigSwitchedByIgnition" SG_ 1649 KL_ErwVK_Heckzone2_links 0;
BA_ "GenSigSendType" SG_ 1649 KL_ErwVK_Heckzone2_rechts 3;
BA_ "GenSigSwitchedByIgnition" SG_ 1649 KL_ErwVK_Heckzone2_rechts 0;
BA_ "GenSigSendType" SG_ 1649 KL_ErwVK_Heckzone_links 3;
BA_ "GenSigSwitchedByIgnition" SG_ 1649 KL_ErwVK_Heckzone_links 0;
BA_ "GenSigSendType" SG_ 1649 Kl_ErwVK_Heckzone_rechts 3;
BA_ "GenSigSwitchedByIgnition" SG_ 1649 Kl_ErwVK_Heckzone_rechts 0;
BA_ "GenSigSendType" SG_ 1649 KL_ErwVK_Scheibenheizung 3;
BA_ "GenSigSwitchedByIgnition" SG_ 1649 KL_ErwVK_Scheibenheizung 0;
BA_ "GenSigSendType" SG_ 1649 KL_ErwVK_Status 3;
BA_ "GenSigSwitchedByIgnition" SG_ 1649 KL_ErwVK_Status 0;
BA_ "GenSigSendType" SG_ 1649 KL_Hinweis_Kuehlmodus 3;
BA_ "GenSigSwitchedByIgnition" SG_ 1649 KL_Hinweis_Kuehlmodus 0;
BA_ "GenSigSendType" SG_ 1649 KL_Meldung_Status 3;
BA_ "GenSigSwitchedByIgnition" SG_ 1649 KL_Meldung_Status 0;
BA_ "GenSigSendType" SG_ 1649 KL_STH_Betriebsdauer_lang 3;
BA_ "GenSigSwitchedByIgnition" SG_ 1649 KL_STH_Betriebsdauer_lang 0;
BA_ "GenSigSendType" SG_ 1649 KL_Stopp_Wiederstart_Anz_01 3;
BA_ "GenSigSwitchedByIgnition" SG_ 1649 KL_Stopp_Wiederstart_Anz_01 0;
BA_ "GenSigSendType" SG_ 1649 KL_Stopp_Wiederstart_Anz_02 3;
BA_ "GenSigSwitchedByIgnition" SG_ 1649 KL_Stopp_Wiederstart_Anz_02 0;
BA_ "GenSigSendType" SG_ 1649 KL_Stopp_Wiederstart_Anz_03 3;
BA_ "GenSigSwitchedByIgnition" SG_ 1649 KL_Stopp_Wiederstart_Anz_03 0;
BA_ "GenSigSendType" SG_ 1649 KL_Stopp_Wiederstart_Anz_04 3;
BA_ "GenSigSwitchedByIgnition" SG_ 1649 KL_Stopp_Wiederstart_Anz_04 0;
BA_ "GenSigSendType" SG_ 1649 KL_Stopp_Wiederstart_Anz_05 3;
BA_ "GenSigSwitchedByIgnition" SG_ 1649 KL_Stopp_Wiederstart_Anz_05 0;
BA_ "GenSigSendType" SG_ 1649 KL_Stopp_Wiederstart_Anz_06 3;
BA_ "GenSigSwitchedByIgnition" SG_ 1649 KL_Stopp_Wiederstart_Anz_06 0;
BA_ "GenSigSendType" SG_ 1649 KL_Stopp_Wiederstart_Anz_07 3;
BA_ "GenSigSwitchedByIgnition" SG_ 1649 KL_Stopp_Wiederstart_Anz_07 0;
BA_ "GenSigSendType" SG_ 1649 KL_Stopp_Wiederstart_Anz_08 3;
BA_ "GenSigSwitchedByIgnition" SG_ 1649 KL_Stopp_Wiederstart_Anz_08 0;
BA_ "GenSigSendType" SG_ 1649 KL_Stopp_Wiederstart_Anz_09 3;
BA_ "GenSigSwitchedByIgnition" SG_ 1649 KL_Stopp_Wiederstart_Anz_09 0;
BA_ "GenSigSendType" SG_ 1649 KL_Stopp_Wiederstart_Anz_Std1 3;
BA_ "GenSigSwitchedByIgnition" SG_ 1649 KL_Stopp_Wiederstart_Anz_Std1 0;
BA_ "GenSigSendType" SG_ 1649 KL_Stopp_Wiederstart_Anz_Std2 3;
BA_ "GenSigSwitchedByIgnition" SG_ 1649 KL_Stopp_Wiederstart_Anz_Std2 0;
BA_ "GenSigSendType" SG_ 1649 KL_ZZ_Betriebsmodus 3;
BA_ "GenSigSwitchedByIgnition" SG_ 1649 KL_ZZ_Betriebsmodus 0;
BA_ "GenSigSendType" SG_ 1649 KL_ZZ_Minute 3;
BA_ "GenSigSwitchedByIgnition" SG_ 1649 KL_ZZ_Minute 0;
BA_ "GenSigSendType" SG_ 1649 KL_ZZ_Monat 3;
BA_ "GenSigSwitchedByIgnition" SG_ 1649 KL_ZZ_Monat 0;
BA_ "GenSigSendType" SG_ 1649 KL_ZZ_Status_Timer 3;
BA_ "GenSigSwitchedByIgnition" SG_ 1649 KL_ZZ_Status_Timer 0;
BA_ "GenSigSendType" SG_ 1649 KL_ZZ_Stunde 3;
BA_ "GenSigSwitchedByIgnition" SG_ 1649 KL_ZZ_Stunde 0;
BA_ "GenSigSendType" SG_ 1649 KL_ZZ_Tag 3;
BA_ "GenSigSwitchedByIgnition" SG_ 1649 KL_ZZ_Tag 0;
BA_ "GenSigSendType" SG_ 949 KL_AC_Schalter 0;
BA_ "GenSigSwitchedByIgnition" SG_ 949 KL_AC_Schalter 0;
BA_ "GenSigSendType" SG_ 949 KL_AirCleaner_aktiv 0;
BA_ "GenSigSwitchedByIgnition" SG_ 949 KL_AirCleaner_aktiv 0;
BA_ "GenSigSendType" SG_ 949 KL_Anf_KL 0;
BA_ "GenSigSwitchedByIgnition" SG_ 949 KL_Anf_KL 0;
BA_ "Fehlerwert" SG_ 949 KL_Anf_KL 255;
BA_ "GenSigSendType" SG_ 949 KL_Anf_KV 0;
BA_ "GenSigStartValue" SG_ 949 KL_Anf_KV 126;
BA_ "GenSigSwitchedByIgnition" SG_ 949 KL_Anf_KV 0;
BA_ "GenSigSendType" SG_ 949 KL_Ausstattung_Klima 0;
BA_ "GenSigSwitchedByIgnition" SG_ 949 KL_Ausstattung_Klima 0;
BA_ "GenSigSendType" SG_ 949 KL_Charisma_FahrPr 0;
BA_ "GenSigSwitchedByIgnition" SG_ 949 KL_Charisma_FahrPr 0;
BA_ "GenSigSendType" SG_ 949 KL_Charisma_Status 0;
BA_ "GenSigSwitchedByIgnition" SG_ 949 KL_Charisma_Status 0;
BA_ "GenSigSendType" SG_ 949 KL_Drehz_Anh 0;
BA_ "GenSigSwitchedByIgnition" SG_ 949 KL_Drehz_Anh 0;
BA_ "GenSigSendType" SG_ 949 KL_el_Zuheizer_Stufe 0;
BA_ "GenSigSwitchedByIgnition" SG_ 949 KL_el_Zuheizer_Stufe 0;
BA_ "GenSigSendType" SG_ 949 KL_Freilauf_Info 0;
BA_ "GenSigSwitchedByIgnition" SG_ 949 KL_Freilauf_Info 0;
BA_ "GenSigSendType" SG_ 949 KL_Komp_Moment_alt 0;
BA_ "GenSigFuncType" SG_ 949 KL_Komp_Moment_alt 5;
BA_ "GenSigSwitchedByIgnition" SG_ 949 KL_Komp_Moment_alt 0;
BA_ "GenSigSendType" SG_ 949 KL_Kompressorkupplung_linear 0;
BA_ "GenSigStartValue" SG_ 949 KL_Kompressorkupplung_linear 254;
BA_ "GenSigSwitchedByIgnition" SG_ 949 KL_Kompressorkupplung_linear 0;
BA_ "GenSigSendType" SG_ 949 KL_Last_Kompr 0;
BA_ "GenSigSwitchedByIgnition" SG_ 949 KL_Last_Kompr 0;
BA_ "Fehlerwert" SG_ 949 KL_Last_Kompr 255;
BA_ "GenSigSendType" SG_ 949 KL_nachtr_Stopp_Anf 0;
BA_ "GenSigSwitchedByIgnition" SG_ 949 KL_nachtr_Stopp_Anf 0;
BA_ "GenSigSendType" SG_ 949 KL_Spannungs_Anf 0;
BA_ "GenSigSwitchedByIgnition" SG_ 949 KL_Spannungs_Anf 0;
BA_ "GenSigSendType" SG_ 949 KL_StartStopp_Info 0;
BA_ "GenSigSwitchedByIgnition" SG_ 949 KL_StartStopp_Info 0;
BA_ "GenSigSendType" SG_ 949 KL_T_Charge 0;
BA_ "GenSigSwitchedByIgnition" SG_ 949 KL_T_Charge 0;
BA_ "GenSigSendType" SG_ 949 KL_Thermomanagement 0;
BA_ "GenSigSwitchedByIgnition" SG_ 949 KL_Thermomanagement 0;
BA_ "GenSigSendType" SG_ 949 KL_Variante_Standheizung 0;
BA_ "GenSigSwitchedByIgnition" SG_ 949 KL_Variante_Standheizung 0;
BA_ "GenSigSendType" SG_ 949 KL_Vorwarn_Komp_ein 0;
BA_ "GenSigSwitchedByIgnition" SG_ 949 KL_Vorwarn_Komp_ein 0;
BA_ "GenSigSendType" SG_ 949 KL_Vorwarn_Zuheizer_ein 0;
BA_ "GenSigSwitchedByIgnition" SG_ 949 KL_Vorwarn_Zuheizer_ein 0;
BA_ "GenSigSendType" SG_ 949 KL_Zustand 0;
BA_ "GenSigSwitchedByIgnition" SG_ 949 KL_Zustand 0;
BA_ "GenSigActiveRepetitions" SG_ 1640 FSH_Taster 5;
BA_ "GenSigSendType" SG_ 1640 FSH_Taster 4;
BA_ "GenSigSwitchedByIgnition" SG_ 1640 FSH_Taster 0;
BA_ "GenSigActiveRepetitions" SG_ 1640 HSH_Taster 5;
BA_ "GenSigSendType" SG_ 1640 HSH_Taster 4;
BA_ "GenSigSwitchedByIgnition" SG_ 1640 HSH_Taster 0;
BA_ "GenSigSendType" SG_ 1640 KL_Beschlagsgefahr 3;
BA_ "GenSigSwitchedByIgnition" SG_ 1640 KL_Beschlagsgefahr 0;
BA_ "GenSigSendType" SG_ 1640 KL_Geblspng_Fond_Soll 0;
BA_ "GenSigSwitchedByIgnition" SG_ 1640 KL_Geblspng_Fond_Soll 0;
BA_ "Fehlerwert" SG_ 1640 KL_Geblspng_Fond_Soll 255;
BA_ "GenSigSendType" SG_ 1640 KL_Geblspng_Soll 0;
BA_ "GenSigSwitchedByIgnition" SG_ 1640 KL_Geblspng_Soll 0;
BA_ "Fehlerwert" SG_ 1640 KL_Geblspng_Soll 255;
BA_ "GenSigSendType" SG_ 1640 KL_I_Geblaese 0;
BA_ "GenSigSwitchedByIgnition" SG_ 1640 KL_I_Geblaese 0;
BA_ "Fehlerwert" SG_ 1640 KL_I_Geblaese 255;
BA_ "GenSigSendType" SG_ 1640 KL_Kompressorstrom_soll 0;
BA_ "GenSigStartValue" SG_ 1640 KL_Kompressorstrom_soll 1022;
BA_ "GenSigSwitchedByIgnition" SG_ 1640 KL_Kompressorstrom_soll 0;
BA_ "Fehlerwert" SG_ 1640 KL_Kompressorstrom_soll 1023;
BA_ "GenSigSendType" SG_ 1640 KL_LRH_Stufe 3;
BA_ "GenSigStartValue" SG_ 1640 KL_LRH_Stufe 1;
BA_ "GenSigSwitchedByIgnition" SG_ 1640 KL_LRH_Stufe 0;
BA_ "GenSigActiveRepetitions" SG_ 1640 KL_LRH_Taster 5;
BA_ "GenSigSendType" SG_ 1640 KL_LRH_Taster 4;
BA_ "GenSigSwitchedByIgnition" SG_ 1640 KL_LRH_Taster 0;
BA_ "GenSigSendType" SG_ 1640 KL_PTC_Verbauinfo 0;
BA_ "GenSigSwitchedByIgnition" SG_ 1640 KL_PTC_Verbauinfo 0;
BA_ "GenSigSendType" SG_ 1640 KL_SIH_Soll_li 3;
BA_ "GenSigSwitchedByIgnition" SG_ 1640 KL_SIH_Soll_li 0;
BA_ "GenSigSendType" SG_ 1640 KL_SIH_Soll_re 3;
BA_ "GenSigSwitchedByIgnition" SG_ 1640 KL_SIH_Soll_re 0;
BA_ "GenSigSendType" SG_ 1640 KL_SIL_Soll_li 3;
BA_ "GenSigSwitchedByIgnition" SG_ 1640 KL_SIL_Soll_li 0;
BA_ "GenSigSendType" SG_ 1640 KL_SIL_Soll_re 3;
BA_ "GenSigSwitchedByIgnition" SG_ 1640 KL_SIL_Soll_re 0;
BA_ "GenSigSendType" SG_ 1640 KL_Umluftklappe_Status 0;
BA_ "GenSigStartValue" SG_ 1640 KL_Umluftklappe_Status 14;
BA_ "GenSigSwitchedByIgnition" SG_ 1640 KL_Umluftklappe_Status 0;
BA_ "Fehlerwert" SG_ 1640 KL_Umluftklappe_Status 15;
BA_ "GenSigSendType" SG_ 1640 KL_Zuheizer_Freigabe 3;
BA_ "GenSigSwitchedByIgnition" SG_ 1640 KL_Zuheizer_Freigabe 0;
BA_ "GenSigSendType" SG_ 1640 KRH_Soll_li 3;
BA_ "GenSigSwitchedByIgnition" SG_ 1640 KRH_Soll_li 0;
BA_ "GenSigSendType" SG_ 1640 KRH_Soll_re 3;
BA_ "GenSigSwitchedByIgnition" SG_ 1640 KRH_Soll_re 0;
BA_ "GenSigSendType" SG_ 2527679635 FSH_Status 0;
BA_ "GenSigSwitchedByIgnition" SG_ 2527679635 FSH_Status 0;
BA_ "Fehlerwert" SG_ 2527679635 FSH_Status 3;
BA_ "GenSigSendType" SG_ 2527679635 HSH_Relais_Anf 3;
BA_ "GenSigSwitchedByIgnition" SG_ 2527679635 HSH_Relais_Anf 0;
BA_ "GenSigSendType" SG_ 2527679635 KL_AL_HL_Anf 3;
BA_ "GenSigSwitchedByIgnition" SG_ 2527679635 KL_AL_HL_Anf 0;
BA_ "GenSigSendType" SG_ 2527679635 KL_AL_HR_Anf 3;
BA_ "GenSigSwitchedByIgnition" SG_ 2527679635 KL_AL_HR_Anf 0;
BA_ "GenSigSendType" SG_ 2527679635 KL_AL_VL_Anf 3;
BA_ "GenSigSwitchedByIgnition" SG_ 2527679635 KL_AL_VL_Anf 0;
BA_ "GenSigSendType" SG_ 2527679635 KL_AL_VR_Anf 3;
BA_ "GenSigSwitchedByIgnition" SG_ 2527679635 KL_AL_VR_Anf 0;
BA_ "GenSigSendType" SG_ 2527679635 KL_Defrost_LED 3;
BA_ "GenSigSwitchedByIgnition" SG_ 2527679635 KL_Defrost_LED 0;
BA_ "GenSigSendType" SG_ 2527679635 KL_FSH_LED 3;
BA_ "GenSigSwitchedByIgnition" SG_ 2527679635 KL_FSH_LED 0;
BA_ "GenSigSendType" SG_ 2527679635 KL_FSH_Soll 3;
BA_ "GenSigSwitchedByIgnition" SG_ 2527679635 KL_FSH_Soll 0;
BA_ "GenSigSendType" SG_ 2527679635 KL_Heizstufe_LSH 3;
BA_ "GenSigSwitchedByIgnition" SG_ 2527679635 KL_Heizstufe_LSH 0;
BA_ "Fehlerwert" SG_ 2527679635 KL_Heizstufe_LSH 15;
BA_ "GenSigSendType" SG_ 2527679635 KL_HSH_LED 3;
BA_ "GenSigSwitchedByIgnition" SG_ 2527679635 KL_HSH_LED 0;
BA_ "GenSigSendType" SG_ 2527679635 KL_HSH_Soll 3;
BA_ "GenSigSwitchedByIgnition" SG_ 2527679635 KL_HSH_Soll 0;
BA_ "GenSigSendType" SG_ 2527679635 KL_HUP_aktiv 3;
BA_ "GenSigSwitchedByIgnition" SG_ 2527679635 KL_HUP_aktiv 0;
BA_ "GenSigSendType" SG_ 2527679635 KL_Klappe_Status 3;
BA_ "GenSigSwitchedByIgnition" SG_ 2527679635 KL_Klappe_Status 0;
BA_ "GenSigSendType" SG_ 2527679635 KL_LRH_PWM 3;
BA_ "GenSigSwitchedByIgnition" SG_ 2527679635 KL_LRH_PWM 0;
BA_ "GenSigSendType" SG_ 2527679635 KL_LRH_Soll 3;
BA_ "GenSigSwitchedByIgnition" SG_ 2527679635 KL_LRH_Soll 0;
BA_ "GenSigSendType" SG_ 2527679635 KL_LSH_Ansteuerung 3;
BA_ "GenSigSwitchedByIgnition" SG_ 2527679635 KL_LSH_Ansteuerung 0;
BA_ "GenSigSendType" SG_ 2527679635 KL_LSH_Betriebsdauer 3;
BA_ "GenSigSwitchedByIgnition" SG_ 2527679635 KL_LSH_Betriebsdauer 0;
BA_ "GenSigSendType" SG_ 2527679635 KL_LSH_DBetr_Bestaet 3;
BA_ "GenSigSwitchedByIgnition" SG_ 2527679635 KL_LSH_DBetr_Bestaet 0;
BA_ "GenSigSendType" SG_ 2527679635 KL_LSH_DBetr_Ein 3;
BA_ "GenSigSwitchedByIgnition" SG_ 2527679635 KL_LSH_DBetr_Ein 0;
BA_ "GenSigSendType" SG_ 2527679635 KL_Temp_ZH_Soll 3;
BA_ "GenSigSwitchedByIgnition" SG_ 2527679635 KL_Temp_ZH_Soll 0;
BA_ "Fehlerwert" SG_ 2527679635 KL_Temp_ZH_Soll 255;
BA_ "GenSigSendType" SG_ 2527679635 KL_VoKo_LED 3;
BA_ "GenSigSwitchedByIgnition" SG_ 2527679635 KL_VoKo_LED 0;
BA_ "GenSigSendType" SG_ 2527679635 KL_Voko_Status 3;
BA_ "GenSigStartValue" SG_ 2527679635 KL_Voko_Status 14;
BA_ "GenSigSwitchedByIgnition" SG_ 2527679635 KL_Voko_Status 0;
BA_ "Fehlerwert" SG_ 2527679635 KL_Voko_Status 15;
BA_ "GenSigSendType" SG_ 2527679635 KL_ZR_Anforderung 3;
BA_ "GenSigSwitchedByIgnition" SG_ 2527679635 KL_ZR_Anforderung 0;
BA_ "GenSigSendType" SG_ 2527679635 SIH_Stufe_LED_li 3;
BA_ "GenSigSwitchedByIgnition" SG_ 2527679635 SIH_Stufe_LED_li 0;
BA_ "GenSigSendType" SG_ 2527679635 SIH_Stufe_LED_re 3;
BA_ "GenSigSwitchedByIgnition" SG_ 2527679635 SIH_Stufe_LED_re 0;
BA_ "GenSigSendType" SG_ 2589283627 KL_EKK_1_VerbautStatus 0;
BA_ "GenSigSwitchedByIgnition" SG_ 2589283627 KL_EKK_1_VerbautStatus 0;
BA_ "GenSigSendType" SG_ 2589283627 KL_EKK_2_VerbautStatus 0;
BA_ "GenSigSwitchedByIgnition" SG_ 2589283627 KL_EKK_2_VerbautStatus 0;
BA_ "GenSigSendType" SG_ 2589283627 KL_Heizen_Status 0;
BA_ "GenSigStartValue" SG_ 2589283627 KL_Heizen_Status 14;
BA_ "GenSigSwitchedByIgnition" SG_ 2589283627 KL_Heizen_Status 0;
BA_ "Fehlerwert" SG_ 2589283627 KL_Heizen_Status 15;
BA_ "GenSigSendType" SG_ 2589283627 KL_HV_Energie_Anf 0;
BA_ "GenSigStartValue" SG_ 2589283627 KL_HV_Energie_Anf 254;
BA_ "GenSigSwitchedByIgnition" SG_ 2589283627 KL_HV_Energie_Anf 0;
BA_ "Fehlerwert" SG_ 2589283627 KL_HV_Energie_Anf 255;
BA_ "GenSigSendType" SG_ 2589283627 KL_HVH_1_VerbautStatus 0;
BA_ "GenSigSwitchedByIgnition" SG_ 2589283627 KL_HVH_1_VerbautStatus 0;
BA_ "GenSigSendType" SG_ 2589283627 KL_HVH_2_VerbautStatus 0;
BA_ "GenSigSwitchedByIgnition" SG_ 2589283627 KL_HVH_2_VerbautStatus 0;
BA_ "GenSigSendType" SG_ 2589283627 KL_IstLeistung 0;
BA_ "GenSigStartValue" SG_ 2589283627 KL_IstLeistung 254;
BA_ "GenSigSwitchedByIgnition" SG_ 2589283627 KL_IstLeistung 0;
BA_ "Fehlerwert" SG_ 2589283627 KL_IstLeistung 255;
BA_ "GenSigSendType" SG_ 2589283627 KL_K_Status 0;
BA_ "GenSigSwitchedByIgnition" SG_ 2589283627 KL_K_Status 0;
BA_ "Fehlerwert" SG_ 2589283627 KL_K_Status 14;
BA_ "GenSigSendType" SG_ 2589283627 Kl_Klima_Aktiv 0;
BA_ "GenSigSwitchedByIgnition" SG_ 2589283627 Kl_Klima_Aktiv 0;
BA_ "GenSigSendType" SG_ 2589283627 KL_Kuehlungs_Status 0;
BA_ "GenSigStartValue" SG_ 2589283627 KL_Kuehlungs_Status 14;
BA_ "GenSigSwitchedByIgnition" SG_ 2589283627 KL_Kuehlungs_Status 0;
BA_ "Fehlerwert" SG_ 2589283627 KL_Kuehlungs_Status 15;
BA_ "GenSigSendType" SG_ 2589283627 KL_Leistung_Klima_Anf 0;
BA_ "GenSigStartValue" SG_ 2589283627 KL_Leistung_Klima_Anf 254;
BA_ "GenSigSwitchedByIgnition" SG_ 2589283627 KL_Leistung_Klima_Anf 0;
BA_ "GenSigSendType" SG_ 2589283627 KL_Status_Battkuehlung 0;
BA_ "GenSigSwitchedByIgnition" SG_ 2589283627 KL_Status_Battkuehlung 0;
BA_ "GenSigSendType" SG_ 2589283627 KL_Temp_Kundenwunsch 0;
BA_ "GenSigSwitchedByIgnition" SG_ 2589283627 KL_Temp_Kundenwunsch 0;
BA_ "Fehlerwert" SG_ 2589283627 KL_Temp_Kundenwunsch 63;
BA_ "GenSigSendType" SG_ 2589283627 KL_Texte 0;
BA_ "GenSigSwitchedByIgnition" SG_ 2589283627 KL_Texte 0;
BA_ "GenSigSendType" SG_ 2589283627 TME_HVEM_HV_Anf 0;
BA_ "GenSigSwitchedByIgnition" SG_ 2589283627 TME_HVEM_HV_Anf 0;
BA_ "Fehlerwert" SG_ 2589283627 TME_HVEM_HV_Anf 3;
BA_ "GenSigSendType" SG_ 1712 FS_Luftfeuchte_rel 0;
BA_ "Fehlerwert" SG_ 1712 FS_Luftfeuchte_rel 255;
BA_ "GenSigMissingSourceValue" SG_ 1712 FS_Luftfeuchte_rel 255;
BA_ "GenSigSendType" SG_ 1712 FS_ResponseError 0;
BA_ "Fehlerwert" SG_ 1712 FS_ResponseError 1;
BA_ "GenSigSendType" SG_ 1712 FS_Taupunkt 0;
BA_ "Fehlerwert" SG_ 1712 FS_Taupunkt 1023;
BA_ "GenSigMissingSourceValue" SG_ 1712 FS_Taupunkt 1023;
BA_ "GenSigSendType" SG_ 1712 FS_Temp_Scheibe 0;
BA_ "Fehlerwert" SG_ 1712 FS_Temp_Scheibe 1023;
BA_ "GenSigMissingSourceValue" SG_ 1712 FS_Temp_Scheibe 1023;
BA_ "GenSigSendType" SG_ 1712 FS_Temp_Sensor 0;
BA_ "Fehlerwert" SG_ 1712 FS_Temp_Sensor 255;
BA_ "GenSigMissingSourceValue" SG_ 1712 FS_Temp_Sensor 255;
BA_ "GenSigSendType" SG_ 1505 BCM1_Aussen_Temp_ungef 0;
BA_ "GenSigStartValue" SG_ 1505 BCM1_Aussen_Temp_ungef 254;
BA_ "GenSigSwitchedByIgnition" SG_ 1505 BCM1_Aussen_Temp_ungef 0;
BA_ "Fehlerwert" SG_ 1505 BCM1_Aussen_Temp_ungef 255;
BA_ "GenSigSendType" SG_ 1505 BCM1_FStatus_Aussentemp_ungef 0;
BA_ "GenSigStartValue" SG_ 1505 BCM1_FStatus_Aussentemp_ungef 1;
BA_ "GenSigSwitchedByIgnition" SG_ 1505 BCM1_FStatus_Aussentemp_ungef 0;
BA_ "GenSigSendType" SG_ 1505 BCM1_Kompressorstrom_ist 0;
BA_ "GenSigStartValue" SG_ 1505 BCM1_Kompressorstrom_ist 254;
BA_ "GenSigSwitchedByIgnition" SG_ 1505 BCM1_Kompressorstrom_ist 0;
BA_ "Fehlerwert" SG_ 1505 BCM1_Kompressorstrom_ist 255;
BA_ "GenSigSendType" SG_ 1505 BCM1_OBD_FStatus_ATemp 0;
BA_ "GenSigSwitchedByIgnition" SG_ 1505 BCM1_OBD_FStatus_ATemp 0;
BA_ "GenSigSendType" SG_ 1505 BCM1_PTC_stufig_Status 0;
BA_ "GenSigStartValue" SG_ 1505 BCM1_PTC_stufig_Status 6;
BA_ "GenSigSwitchedByIgnition" SG_ 1505 BCM1_PTC_stufig_Status 0;
BA_ "Fehlerwert" SG_ 1505 BCM1_PTC_stufig_Status 7;
BA_ "GenSigSendType" SG_ 1505 BCM_Heizungsabsperrventil_Status 0;
BA_ "GenSigStartValue" SG_ 1505 BCM_Heizungsabsperrventil_Status 2;
BA_ "GenSigSwitchedByIgnition" SG_ 1505 BCM_Heizungsabsperrventil_Status 0;
BA_ "Fehlerwert" SG_ 1505 BCM_Heizungsabsperrventil_Status 3;
BA_ "GenSigSendType" SG_ 1505 BCM_Heizungspumpe_Status 0;
BA_ "GenSigStartValue" SG_ 1505 BCM_Heizungspumpe_Status 2;
BA_ "GenSigSwitchedByIgnition" SG_ 1505 BCM_Heizungspumpe_Status 0;
BA_ "Fehlerwert" SG_ 1505 BCM_Heizungspumpe_Status 3;
BA_ "GenSigSendType" SG_ 1505 BCM_Kompressorkupplung_Status 0;
BA_ "GenSigStartValue" SG_ 1505 BCM_Kompressorkupplung_Status 2;
BA_ "GenSigSwitchedByIgnition" SG_ 1505 BCM_Kompressorkupplung_Status 0;
BA_ "Fehlerwert" SG_ 1505 BCM_Kompressorkupplung_Status 3;
BA_ "GenSigSendType" SG_ 1717 FSA_Err_Defekt_HumSens_TNCTOC 0;
BA_ "GenSigStartValue" SG_ 1717 FSA_Err_Defekt_HumSens_TNCTOC 1;
BA_ "GenSigSwitchedByIgnition" SG_ 1717 FSA_Err_Defekt_HumSens_TNCTOC 0;
BA_ "GenSigSendType" SG_ 1717 FSA_Err_Defekt_HumSense_TF 0;
BA_ "GenSigSwitchedByIgnition" SG_ 1717 FSA_Err_Defekt_HumSense_TF 0;
BA_ "GenSigSendType" SG_ 1717 FSA_Err_Defekt_Tsens_TF 0;
BA_ "GenSigSwitchedByIgnition" SG_ 1717 FSA_Err_Defekt_Tsens_TF 0;
BA_ "GenSigSendType" SG_ 1717 FSA_Err_RAMROM_Check_TF 0;
BA_ "GenSigSwitchedByIgnition" SG_ 1717 FSA_Err_RAMROM_Check_TF 0;
BA_ "GenSigSendType" SG_ 1717 FSA_Err_RAMROM_Check_TNCTOC 0;
BA_ "GenSigStartValue" SG_ 1717 FSA_Err_RAMROM_Check_TNCTOC 1;
BA_ "GenSigSwitchedByIgnition" SG_ 1717 FSA_Err_RAMROM_Check_TNCTOC 0;
BA_ "GenSigSendType" SG_ 1717 FSA_Err_Ueberspannung_TF 0;
BA_ "GenSigSwitchedByIgnition" SG_ 1717 FSA_Err_Ueberspannung_TF 0;
BA_ "GenSigSendType" SG_ 1717 FSA_Err_Unterspannung_TF 0;
BA_ "GenSigSwitchedByIgnition" SG_ 1717 FSA_Err_Unterspannung_TF 0;
BA_ "GenSigSendType" SG_ 1717 FSA_ErrMemState 0;
BA_ "GenSigSwitchedByIgnition" SG_ 1717 FSA_ErrMemState 0;
BA_ "GenSigSendType" SG_ 1717 FSA_HW 0;
BA_ "GenSigSendType" SG_ 1717 FSA_Luftfeuchte_rel 0;
BA_ "GenSigStartValue" SG_ 1717 FSA_Luftfeuchte_rel 254;
BA_ "Fehlerwert" SG_ 1717 FSA_Luftfeuchte_rel 255;
BA_ "GenSigSendType" SG_ 1717 FSA_Luftfeuchte_TF 0;
BA_ "GenSigSwitchedByIgnition" SG_ 1717 FSA_Luftfeuchte_TF 0;
BA_ "GenSigSendType" SG_ 1717 FSA_Luftfeuchte_TNCTOC 0;
BA_ "GenSigStartValue" SG_ 1717 FSA_Luftfeuchte_TNCTOC 1;
BA_ "GenSigSwitchedByIgnition" SG_ 1717 FSA_Luftfeuchte_TNCTOC 0;
BA_ "GenSigSendType" SG_ 1717 FSA_ResponseError 0;
BA_ "Fehlerwert" SG_ 1717 FSA_ResponseError 1;
BA_ "GenSigSendType" SG_ 1717 FSA_Sensorheizung_Status 0;
BA_ "GenSigSendType" SG_ 1717 FSA_SW 0;
BA_ "GenSigSendType" SG_ 1717 FSA_Taupunkt 0;
BA_ "GenSigStartValue" SG_ 1717 FSA_Taupunkt 1022;
BA_ "Fehlerwert" SG_ 1717 FSA_Taupunkt 1023;
BA_ "GenSigSendType" SG_ 1717 FSA_Temp_Luft 0;
BA_ "GenSigStartValue" SG_ 1717 FSA_Temp_Luft 1022;
BA_ "Fehlerwert" SG_ 1717 FSA_Temp_Luft 1023;
BA_ "GenSigSendType" SG_ 1717 FSA_Temp_Sensor 0;
BA_ "GenSigStartValue" SG_ 1717 FSA_Temp_Sensor 2046;
BA_ "Fehlerwert" SG_ 1717 FSA_Temp_Sensor 2047;
BA_ "GenSigSendType" SG_ 2549088367 AMP_Abschaltstufe 0;
BA_ "GenSigSwitchedByIgnition" SG_ 2549088367 AMP_Abschaltstufe 0;
BA_ "GenSigSendType" SG_ 2549088367 AMP_KD_Fehler 0;
BA_ "GenSigSwitchedByIgnition" SG_ 2549088367 AMP_KD_Fehler 0;
BA_ "GenSigSendType" SG_ 2549088367 AMP_KompSchutz 0;
BA_ "GenSigSwitchedByIgnition" SG_ 2549088367 AMP_KompSchutz 0;
BA_ "GenSigSendType" SG_ 2549088367 AMP_Nachlauftyp 0;
BA_ "GenSigStartValue" SG_ 2549088367 AMP_Nachlauftyp 2;
BA_ "GenSigSwitchedByIgnition" SG_ 2549088367 AMP_Nachlauftyp 0;
BA_ "GenSigSendType" SG_ 2549088367 AMP_Transport_Mode 0;
BA_ "GenSigSwitchedByIgnition" SG_ 2549088367 AMP_Transport_Mode 0;
BA_ "GenSigSendType" SG_ 2549088367 KN_AMP_DiagPfad 0;
BA_ "GenSigSwitchedByIgnition" SG_ 2549088367 KN_AMP_DiagPfad 0;
BA_ "GenSigSendType" SG_ 2549088367 NM_AMP_Wakeup 0;
BA_ "GenSigSwitchedByIgnition" SG_ 2549088367 NM_AMP_Wakeup 0;
BA_ "GenSigSendType" SG_ 2549088564 BedienDisp_m_Abschaltstufe 0;
BA_ "GenSigSendType" SG_ 2549088564 BedienDisp_m_KD_Fehler 0;
BA_ "GenSigSwitchedByIgnition" SG_ 2549088564 BedienDisp_m_KD_Fehler 0;
BA_ "GenSigSendType" SG_ 2549088564 BedienDisp_m_KompSchutz 0;
BA_ "GenSigSwitchedByIgnition" SG_ 2549088564 BedienDisp_m_KompSchutz 0;
BA_ "GenSigSendType" SG_ 2549088564 BedienDisp_m_Nachlauftyp 0;
BA_ "GenSigStartValue" SG_ 2549088564 BedienDisp_m_Nachlauftyp 2;
BA_ "GenSigSwitchedByIgnition" SG_ 2549088564 BedienDisp_m_Nachlauftyp 0;
BA_ "GenSigSendType" SG_ 2549088564 BedienDisp_m_Transport_Mode 0;
BA_ "GenSigSwitchedByIgnition" SG_ 2549088564 BedienDisp_m_Transport_Mode 0;
BA_ "GenSigSendType" SG_ 2549088564 KN_BedienDisp_m_BusKnockOut 0;
BA_ "GenSigSwitchedByIgnition" SG_ 2549088564 KN_BedienDisp_m_BusKnockOut 0;
BA_ "GenSigSendType" SG_ 2549088564 KN_BedienDisp_m_BusKnockoutTimer 0;
BA_ "GenSigSwitchedByIgnition" SG_ 2549088564 KN_BedienDisp_m_BusKnockoutTimer 0;
BA_ "GenSigSendType" SG_ 2549088564 KN_BedienDisp_m_DiagPfad 0;
BA_ "GenSigSwitchedByIgnition" SG_ 2549088564 KN_BedienDisp_m_DiagPfad 0;
BA_ "GenSigSendType" SG_ 2549088564 KN_BedienDisp_m_ECUKnockOut 0;
BA_ "GenSigSwitchedByIgnition" SG_ 2549088564 KN_BedienDisp_m_ECUKnockOut 0;
BA_ "GenSigSendType" SG_ 2549088564 KN_BedienDisp_m_ECUKnockOutTimer 0;
BA_ "GenSigSwitchedByIgnition" SG_ 2549088564 KN_BedienDisp_m_ECUKnockOutTimer 0;
BA_ "GenSigSendType" SG_ 2549088564 NM_BedienDisp_m_Wakeup 0;
BA_ "GenSigSwitchedByIgnition" SG_ 2549088564 NM_BedienDisp_m_Wakeup 0;
BA_ "GenSigSendType" SG_ 2549088418 BedienDisp_vm_Abschaltstufe 0;
BA_ "GenSigSwitchedByIgnition" SG_ 2549088418 BedienDisp_vm_Abschaltstufe 0;
BA_ "GenSigSendType" SG_ 2549088418 BedienDisp_vm_KD_Fehler 0;
BA_ "GenSigSwitchedByIgnition" SG_ 2549088418 BedienDisp_vm_KD_Fehler 0;
BA_ "GenSigSendType" SG_ 2549088418 BedienDisp_vm_KompSchutz 0;
BA_ "GenSigSendType" SG_ 2549088418 BedienDisp_vm_Nachlauftyp 0;
BA_ "GenSigStartValue" SG_ 2549088418 BedienDisp_vm_Nachlauftyp 2;
BA_ "GenSigSwitchedByIgnition" SG_ 2549088418 BedienDisp_vm_Nachlauftyp 0;
BA_ "GenSigSendType" SG_ 2549088418 BedienDisp_vm_Transport_Mode 0;
BA_ "GenSigSwitchedByIgnition" SG_ 2549088418 BedienDisp_vm_Transport_Mode 0;
BA_ "GenSigSendType" SG_ 2549088418 KN_BedienDisp_vm_BusKnockOut 0;
BA_ "GenSigSwitchedByIgnition" SG_ 2549088418 KN_BedienDisp_vm_BusKnockOut 0;
BA_ "GenSigSendType" SG_ 2549088418 KN_BedienDisp_vm_BusKnockOutTime 0;
BA_ "GenSigSwitchedByIgnition" SG_ 2549088418 KN_BedienDisp_vm_BusKnockOutTime 0;
BA_ "GenSigSendType" SG_ 2549088418 KN_BedienDisp_vm_DiagPfad 0;
BA_ "GenSigSwitchedByIgnition" SG_ 2549088418 KN_BedienDisp_vm_DiagPfad 0;
BA_ "GenSigSendType" SG_ 2549088418 KN_BedienDisp_vm_ECUKnockOut 0;
BA_ "GenSigSwitchedByIgnition" SG_ 2549088418 KN_BedienDisp_vm_ECUKnockOut 0;
BA_ "GenSigSendType" SG_ 2549088418 KN_BedienDisp_vm_ECUKnockOutTime 0;
BA_ "GenSigSwitchedByIgnition" SG_ 2549088418 KN_BedienDisp_vm_ECUKnockOutTime 0;
BA_ "GenSigSendType" SG_ 2549088418 NM_BedienDisp_vm_Wakeup 0;
BA_ "GenSigSwitchedByIgnition" SG_ 2549088418 NM_BedienDisp_vm_Wakeup 0;
BA_ "GenSigSendType" SG_ 2549088570 DCAM_Abschaltstufe 0;
BA_ "GenSigSendType" SG_ 2549088570 DCAM_KD_Fehler 0;
BA_ "GenSigSwitchedByIgnition" SG_ 2549088570 DCAM_KD_Fehler 0;
BA_ "GenSigSendType" SG_ 2549088570 DCAM_KompSchutz 0;
BA_ "GenSigSwitchedByIgnition" SG_ 2549088570 DCAM_KompSchutz 0;
BA_ "GenSigSendType" SG_ 2549088570 DCAM_Nachlauftyp 0;
BA_ "GenSigStartValue" SG_ 2549088570 DCAM_Nachlauftyp 2;
BA_ "GenSigSwitchedByIgnition" SG_ 2549088570 DCAM_Nachlauftyp 0;
BA_ "GenSigSendType" SG_ 2549088570 DCAM_Transport_Mode 0;
BA_ "GenSigSwitchedByIgnition" SG_ 2549088570 DCAM_Transport_Mode 0;
BA_ "GenSigSendType" SG_ 2549088570 KN_DCAM_BusKnockOut 0;
BA_ "GenSigSwitchedByIgnition" SG_ 2549088570 KN_DCAM_BusKnockOut 0;
BA_ "GenSigSendType" SG_ 2549088570 KN_DCAM_BusKnockOutTimer 0;
BA_ "GenSigSwitchedByIgnition" SG_ 2549088570 KN_DCAM_BusKnockOutTimer 0;
BA_ "GenSigSendType" SG_ 2549088570 KN_DCAM_DiagPfad 0;
BA_ "GenSigSwitchedByIgnition" SG_ 2549088570 KN_DCAM_DiagPfad 0;
BA_ "GenSigSendType" SG_ 2549088570 KN_DCAM_ECUKnockOut 0;
BA_ "GenSigSwitchedByIgnition" SG_ 2549088570 KN_DCAM_ECUKnockOut 0;
BA_ "GenSigSendType" SG_ 2549088570 KN_DCAM_ECUKnockOutTimer 0;
BA_ "GenSigSwitchedByIgnition" SG_ 2549088570 KN_DCAM_ECUKnockOutTimer 0;
BA_ "GenSigSendType" SG_ 2549088570 NM_DCAM_Wakeup 0;
BA_ "GenSigSwitchedByIgnition" SG_ 2549088570 NM_DCAM_Wakeup 0;
BA_ "GenSigSendType" SG_ 2549088359 eCall_Abschaltstufe 0;
BA_ "GenSigSwitchedByIgnition" SG_ 2549088359 eCall_Abschaltstufe 0;
BA_ "GenSigSendType" SG_ 2549088359 eCall_KD_Fehler 0;
BA_ "GenSigSwitchedByIgnition" SG_ 2549088359 eCall_KD_Fehler 0;
BA_ "GenSigSendType" SG_ 2549088359 eCall_KompSchutz 0;
BA_ "GenSigSwitchedByIgnition" SG_ 2549088359 eCall_KompSchutz 0;
BA_ "GenSigSendType" SG_ 2549088359 eCall_Nachlauftyp 0;
BA_ "GenSigStartValue" SG_ 2549088359 eCall_Nachlauftyp 2;
BA_ "GenSigSwitchedByIgnition" SG_ 2549088359 eCall_Nachlauftyp 0;
BA_ "GenSigSendType" SG_ 2549088359 eCall_Transport_Mode 0;
BA_ "GenSigSwitchedByIgnition" SG_ 2549088359 eCall_Transport_Mode 0;
BA_ "GenSigSendType" SG_ 2549088359 KN_eCall_BusKnockOut 0;
BA_ "GenSigSwitchedByIgnition" SG_ 2549088359 KN_eCall_BusKnockOut 0;
BA_ "GenSigSendType" SG_ 2549088359 KN_eCall_BusKnockOutTimer 0;
BA_ "GenSigSwitchedByIgnition" SG_ 2549088359 KN_eCall_BusKnockOutTimer 0;
BA_ "GenSigSendType" SG_ 2549088359 KN_eCall_DiagPfad 0;
BA_ "GenSigSwitchedByIgnition" SG_ 2549088359 KN_eCall_DiagPfad 0;
BA_ "GenSigSendType" SG_ 2549088359 KN_eCall_ECUKnockOut 0;
BA_ "GenSigSwitchedByIgnition" SG_ 2549088359 KN_eCall_ECUKnockOut 0;
BA_ "GenSigSendType" SG_ 2549088359 KN_eCall_ECUKnockOutTimer 0;
BA_ "GenSigSwitchedByIgnition" SG_ 2549088359 KN_eCall_ECUKnockOutTimer 0;
BA_ "GenSigSendType" SG_ 2549088359 NM_eCall_Wakeup 0;
BA_ "NWM-WakeupAllowed" SG_ 2549088359 NM_eCall_Wakeup 1;
BA_ "GenSigSwitchedByIgnition" SG_ 2549088359 NM_eCall_Wakeup 0;
BA_ "GenSigSendType" SG_ 2549088272 Gateway_Abschaltstufe 0;
BA_ "GenSigSwitchedByIgnition" SG_ 2549088272 Gateway_Abschaltstufe 0;
BA_ "GenSigSendType" SG_ 2549088272 Gateway_KompSchutz 0;
BA_ "GenSigSwitchedByIgnition" SG_ 2549088272 Gateway_KompSchutz 0;
BA_ "GenSigSendType" SG_ 2549088272 Gateway_Nachlauftyp 0;
BA_ "GenSigStartValue" SG_ 2549088272 Gateway_Nachlauftyp 2;
BA_ "GenSigSwitchedByIgnition" SG_ 2549088272 Gateway_Nachlauftyp 0;
BA_ "GenSigSendType" SG_ 2549088272 Gateway_Transport_Mode 0;
BA_ "GenSigSwitchedByIgnition" SG_ 2549088272 Gateway_Transport_Mode 0;
BA_ "GenSigSendType" SG_ 2549088272 GW_KD_Fehler 0;
BA_ "GenSigSendType" SG_ 2549088272 KN_GW_DiagPfad 0;
BA_ "GenSigSwitchedByIgnition" SG_ 2549088272 KN_GW_DiagPfad 0;
BA_ "GenSigSendType" SG_ 2549088272 NM_Gateway_Wakeup 0;
BA_ "NWM-WakeupAllowed" SG_ 2549088272 NM_Gateway_Wakeup 1;
BA_ "GenSigSwitchedByIgnition" SG_ 2549088272 NM_Gateway_Wakeup 0;
BA_REL_ "GenSigTimeoutTime" BU_SG_REL_ BedienDisp_mi SG_ 960 ZAS_Kl_S 1000;
BA_REL_ "GenSigTimeoutTime" BU_SG_REL_ BedienDisp_mi SG_ 960 ZAS_Kl_15 1000;
BA_REL_ "GenSigTimeoutTime" BU_SG_REL_ BedienDisp_vo_mi SG_ 960 ZAS_Kl_S 1000;
BA_REL_ "GenSigTimeoutTime" BU_SG_REL_ BedienDisp_vo_mi SG_ 960 ZAS_Kl_15 1000;
BA_REL_ "GenSigTimeoutTime" BU_SG_REL_ BedienDisp_vo_mi SG_ 1646 KL_Geblaese_Status 5000;
BA_REL_ "GenSigTimeoutTime" BU_SG_REL_ CDI SG_ 960 ZAS_Kl_S 1000;
BA_REL_ "GenSigTimeoutTime" BU_SG_REL_ CDI SG_ 960 ZAS_Kl_15 1000;
BA_REL_ "GenSigTimeoutTime" BU_SG_REL_ ConMod_CD SG_ 960 ZAS_Kl_S 1000;
BA_REL_ "GenSigTimeoutTime" BU_SG_REL_ ConMod_CD SG_ 960 ZAS_Kl_15 1000;
BA_REL_ "GenSigTimeoutTime" BU_SG_REL_ ConMod_CD SG_ 1646 KL_Innen_Temp 5000;
BA_REL_ "GenSigTimeoutTime" BU_SG_REL_ DashCAM SG_ 960 ZAS_Kl_15 1000;
BA_REL_ "GenSigTimeoutTime" BU_SG_REL_ Gateway_Max SG_ 2463978722 GNSS_DR_Nachrichtenpaket_ID1 1000;
BA_REL_ "GenSigTimeoutTime" BU_SG_REL_ Gateway_Max SG_ 2463978722 GNSS_DR_Breite_Ortung 1000;
BA_REL_ "GenSigTimeoutTime" BU_SG_REL_ Gateway_Max SG_ 2463978722 GNSS_DR_Richtung_Breite_Ortung 1000;
BA_REL_ "GenSigTimeoutTime" BU_SG_REL_ Gateway_Max SG_ 2463978722 GNSS_DR_Laenge_Ortung 1000;
BA_REL_ "GenSigTimeoutTime" BU_SG_REL_ Gateway_Max SG_ 2463978722 GNSS_DR_Richtung_Laenge_Ortung 1000;
BA_REL_ "GenSigTimeoutTime" BU_SG_REL_ Gateway_Max SG_ 2463978723 GNSS_DR_Nachrichtenpaket_ID2 1000;
BA_REL_ "GenSigTimeoutTime" BU_SG_REL_ Gateway_Max SG_ 2463978723 GNSS_DR_Ortung_Ausrichtung 1000;
BA_REL_ "GenSigTimeoutTime" BU_SG_REL_ Gateway_Max SG_ 2463978724 GNSS_DR_Nachrichtenpaket_ID3 1000;
BA_REL_ "GenSigTimeoutTime" BU_SG_REL_ Gateway_Max SG_ 2463978724 GNSS_DR_Ortung_Guete_horizontal 1000;
BA_REL_ "GenSigTimeoutTime" BU_SG_REL_ Gateway_Max SG_ 2549088367 AMP_Nachlauftyp 5000;
BA_REL_ "GenSigTimeoutTime" BU_SG_REL_ Gateway_Max SG_ 2549088367 KN_AMP_DiagPfad 5000;
BA_REL_ "GenSigTimeoutTime" BU_SG_REL_ Gateway_Max SG_ 2549088367 AMP_KD_Fehler 2500;
BA_REL_ "GenSigTimeoutTime" BU_SG_REL_ Gateway_Max SG_ 2549088564 BedienDisp_m_Nachlauftyp 5000;
BA_REL_ "GenSigTimeoutTime" BU_SG_REL_ Gateway_Max SG_ 2549088564 KN_BedienDisp_m_DiagPfad 5000;
BA_REL_ "GenSigTimeoutTime" BU_SG_REL_ Gateway_Max SG_ 2549088564 BedienDisp_m_KD_Fehler 2500;
BA_REL_ "GenSigTimeoutTime" BU_SG_REL_ Gateway_Max SG_ 2549088418 BedienDisp_vm_Nachlauftyp 5000;
BA_REL_ "GenSigTimeoutTime" BU_SG_REL_ Gateway_Max SG_ 2549088418 KN_BedienDisp_vm_DiagPfad 5000;
BA_REL_ "GenSigTimeoutTime" BU_SG_REL_ Gateway_Max SG_ 2549088418 BedienDisp_vm_KD_Fehler 2500;
BA_REL_ "GenSigTimeoutTime" BU_SG_REL_ Gateway_Max SG_ 2549088570 DCAM_Nachlauftyp 5000;
BA_REL_ "GenSigTimeoutTime" BU_SG_REL_ Gateway_Max SG_ 2549088570 KN_DCAM_DiagPfad 5000;
BA_REL_ "GenSigTimeoutTime" BU_SG_REL_ Gateway_Max SG_ 2549088570 DCAM_KD_Fehler 2500;
BA_REL_ "GenSigTimeoutTime" BU_SG_REL_ Gateway_Max SG_ 2549088359 eCall_Nachlauftyp 5000;
BA_REL_ "GenSigTimeoutTime" BU_SG_REL_ Gateway_Max SG_ 2549088359 KN_eCall_DiagPfad 5000;
BA_REL_ "GenSigTimeoutTime" BU_SG_REL_ Gateway_Max SG_ 2549088359 eCall_KD_Fehler 2500;
BA_REL_ "GenSigTimeoutTime" BU_SG_REL_ ICC_IO_Node SG_ 960 ZAS_Kl_S 1000;
BA_REL_ "GenSigTimeoutTime" BU_SG_REL_ ICC_IO_Node SG_ 960 ZAS_Kl_15 1000;
BA_REL_ "GenSigTimeoutTime" BU_SG_REL_ ICC_IO_Node SG_ 960 ZAS_Kl_X 1000;
BA_REL_ "GenSigTimeoutTime" BU_SG_REL_ ICC_IO_Node SG_ 960 ZAS_Kl_50_Startanforderung 1000;
BA_REL_ "GenSigTimeoutTime" BU_SG_REL_ LSH SG_ 960 ZAS_Kl_S 1000;
BA_REL_ "GenSigTimeoutTime" BU_SG_REL_ LSH SG_ 960 ZAS_Kl_15 1000;
BA_REL_ "GenSigTimeoutTime" BU_SG_REL_ LSH SG_ 1646 KL_STL_aktiv 5000;
BA_REL_ "GenSigTimeoutTime" BU_SG_REL_ LSH SG_ 1646 KL_STH_aktiv 5000;
BA_REL_ "GenSigTimeoutTime" BU_SG_REL_ LSH SG_ 1646 KL_STH_Ansteuerung 5000;
BA_REL_ "GenSigTimeoutTime" BU_SG_REL_ LSH SG_ 1646 KL_STH_Betriebsdauer 5000;
BA_REL_ "GenSigTimeoutTime" BU_SG_REL_ LSH SG_ 1640 KL_Zuheizer_Freigabe 2000;
BA_REL_ "GenSigTimeoutTime" BU_SG_REL_ LSH SG_ 2527679635 KL_LSH_DBetr_Ein 5000;
BA_REL_ "GenSigTimeoutTime" BU_SG_REL_ LSH SG_ 2527679635 KL_LSH_DBetr_Bestaet 5000;
BA_REL_ "GenSigTimeoutTime" BU_SG_REL_ LSH SG_ 2527679635 KL_Klappe_Status 5000;
BA_REL_ "GenSigTimeoutTime" BU_SG_REL_ LSH SG_ 2527679635 KL_LSH_Ansteuerung 5000;
BA_REL_ "GenSigTimeoutTime" BU_SG_REL_ LSH SG_ 2527679635 KL_Heizstufe_LSH 5000;
BA_REL_ "GenSigTimeoutTime" BU_SG_REL_ LSH SG_ 2527679635 KL_LSH_Betriebsdauer 5000;
BA_REL_ "GenSigTimeoutTime" BU_SG_REL_ LSH SG_ 1505 BCM1_Aussen_Temp_ungef 2000;
BA_REL_ "GenSigTimeoutTime" BU_SG_REL_ OCU SG_ 1712 FS_Luftfeuchte_rel 5000;
BA_REL_ "GenSigTimeoutTime" BU_SG_REL_ OCU SG_ 299 GRA_ACC_01_CRC 500;
BA_REL_ "GenSigTimeoutTime" BU_SG_REL_ OCU SG_ 299 GRA_ACC_01_BZ 500;
BA_REL_ "GenSigTimeoutTime" BU_SG_REL_ OCU SG_ 299 GRA_Hauptschalter 500;
BA_REL_ "GenSigTimeoutTime" BU_SG_REL_ OCU SG_ 299 GRA_Abbrechen 500;
BA_REL_ "GenSigTimeoutTime" BU_SG_REL_ OCU SG_ 299 GRA_Typ_Hauptschalter 500;
BA_REL_ "GenSigTimeoutTime" BU_SG_REL_ OCU SG_ 299 GRA_Limiter 500;
BA_REL_ "GenSigTimeoutTime" BU_SG_REL_ OCU SG_ 299 GRA_Tip_Setzen 500;
BA_REL_ "GenSigTimeoutTime" BU_SG_REL_ OCU SG_ 299 GRA_Tip_Hoch 500;
BA_REL_ "GenSigTimeoutTime" BU_SG_REL_ OCU SG_ 299 GRA_Tip_Runter 500;
BA_REL_ "GenSigTimeoutTime" BU_SG_REL_ OCU SG_ 299 GRA_Tip_Wiederaufnahme 500;
BA_REL_ "GenSigTimeoutTime" BU_SG_REL_ OCU SG_ 299 GRA_Verstellung_Zeitluecke 500;
BA_REL_ "GenSigTimeoutTime" BU_SG_REL_ OCU SG_ 299 GRA_Codierung 500;
BA_REL_ "GenSigTimeoutTime" BU_SG_REL_ OCU SG_ 299 GRA_Fehler 500;
BA_REL_ "GenSigTimeoutTime" BU_SG_REL_ OCU SG_ 299 GRA_LIM_Taste_verfuegbar 500;
BA_REL_ "GenSigTimeoutTime" BU_SG_REL_ OCU SG_ 299 GRA_Tip_Stufe_2 500;
BA_REL_ "GenSigTimeoutTime" BU_SG_REL_ OCU SG_ 299 GRA_Typ_Bedienteil 500;
BA_REL_ "GenSigTimeoutTime" BU_SG_REL_ OCU SG_ 299 GRA_TravelAssist 500;
BA_REL_ "GenSigTimeoutTime" BU_SG_REL_ OCU SG_ 299 GRA_PIT_Limiter 500;
BA_REL_ "GenSigTimeoutTime" BU_SG_REL_ OCU SG_ 299 GRA_reserveByte5 500;
BA_REL_ "GenSigTimeoutTime" BU_SG_REL_ OCU SG_ 299 GRA_reserveByte6 500;
BA_REL_ "GenSigTimeoutTime" BU_SG_REL_ OCU SG_ 299 GRA_reserveByte7 500;
BA_REL_ "GenSigTimeoutTime" BU_SG_REL_ OCU SG_ 299 GRA_reserveByte8 500;
BA_REL_ "GenSigTimeoutTime" BU_SG_REL_ OCU SG_ 960 ZAS_Kl_S 1000;
BA_REL_ "GenSigTimeoutTime" BU_SG_REL_ OCU SG_ 960 ZAS_Kl_15 1000;
BA_REL_ "GenSigTimeoutTime" BU_SG_REL_ OCU SG_ 960 BCM_Remotestart_Betrieb 1000;
BA_REL_ "GenSigTimeoutTime" BU_SG_REL_ OCU SG_ 1646 KL_Umluft_Taste 5000;
BA_REL_ "GenSigTimeoutTime" BU_SG_REL_ OCU SG_ 1646 KL_Geblaese_Status 5000;
BA_REL_ "GenSigTimeoutTime" BU_SG_REL_ OCU SG_ 1646 KL_SH_Soll_hl 5000;
BA_REL_ "GenSigTimeoutTime" BU_SG_REL_ OCU SG_ 1646 KL_SH_Soll_hr 5000;
BA_REL_ "GenSigTimeoutTime" BU_SG_REL_ OCU SG_ 1646 KL_Innen_Temp 5000;
BA_REL_ "GenSigTimeoutTime" BU_SG_REL_ OCU SG_ 1646 KL_Anf_AussenspiegelHzg 5000;
BA_REL_ "GenSigTimeoutTime" BU_SG_REL_ OCU SG_ 949 KL_AC_Schalter 1000;
BA_REL_ "GenSigTimeoutTime" BU_SG_REL_ OCU SG_ 949 KL_Zustand 1000;
BA_REL_ "GenSigTimeoutTime" BU_SG_REL_ OCU SG_ 949 KL_Thermomanagement 1000;
BA_REL_ "GenSigTimeoutTime" BU_SG_REL_ OCU SG_ 949 KL_StartStopp_Info 1000;
BA_REL_ "GenSigTimeoutTime" BU_SG_REL_ OCU SG_ 1640 KL_LRH_Taster 2000;
BA_REL_ "GenSigTimeoutTime" BU_SG_REL_ OCU SG_ 1640 KL_LRH_Stufe 2000;
BA_REL_ "GenSigTimeoutTime" BU_SG_REL_ OCU SG_ 1640 KL_SIH_Soll_li 2000;
BA_REL_ "GenSigTimeoutTime" BU_SG_REL_ OCU SG_ 1640 KL_SIH_Soll_re 2000;
BA_REL_ "GenSigTimeoutTime" BU_SG_REL_ OCU SG_ 1640 KL_SIL_Soll_li 2000;
BA_REL_ "GenSigTimeoutTime" BU_SG_REL_ OCU SG_ 1640 KL_SIL_Soll_re 2000;
BA_REL_ "GenSigTimeoutTime" BU_SG_REL_ OCU SG_ 1640 KL_Umluftklappe_Status 2000;
BA_REL_ "GenSigTimeoutTime" BU_SG_REL_ OCU SG_ 2589283627 KL_IstLeistung 5000;
BA_REL_ "GenSigTimeoutTime" BU_SG_REL_ OCU SG_ 2589283627 KL_Temp_Kundenwunsch 5000;
BA_REL_ "GenSigTimeoutTime" BU_SG_REL_ OCU SG_ 1505 BCM1_Aussen_Temp_ungef 2000;
BA_REL_ "GenSigTimeoutTime" BU_SG_REL_ OCU SG_ 1505 BCM1_FStatus_Aussentemp_ungef 2000;
BA_REL_ "GenSigTimeoutTime" BU_SG_REL_ OCU SG_ 1505 BCM1_OBD_FStatus_ATemp 2000;
BA_REL_ "GenSigTimeoutTime" BU_SG_REL_ OCU SG_ 1717 FSA_Luftfeuchte_rel 5000;
BA_REL_ "GenSigTimeoutTime" BU_SG_REL_ OCU SG_ 1717 FSA_Temp_Sensor 5000;
BA_REL_ "GenSigTimeoutTime" BU_SG_REL_ RDK_RS3 SG_ 960 ZAS_Kl_15 1000;
BA_REL_ "GenSigTimeoutTime" BU_SG_REL_ STH SG_ 960 ZAS_Kl_S 1000;
BA_REL_ "GenSigTimeoutTime" BU_SG_REL_ STH SG_ 960 ZAS_Kl_15 1000;
BA_REL_ "GenSigTimeoutTime" BU_SG_REL_ STH SG_ 1646 KL_STL_aktiv 5000;
BA_REL_ "GenSigTimeoutTime" BU_SG_REL_ STH SG_ 1646 KL_STH_Ansteuerung 5000;
BA_REL_ "GenSigTimeoutTime" BU_SG_REL_ STH SG_ 1646 KL_STH_Betriebsdauer 5000;
BA_REL_ "GenSigTimeoutTime" BU_SG_REL_ STH SG_ 1646 KL_Magnetventil 5000;
BA_REL_ "GenSigTimeoutTime" BU_SG_REL_ STH SG_ 1646 KL_WaPu 5000;
BA_REL_ "GenSigTimeoutTime" BU_SG_REL_ STH SG_ 1646 KL_Heizkreisventilstellung 5000;
BA_REL_ "GenSigTimeoutTime" BU_SG_REL_ STH SG_ 1649 KL_STH_Betriebsdauer_lang 5000;
BA_REL_ "GenSigTimeoutTime" BU_SG_REL_ STH SG_ 949 KL_Thermomanagement 1000;
BA_REL_ "GenSigTimeoutTime" BU_SG_REL_ STH SG_ 1640 KL_Zuheizer_Freigabe 2000;
BA_REL_ "GenSigTimeoutTime" BU_SG_REL_ STH SG_ 2527679635 KL_HUP_aktiv 5000;
BA_REL_ "GenSigTimeoutTime" BU_SG_REL_ STH SG_ 2527679635 KL_LSH_Betriebsdauer 5000;
BA_REL_ "GenSigTimeoutTime" BU_SG_REL_ STH SG_ 2527679635 KL_Temp_ZH_Soll 5000;
BA_REL_ "GenSigTimeoutTime" BU_SG_REL_ STH SG_ 1505 BCM1_Aussen_Temp_ungef 2000;
BA_REL_ "GenSigTimeoutTime" BU_SG_REL_ ZR_MIB_EINSTIEG_ab_Gen3 SG_ 886 GNSS_Nachrichtenpaket_ID3 5000;
BA_REL_ "GenSigTimeoutTime" BU_SG_REL_ ZR_MIB_EINSTIEG_ab_Gen3 SG_ 886 GNSS_Ortung_GDOP 5000;
BA_REL_ "GenSigTimeoutTime" BU_SG_REL_ ZR_MIB_EINSTIEG_ab_Gen3 SG_ 886 GNSS_Ortung_PDOP 5000;
BA_REL_ "GenSigTimeoutTime" BU_SG_REL_ ZR_MIB_EINSTIEG_ab_Gen3 SG_ 886 GNSS_Ortung_HDOP 5000;
BA_REL_ "GenSigTimeoutTime" BU_SG_REL_ ZR_MIB_EINSTIEG_ab_Gen3 SG_ 886 GNSS_Ortung_VDOP 5000;
BA_REL_ "GenSigTimeoutTime" BU_SG_REL_ ZR_MIB_EINSTIEG_ab_Gen3 SG_ 886 GNSS_Ortung_Guete_Geschwindigk 5000;
BA_REL_ "GenSigTimeoutTime" BU_SG_REL_ ZR_MIB_EINSTIEG_ab_Gen3 SG_ 886 GNSS_Ortung_Guete_Ausrichtung 5000;
BA_REL_ "GenSigTimeoutTime" BU_SG_REL_ ZR_MIB_EINSTIEG_ab_Gen3 SG_ 886 GNSS_Ortung_Guete_horizontal 5000;
BA_REL_ "GenSigTimeoutTime" BU_SG_REL_ ZR_MIB_EINSTIEG_ab_Gen3 SG_ 886 GNSS_Ortung_Guete_vertikal 5000;
BA_REL_ "GenSigTimeoutTime" BU_SG_REL_ ZR_MIB_EINSTIEG_ab_Gen3 SG_ 888 GNSS_Nachrichtenpaket_ID4 5000;
BA_REL_ "GenSigTimeoutTime" BU_SG_REL_ ZR_MIB_EINSTIEG_ab_Gen3 SG_ 888 GNSS_Ortung_Zeit_in_GPSWoche 5000;
BA_REL_ "GenSigTimeoutTime" BU_SG_REL_ ZR_MIB_EINSTIEG_ab_Gen3 SG_ 888 GNSS_Ortung_Hoehe 5000;
BA_REL_ "GenSigTimeoutTime" BU_SG_REL_ ZR_MIB_EINSTIEG_ab_Gen3 SG_ 891 GNSS_UTC_Zeit 5000;
BA_REL_ "GenSigTimeoutTime" BU_SG_REL_ ZR_MIB_EINSTIEG_ab_Gen3 SG_ 891 GNSS_Empfaenger_Status 5000;
BA_REL_ "GenSigTimeoutTime" BU_SG_REL_ ZR_MIB_EINSTIEG_ab_Gen3 SG_ 891 GNSS_GPS_in_Nutzung 5000;
BA_REL_ "GenSigTimeoutTime" BU_SG_REL_ ZR_MIB_EINSTIEG_ab_Gen3 SG_ 891 GNSS_GLONASS_in_Nutzung 5000;
BA_REL_ "GenSigTimeoutTime" BU_SG_REL_ ZR_MIB_EINSTIEG_ab_Gen3 SG_ 891 GNSS_Empfangbare_Satelliten 5000;
BA_REL_ "GenSigTimeoutTime" BU_SG_REL_ ZR_MIB_EINSTIEG_ab_Gen3 SG_ 891 GNSS_Sichtbare_Satelliten 5000;
BA_REL_ "GenSigTimeoutTime" BU_SG_REL_ ZR_MIB_EINSTIEG_ab_Gen3 SG_ 891 GNSS_Genutzte_Satelliten 5000;
BA_REL_ "GenSigTimeoutTime" BU_SG_REL_ ZR_MIB_EINSTIEG_ab_Gen3 SG_ 891 GNSS_Nachrichtenpaket_ID5 5000;
BA_REL_ "GenSigTimeoutTime" BU_SG_REL_ ZR_MIB_EINSTIEG_ab_Gen3 SG_ 1364 GNSS_Sat_Info_Sat_ID_1 5000;
BA_REL_ "GenSigTimeoutTime" BU_SG_REL_ ZR_MIB_EINSTIEG_ab_Gen3 SG_ 1364 GNSS_Sat_Info_SNR_ID_1 5000;
BA_REL_ "GenSigTimeoutTime" BU_SG_REL_ ZR_MIB_EINSTIEG_ab_Gen3 SG_ 1364 GNSS_Sat_Info_Azimuth_ID_1 5000;
BA_REL_ "GenSigTimeoutTime" BU_SG_REL_ ZR_MIB_EINSTIEG_ab_Gen3 SG_ 1364 GNSS_Sat_Info_Hoehenwinkel_ID_1 5000;
BA_REL_ "GenSigTimeoutTime" BU_SG_REL_ ZR_MIB_EINSTIEG_ab_Gen3 SG_ 1364 GNSS_Nachrichtenpaket_ID6 5000;
BA_REL_ "GenSigTimeoutTime" BU_SG_REL_ ZR_MIB_EINSTIEG_ab_Gen3 SG_ 2463978722 GNSS_DR_Nachrichtenpaket_ID1 1000;
BA_REL_ "GenSigTimeoutTime" BU_SG_REL_ ZR_MIB_EINSTIEG_ab_Gen3 SG_ 2463978722 GNSS_DR_Breite_Ortung 1000;
BA_REL_ "GenSigTimeoutTime" BU_SG_REL_ ZR_MIB_EINSTIEG_ab_Gen3 SG_ 2463978722 GNSS_DR_Richtung_Breite_Ortung 1000;
BA_REL_ "GenSigTimeoutTime" BU_SG_REL_ ZR_MIB_EINSTIEG_ab_Gen3 SG_ 2463978722 GNSS_DR_Laenge_Ortung 1000;
BA_REL_ "GenSigTimeoutTime" BU_SG_REL_ ZR_MIB_EINSTIEG_ab_Gen3 SG_ 2463978722 GNSS_DR_Richtung_Laenge_Ortung 1000;
BA_REL_ "GenSigTimeoutTime" BU_SG_REL_ ZR_MIB_EINSTIEG_ab_Gen3 SG_ 2463978723 GNSS_DR_Nachrichtenpaket_ID2 1000;
BA_REL_ "GenSigTimeoutTime" BU_SG_REL_ ZR_MIB_EINSTIEG_ab_Gen3 SG_ 2463978723 GNSS_DR_Ortung_Ausrichtung 1000;
BA_REL_ "GenSigTimeoutTime" BU_SG_REL_ ZR_MIB_EINSTIEG_ab_Gen3 SG_ 2463978723 GNSS_DR_Ortung_2D_Geschw_u_Grund 1000;
BA_REL_ "GenSigTimeoutTime" BU_SG_REL_ ZR_MIB_EINSTIEG_ab_Gen3 SG_ 2463978724 GNSS_DR_Nachrichtenpaket_ID3 1000;
BA_REL_ "GenSigTimeoutTime" BU_SG_REL_ ZR_MIB_EINSTIEG_ab_Gen3 SG_ 2463978724 GNSS_DR_Ortung_Guete_Geschwindig 1000;
BA_REL_ "GenSigTimeoutTime" BU_SG_REL_ ZR_MIB_EINSTIEG_ab_Gen3 SG_ 2463978724 GNSS_DR_Ortung_Guete_Ausrichtung 1000;
BA_REL_ "GenSigTimeoutTime" BU_SG_REL_ ZR_MIB_EINSTIEG_ab_Gen3 SG_ 2463978724 GNSS_DR_Ortung_Guete_horizontal 1000;
BA_REL_ "GenSigTimeoutTime" BU_SG_REL_ ZR_MIB_EINSTIEG_ab_Gen3 SG_ 2463978724 GNSS_DR_Ortung_Guete_vertikal 1000;
BA_REL_ "GenSigTimeoutTime" BU_SG_REL_ ZR_MIB_EINSTIEG_ab_Gen3 SG_ 2463978726 GNSS_DR_UTC_Zeit 1000;
BA_REL_ "GenSigTimeoutTime" BU_SG_REL_ ZR_MIB_EINSTIEG_ab_Gen3 SG_ 2463978753 KST_Sonderzustand_Status 5000;
BA_REL_ "GenSigTimeoutTime" BU_SG_REL_ ZR_MIB_EINSTIEG_ab_Gen3 SG_ 2463978753 KST_Sonderzustand_Anforderung 5000;
BA_REL_ "GenSigTimeoutTime" BU_SG_REL_ ZR_MIB_EINSTIEG_ab_Gen3 SG_ 2463978753 KST_Freigabe_Zustand 5000;
BA_REL_ "GenSigTimeoutTime" BU_SG_REL_ ZR_MIB_EINSTIEG_ab_Gen3 SG_ 960 ZAS_Kl_S 1000;
BA_REL_ "GenSigTimeoutTime" BU_SG_REL_ ZR_MIB_EINSTIEG_ab_Gen3 SG_ 960 ZAS_Kl_15 1000;
BA_REL_ "GenSigTimeoutTime" BU_SG_REL_ ZR_MIB_EINSTIEG_ab_Gen3 SG_ 1646 KL_Innen_Temp 5000;
BA_REL_ "GenSigTimeoutTime" BU_SG_REL_ ZR_MIB_EINSTIEG_ab_Gen3 SG_ 1640 KL_Geblspng_Soll 2000;
BA_REL_ "GenSigTimeoutTime" BU_SG_REL_ ZR_MIB_EINSTIEG_ab_Gen3 SG_ 2527679635 KL_ZR_Anforderung 5000;
BA_REL_ "GenSigTimeoutTime" BU_SG_REL_ ZR_MIB_EINSTIEG_ab_Gen3 SG_ 2589283627 KL_Texte 5000;
BA_REL_ "GenSigTimeoutTime" BU_SG_REL_ ZR_MIB_OPTION_ab_Gen3 SG_ 2463978753 KST_Sonderzustand_Status 5000;
BA_REL_ "GenSigTimeoutTime" BU_SG_REL_ ZR_MIB_OPTION_ab_Gen3 SG_ 2463978753 KST_Sonderzustand_Anforderung 5000;
BA_REL_ "GenSigTimeoutTime" BU_SG_REL_ ZR_MIB_OPTION_ab_Gen3 SG_ 2463978753 KST_Freigabe_Zustand 5000;
BA_REL_ "GenSigTimeoutTime" BU_SG_REL_ ZR_MIB_OPTION_ab_Gen3 SG_ 960 ZAS_Kl_S 1000;
BA_REL_ "GenSigTimeoutTime" BU_SG_REL_ ZR_MIB_OPTION_ab_Gen3 SG_ 960 ZAS_Kl_15 1000;
BA_REL_ "GenSigTimeoutTime" BU_SG_REL_ ZR_MIB_OPTION_ab_Gen3 SG_ 1646 KL_Innen_Temp 5000;
BA_REL_ "GenSigTimeoutTime" BU_SG_REL_ ZR_MIB_OPTION_ab_Gen3 SG_ 2527679635 KL_ZR_Anforderung 5000;
BA_REL_ "GenSigTimeoutTime" BU_SG_REL_ ZR_MIB_OPTION_ab_Gen3 SG_ 2589283627 KL_Texte 5000;
BA_REL_ "GenSigTimeoutTime" BU_SG_REL_ ZR_MIB_TOP_ab_Gen3 SG_ 886 GNSS_Nachrichtenpaket_ID3 5000;
BA_REL_ "GenSigTimeoutTime" BU_SG_REL_ ZR_MIB_TOP_ab_Gen3 SG_ 886 GNSS_Ortung_GDOP 5000;
BA_REL_ "GenSigTimeoutTime" BU_SG_REL_ ZR_MIB_TOP_ab_Gen3 SG_ 886 GNSS_Ortung_PDOP 5000;
BA_REL_ "GenSigTimeoutTime" BU_SG_REL_ ZR_MIB_TOP_ab_Gen3 SG_ 886 GNSS_Ortung_HDOP 5000;
BA_REL_ "GenSigTimeoutTime" BU_SG_REL_ ZR_MIB_TOP_ab_Gen3 SG_ 886 GNSS_Ortung_VDOP 5000;
BA_REL_ "GenSigTimeoutTime" BU_SG_REL_ ZR_MIB_TOP_ab_Gen3 SG_ 886 GNSS_Ortung_Guete_Geschwindigk 5000;
BA_REL_ "GenSigTimeoutTime" BU_SG_REL_ ZR_MIB_TOP_ab_Gen3 SG_ 886 GNSS_Ortung_Guete_Ausrichtung 5000;
BA_REL_ "GenSigTimeoutTime" BU_SG_REL_ ZR_MIB_TOP_ab_Gen3 SG_ 886 GNSS_Ortung_Guete_horizontal 5000;
BA_REL_ "GenSigTimeoutTime" BU_SG_REL_ ZR_MIB_TOP_ab_Gen3 SG_ 886 GNSS_Ortung_Guete_vertikal 5000;
BA_REL_ "GenSigTimeoutTime" BU_SG_REL_ ZR_MIB_TOP_ab_Gen3 SG_ 888 GNSS_Nachrichtenpaket_ID4 5000;
BA_REL_ "GenSigTimeoutTime" BU_SG_REL_ ZR_MIB_TOP_ab_Gen3 SG_ 888 GNSS_Ortung_Zeit_in_GPSWoche 5000;
BA_REL_ "GenSigTimeoutTime" BU_SG_REL_ ZR_MIB_TOP_ab_Gen3 SG_ 888 GNSS_Ortung_Hoehe 5000;
BA_REL_ "GenSigTimeoutTime" BU_SG_REL_ ZR_MIB_TOP_ab_Gen3 SG_ 891 GNSS_UTC_Zeit 5000;
BA_REL_ "GenSigTimeoutTime" BU_SG_REL_ ZR_MIB_TOP_ab_Gen3 SG_ 891 GNSS_Empfaenger_Status 5000;
BA_REL_ "GenSigTimeoutTime" BU_SG_REL_ ZR_MIB_TOP_ab_Gen3 SG_ 891 GNSS_GPS_in_Nutzung 5000;
BA_REL_ "GenSigTimeoutTime" BU_SG_REL_ ZR_MIB_TOP_ab_Gen3 SG_ 891 GNSS_GLONASS_in_Nutzung 5000;
BA_REL_ "GenSigTimeoutTime" BU_SG_REL_ ZR_MIB_TOP_ab_Gen3 SG_ 891 GNSS_Empfangbare_Satelliten 5000;
BA_REL_ "GenSigTimeoutTime" BU_SG_REL_ ZR_MIB_TOP_ab_Gen3 SG_ 891 GNSS_Sichtbare_Satelliten 5000;
BA_REL_ "GenSigTimeoutTime" BU_SG_REL_ ZR_MIB_TOP_ab_Gen3 SG_ 891 GNSS_Genutzte_Satelliten 5000;
BA_REL_ "GenSigTimeoutTime" BU_SG_REL_ ZR_MIB_TOP_ab_Gen3 SG_ 891 GNSS_Nachrichtenpaket_ID5 5000;
BA_REL_ "GenSigTimeoutTime" BU_SG_REL_ ZR_MIB_TOP_ab_Gen3 SG_ 1364 GNSS_Sat_Info_Sat_ID_1 5000;
BA_REL_ "GenSigTimeoutTime" BU_SG_REL_ ZR_MIB_TOP_ab_Gen3 SG_ 1364 GNSS_Sat_Info_SNR_ID_1 5000;
BA_REL_ "GenSigTimeoutTime" BU_SG_REL_ ZR_MIB_TOP_ab_Gen3 SG_ 1364 GNSS_Sat_Info_Azimuth_ID_1 5000;
BA_REL_ "GenSigTimeoutTime" BU_SG_REL_ ZR_MIB_TOP_ab_Gen3 SG_ 1364 GNSS_Sat_Info_Hoehenwinkel_ID_1 5000;
BA_REL_ "GenSigTimeoutTime" BU_SG_REL_ ZR_MIB_TOP_ab_Gen3 SG_ 1364 GNSS_Nachrichtenpaket_ID6 5000;
BA_REL_ "GenSigTimeoutTime" BU_SG_REL_ ZR_MIB_TOP_ab_Gen3 SG_ 2463978753 KST_Sonderzustand_Status 5000;
BA_REL_ "GenSigTimeoutTime" BU_SG_REL_ ZR_MIB_TOP_ab_Gen3 SG_ 2463978753 KST_Sonderzustand_Anforderung 5000;
BA_REL_ "GenSigTimeoutTime" BU_SG_REL_ ZR_MIB_TOP_ab_Gen3 SG_ 1640 KL_Geblspng_Soll 2000;
BA_REL_ "GenSigTimeoutTime" BU_SG_REL_ ZR_MIB_TOP_ab_Gen3 SG_ 1640 KL_Geblspng_Fond_Soll 2000;
BA_REL_ "GenSigTimeoutTime" BU_SG_REL_ ZR_MIB_TOP_ab_Gen3 SG_ 1640 KL_I_Geblaese 2000;
BA_REL_ "GenSigTimeoutTime" BU_SG_REL_ ZR_MIB_TOP_ab_Gen3 SG_ 2527679635 KL_ZR_Anforderung 5000;
VAL_ 886 GNSS_Ortung_GDOP 510 "Init" 511 "Fehler" ;
VAL_ 886 GNSS_Ortung_PDOP 510 "Init" 511 "Fehler" ;
VAL_ 886 GNSS_Ortung_HDOP 510 "Init" 511 "Fehler" ;
VAL_ 886 GNSS_Ortung_VDOP 510 "Init" 511 "Fehler" ;
VAL_ 886 GNSS_Ortung_Guete_Geschwindigk 62 "Init" 63 "Fehler" ;
VAL_ 886 GNSS_Ortung_Guete_Ausrichtung 62 "Init" 63 "Fehler" ;
VAL_ 886 GNSS_Ortung_Guete_horizontal 254 "Init" 255 "Fehler" ;
VAL_ 886 GNSS_Ortung_Guete_vertikal 62 "Init" 63 "Fehler" ;
VAL_ 888 GNSS_Ortung_Zeit_in_GPSWoche 1073741822 "Init" 1073741823 "Fehler" ;
VAL_ 888 GNSS_Ortung_Hoehe 4094 "Init" 4095 "Fehler" ;
VAL_ 891 GNSS_UTC_Zeit 0 "Init" ;
VAL_ 891 GNSS_Empfaenger_Status 0 "Backup_Mode" 1 "Live" ;
VAL_ 891 GNSS_GPS_in_Nutzung 0 "unbenutzt" 1 "benutzt" ;
VAL_ 891 GNSS_GLONASS_in_Nutzung 0 "unbenutzt" 1 "benutzt" ;
VAL_ 891 GNSS_Empfangbare_Satelliten 0 "Init" 31 "31_oder_mehr" ;
VAL_ 891 GNSS_Sichtbare_Satelliten 0 "Init" 31 "31_oder_mehr" ;
VAL_ 891 GNSS_Genutzte_Satelliten 0 "Init" 31 "31_oder_mehr" ;
VAL_ 1364 GNSS_Sat_Info_SNR_ID_1 31 "SNR_mehr_als_61_dB" ;
VAL_ 1364 GNSS_Sat_Info_Azimuth_ID_1 511 "Init" ;
VAL_ 1364 GNSS_Sat_Info_Hoehenwinkel_ID_1 127 "Init" ;
VAL_ 1343 GNSS_V_Geschw_2D 16381 "hoeher_als_163" 16382 "Init" 16383 "Fehler" ;
VAL_ 1343 GNSS_V_Geschw_2D_Guete95 1022 "Init" 1023 "Fehler" ;
VAL_ 1343 GNSS_V_Geschw_Vertikal 32764 "hoeher_als_163" 32765 "kleiner_als_minus_163" 32766 "Init" 32767 "Fehler" ;
VAL_ 1343 GNSS_V_Geschw_Vertikal_Guete95 1022 "Init" 1023 "Fehler" ;
VAL_ 1343 GNSS_V_FIX_Typ 0 "Init" 1 "No_Fix" 2 "2D_Fix" 3 "3D_Fix" ;
VAL_ 1343 GNSS_V_Latenz_vollstaendig 1022 "Init" 1023 "Fehler" ;
VAL_ 1343 GNSS_V_Daten_Veraltet 0 "Veraltet" 1 "Neu" ;
VAL_ 2463978722 GNSS_DR_Breite_Ortung 134217726 "Init" 134217727 "Fehler" ;
VAL_ 2463978722 GNSS_DR_Richtung_Breite_Ortung 0 "Nord" 1 "Sued" ;
VAL_ 2463978722 GNSS_DR_Laenge_Ortung 268435454 "Init" 268435455 "Fehler" ;
VAL_ 2463978722 GNSS_DR_Richtung_Laenge_Ortung 0 "Ost" 1 "West" ;
VAL_ 2463978723 GNSS_DR_Ortung_Ausrichtung 4094 "Init" 4095 "Fehler" ;
VAL_ 2463978723 GNSS_DR_Ortung_2D_Geschw_u_Grund 510 "Init" 511 "Fehler" ;
VAL_ 2463978724 GNSS_DR_Ortung_Guete_Geschwindig 62 "Init" 63 "Fehler" ;
VAL_ 2463978724 GNSS_DR_Ortung_Guete_Ausrichtung 62 "Init" 63 "Fehler" ;
VAL_ 2463978724 GNSS_DR_Ortung_Guete_horizontal 254 "Init" 255 "Fehler" ;
VAL_ 2463978724 GNSS_DR_Ortung_Guete_vertikal 62 "Init" 63 "Fehler" ;
VAL_ 2463978726 GNSS_DR_UTC_Zeit 0 "Init" ;
VAL_ 299 GRA_Hauptschalter 0 "Aus_Taster_nicht_betaetigt" 1 "Ein_Taster_betaetigt" ;
VAL_ 299 GRA_Abbrechen 0 "nicht_betaetigt" 1 "betaetigt" ;
VAL_ 299 GRA_Typ_Hauptschalter 0 "gerasteter_Lenkstockschalter" 1 "getasteter_Lenkstockschalter" ;
VAL_ 299 GRA_Limiter 0 "nicht_betaetigt" 1 "betaetigt" ;
VAL_ 299 GRA_Tip_Setzen 0 "nicht_betaetigt" 1 "betaetigt" ;
VAL_ 299 GRA_Tip_Hoch 0 "nicht_betaetigt" 1 "betaetigt" ;
VAL_ 299 GRA_Tip_Runter 0 "nicht_betaetigt" 1 "betaetigt" ;
VAL_ 299 GRA_Tip_Wiederaufnahme 0 "nicht_betaetigt" 1 "betaetigt" ;
VAL_ 299 GRA_Verstellung_Zeitluecke 0 "Taste_nicht_betaetigt" 1 "Dist_minus_1" 2 "Dist_plus_1" 3 "Dist_Toggle" ;
VAL_ 299 GRA_Codierung 0 "kein_Hebel" 1 "GRA_Hebel" 2 "ACC_Hebel" 3 "Limiter_Only" ;
VAL_ 299 GRA_Fehler 0 "kein_Fehler" 1 "Fehler" ;
VAL_ 299 GRA_LIM_Taste_verfuegbar 0 "Limiter_Taste_nicht_vorhanden" 1 "Limiter_Taste_vorhanden" ;
VAL_ 299 GRA_Tip_Stufe_2 0 "Tip_Stufe_1_keine_Betaetigung" 1 "Tip_Stufe_2" ;
VAL_ 299 GRA_Typ_Bedienteil 0 "Init" 1 "4_Positions_Bedienteil" 2 "6_Positions_Bedienteil" 3 "8_Positions_Bedienteil" 4 "PAG_5_Positions_Bedienteil" 5 "VW_MFL_Gen2" 6 "VW_MFL_Gen3" 7 "PAG_DX1_Bedienteil" ;
VAL_ 299 GRA_TravelAssist 0 "nicht_betaetigt" 1 "betaetigt" ;
VAL_ 299 GRA_PIT_Limiter 0 "nicht_betaetigt" 1 "betaetigt" ;
VAL_ 29 WFS_IMMO_OCU_CRC 0 "Init" ;
VAL_ 29 WFS_IMMO_OCU_RND 0 "Init" ;
VAL_ 1426 KY_ID_Geber1_im_Fzg 0 "inaktiv" 1 "aktiv" ;
VAL_ 1426 KY_ID_Geber2_im_Fzg 0 "inaktiv" 1 "aktiv" ;
VAL_ 1426 KY_ID_Geber3_im_Fzg 0 "inaktiv" 1 "aktiv" ;
VAL_ 1426 KY_ID_Geber4_im_Fzg 0 "inaktiv" 1 "aktiv" ;
VAL_ 1426 KY_Startknopf_Bel 0 "inaktiv" 1 "aktiv" ;
VAL_ 1426 KY_ID_Geber_Suche 0 "inaktiv" 1 "aktiv" ;
VAL_ 1426 KY_Meldungen 0 "keine_Meldung" 1 "Schluessel_nicht_gefunden" 2 "Schluessel_im_Kofferraum" 3 "Schluessel_im_Fahrzeug" 4 "Kessy_defekt" ;
VAL_ 1426 KY_Gong_600 0 "inaktiv" 1 "aktiv" ;
VAL_ 1426 KY_Passiv_Autolock_Menue 0 "inaktiv" 1 "aktiv" ;
VAL_ 1426 KY_Passiv_Autolock_Akt 0 "inaktiv" 1 "aktiv" ;
VAL_ 1426 KY_Passiv_Autolock 0 "inaktiv" 1 "aktiv" ;
VAL_ 1426 KY_Passiv_Autounlock 0 "inaktiv" 1 "aktiv" ;
VAL_ 1426 KY_Gestik_HD 0 "inaktiv" 1 "aktiv" ;
VAL_ 1426 KY_StartStopp_Info 0 "Motorlauf_nicht_notwendig_(Stoppfreigabe)" 1 "Motoranlauf_nicht_zwingend_notwendig_(Stoppverbot,keine_Startanforderung)" 2 "Motoranlauf_zwingend_notwendig_(Startanforderung)" 3 "Systemfehler" ;
VAL_ 1426 KY_Fzg_Verlassen_erkannt 0 "nicht_erkannt" 1 "erkannt" ;
VAL_ 1426 KY_Fzg_Zugang_erkannt 0 "nicht_erkannt" 1 "erkannt" ;
VAL_ 1426 KY_EasyClose_Abbruch 0 "EasyClose_kein_Abbruch" 1 "EasyClose_Abbruch" ;
VAL_ 1426 KY_EasyClose_Status 0 "Lampe_AUS" 1 "Lampe_EIN" 2 "Lampe_NORMAL" 3 "Lampe_HEKTIK" 4 "Akustik_Verweigerung" ;
VAL_ 1426 KY_HD_Auffahrt 0 "keine_Anforderung" 1 "HD_Auffahrt_angefordert" ;
VAL_ 1426 KY_HD_Zufahrt 0 "keine_Anforderung" 1 "HD_Zufahrt_angefordert" ;
VAL_ 1426 KY_Aktive_LFScans 0 "Init" 1 "Entry_Exit_Scan_1" 2 "Entry_Exit_Scan_2" 3 "GO_Scan_1" 4 "GO_Scan_2" 5 "Keyminder_Scan" 6 "ServiceKey1_Scan" 7 "ServiceKey2_Scan" 8 "Komfortlauf_RW_Begrenzer" 9 "Komfortlauf_RW_Begrenzer_EHeck" 10 "RSSI_Scan_EasyClose" 11 "PU_Scan" 12 "Diagnose_Scan" ;
VAL_ 1426 KY_LF_Aktiv 0 "Funktempfang_nicht_aktiv" 1 "LF_Funkempfang_aktiv" ;
VAL_ 1426 KY_AnzKoord_Info 0 "Init" 1 "Keyminder_Suche_erfolgreich" 2 "Keyminder_Suche_negativ" ;
VAL_ 1426 KY_Schluesselposition_9 0 "nicht_gefunden" 1 "im_Innenraum_gefunden" 2 "im_Aussenraum_gefunden_nah" 3 "im_Aussenraum_gefunden_fern" ;
VAL_ 1426 KY_Schluesselposition_1 0 "nicht_gefunden" 1 "im_Innenraum_gefunden" 2 "im_Aussenraum_gefunden_nah" 3 "im_Aussenraum_gefunden_fern" ;
VAL_ 1426 KY_Schluesselposition_2 0 "nicht_gefunden" 1 "im_Innenraum_gefunden" 2 "im_Aussenraum_gefunden_nah" 3 "im_Aussenraum_gefunden_fern" ;
VAL_ 1426 KY_Schluesselposition_3 0 "nicht_gefunden" 1 "im_Innenraum_gefunden" 2 "im_Aussenraum_gefunden_nah" 3 "im_Aussenraum_gefunden_fern" ;
VAL_ 1426 KY_Schluesselposition_4 0 "nicht_gefunden" 1 "im_Innenraum_gefunden" 2 "im_Aussenraum_gefunden_nah" 3 "im_Aussenraum_gefunden_fern" ;
VAL_ 1426 KY_Schluesselposition_5 0 "nicht_gefunden" 1 "im_Innenraum_gefunden" 2 "im_Aussenraum_gefunden_nah" 3 "im_Aussenraum_gefunden_fern" ;
VAL_ 1426 KY_Schluesselposition_6 0 "nicht_gefunden" 1 "im_Innenraum_gefunden" 2 "im_Aussenraum_gefunden_nah" 3 "im_Aussenraum_gefunden_fern" ;
VAL_ 1426 KY_Schluesselposition_7 0 "nicht_gefunden" 1 "im_Innenraum_gefunden" 2 "im_Aussenraum_gefunden_nah" 3 "im_Aussenraum_gefunden_fern" ;
VAL_ 1426 KY_Schluesselposition_8 0 "nicht_gefunden" 1 "im_Innenraum_gefunden" 2 "im_Aussenraum_gefunden_nah" 3 "im_Aussenraum_gefunden_fern" ;
VAL_ 960 RSt_Fahrerhinweise 0 "Init" 1 "Fahreruebernahme_Hinweis_ZAT_Automat_ohne_Gong" 2 "Fahreruebernahme_Hinweis_ZAT_Automat_mit_Gong" 3 "Fahreruebernahme_Hinweis_ZAT_Handschalter_ohne_Gong" 4 "Fahreruebernahme_Hinweis_ZAT_Handschalter_mit_Gong" 5 "Fahreruebernahme_Hinweis_ZAS_Automat_ohne_Gong" 6 "Fahreruebernahme_Hinweis_ZAS_Automat_mit_Gong" 7 "Fahreruebernahme_Hinweis_ZAS_Handschalter_ohne_Gong" 8 "Fahreruebernahme_Hinweis_ZAS_Handschalter_mit_Gong" 9 "RemoteStart_aktiv_ohne_Gong" 10 "RemoteStart_aktiv_mit_Gong" 11 "void" 12 "void" 13 "void" 14 "void" 15 "void" ;
VAL_ 960 ZAS_Kl_S 0 "aus" 1 "S_Kontakt_ein" ;
VAL_ 960 ZAS_Kl_15 0 "aus" 1 "ein" ;
VAL_ 960 ZAS_Kl_X 0 "aus" 1 "ein" ;
VAL_ 960 ZAS_Kl_50_Startanforderung 0 "aus" 1 "KL50_ein_Startwunsch_Fahrer" ;
VAL_ 960 BCM_Remotestart_Betrieb 0 "kein_RS_Betrieb" 1 "RS_Betrieb" ;
VAL_ 960 ZAS_Kl_Infotainment 0 "inaktiv" 1 "aktiv" ;
VAL_ 960 BCM_Remotestart_KL15_Anf 0 "inaktiv" 1 "aktiv" ;
VAL_ 960 BCM_Remotestart_MO_Start 0 "nicht_angefordert" 1 "angefordert" ;
VAL_ 960 KST_Warn_P1_ZST_def 0 "nicht_defekt" 1 "defekt" ;
VAL_ 960 KST_Warn_P2_ZST_def 0 "nicht_defekt" 1 "defekt" ;
VAL_ 960 KST_Fahrerhinweis_1 0 "inaktiv" 1 "aktiv" ;
VAL_ 960 KST_Fahrerhinweis_2 0 "inaktiv" 1 "aktiv" ;
VAL_ 960 BCM_Ausparken_Betrieb 0 "kein_Betrieb" 1 "Ausparkvorgang_aktiv" ;
VAL_ 960 KST_Fahrerhinweis_4 0 "inaktiv" 1 "aktiv" ;
VAL_ 960 KST_Fahrerhinweis_5 0 "inaktiv" 1 "aktiv" ;
VAL_ 960 KST_Fahrerhinweis_6 0 "inaktiv" 1 "aktiv" ;
VAL_ 2463978753 KST_WFS_Fahrfreigabe_Anforderung 0 "Keine" 1 "Uneingeschraenkt" 2 "Eingeschraenkt" ;
VAL_ 2463978753 KST_Sonderzustand_Status 0 "Init" 1 "Uebergang_neue_Anforderung" 2 "Aktiv" 3 "Fehler" ;
VAL_ 2463978753 KST_Sonderzustand_Anforderung 0 "Init" 1 "RemoteStart" 2 "RemoteParkAssist" 3 "IntelligentParkAssist" 4 "TrainiertesParken" 5 "OnlineRemoteUpdate" 6 "Einfrierschutz" 7 "Klemme15ViaDiagnose" 8 "RueckwandklappenSicherungPDC" 9 "ParkHausPilot" 10 "AnhaengerAnkuppelAssistent" 11 "MotorWeiterlaufSchaltung" 31 "Fehler" ;
VAL_ 2463978753 KST_ComfortReadyStatus 0 "aus" 1 "ComfortReadyStatus_ein" ;
VAL_ 2463978753 KST_Freigabe_Zustand 0 "Init" 1 "Kl50_freigegeben" 2 "Kl50_gesperrt" ;
VAL_ 1646 KL_STL_aktiv 0 "Standlueftung_nicht_aktiv" 1 "Standlueftung_aktiv" ;
VAL_ 1646 KL_STH_aktiv 0 "Standheizung_nicht_aktiv" 1 "Standheizung_aktiv" ;
VAL_ 1646 KL_Solarluefter_aktiv 0 "Solarluefter_nicht_aktiv" 1 "Solarluefter_aktiv__auto" ;
VAL_ 1646 KL_Umluft_Taste 0 "Taste_nicht_gedrueckt" 1 "Taste_gedrueckt" ;
VAL_ 1646 KL_Geblaese_Fond_Status 0 "Geblaese_aus" 1 "Geblaesestufe_10" 2 "Geblaesestufe_20" 3 "Geblaesestufe_30" 4 "Geblaesestufe_40" 5 "Geblaesestufe_50" 6 "Geblaesestufe_60" 7 "Geblaesestufe_70" 8 "Geblaesestufe_80" 9 "Geblaesestufe_90" 10 "Geblaesestufe_100" 14 "Init" 15 "Fehler" ;
VAL_ 1646 KL_STH_Ansteuerung 0 "Aus" 1 "Ein" 2 "Ein_mit_Motorvorwaermung" 3 "Heizleistung_reduziert" ;
VAL_ 1646 KL_Magnetventil 0 "Aus" 1 "Ein" ;
VAL_ 1646 KL_WaPu 0 "Wasserpumpe_aus" 1 "Wasserpumpe_aktiv" ;
VAL_ 1646 KL_Geblaese_Status 0 "Geblaese_aus" 1 "Geblaesestufe_10" 2 "Geblaesestufe_20" 3 "Geblaesestufe_30" 4 "Geblaesestufe_40" 5 "Geblaesestufe_50" 6 "Geblaesestufe_60" 7 "Geblaesestufe_70" 8 "Geblaesestufe_80" 9 "Geblaesestufe_90" 10 "Geblaesestufe_100" 14 "Init" 15 "Fehler" ;
VAL_ 1646 KL_Restwaerme_aktiv 0 "inaktiv" 1 "aktiv" ;
VAL_ 1646 KL_Kompressorkupplung 0 "oeffnen" 1 "schliessen" ;
VAL_ 1646 KL_BCmE_Livetip_Freigabe 0 "Anzeige_Livetip_nicht_zulaessig" 1 "Anzeige_Livetip_zulaessig" ;
VAL_ 1646 KL_ErwVK_Anf 0 "nicht_angefordert" 1 "angefordert" ;
VAL_ 1646 KL_Innen_Temp 253 "nicht_verbaut" 254 "nicht_verfuegbar" 255 "Fehler" ;
VAL_ 1646 KL_I_Geblaese_Fond 255 "Fehler" ;
VAL_ 1646 KL_Anf_AussenspiegelHzg 0 "nicht_angefordert" 1 "angefordert" ;
VAL_ 1646 KL_Heizkreisventilstellung 0 "Init" 1 "Ventilstellung_gem_Anforderung" 2 "Ventilstellung_abweichend_Anf" 3 "Fehler" ;
VAL_ 1646 KL_FSH_Automatikbetrieb 0 "aus" 1 "angefordert_durch_Regelung" ;
VAL_ 1646 KL_SIH_LEH_Verteilung_VL 0 "gleichmaessige_Verteilung" 1 "Sitz_Prio_Hoch" 2 "Sitz_Prio_Mittel" 3 "Sitz_Prio_Niedrig" 4 "Lehne_Prio_Niedrig" 5 "Lehne_Prio_Mittel" 6 "Lehne_Prio_Hoch" ;
VAL_ 1646 KL_SIH_LEL_Verteilung_VL 0 "gleichmaessige_Verteilung" 1 "Sitz_Prio_Hoch" 2 "Sitz_Prio_Mittel" 3 "Sitz_Prio_Niedrig" 4 "Lehne_Prio_Niedrig" 5 "Lehne_Prio_Mittel" 6 "Lehne_Prio_Hoch" ;
VAL_ 1646 KL_SIH_LEH_Verteilung_VR 0 "gleichmaessige_Verteilung" 1 "Sitz_Prio_Hoch" 2 "Sitz_Prio_Mittel" 3 "Sitz_Prio_Niedrig" 4 "Lehne_Prio_Niedrig" 5 "Lehne_Prio_Mittel" 6 "Lehne_Prio_Hoch" ;
VAL_ 1646 KL_SIH_LEL_Verteilung_VR 0 "gleichmaessige_Verteilung" 1 "Sitz_Prio_Hoch" 2 "Sitz_Prio_Mittel" 3 "Sitz_Prio_Niedrig" 4 "Lehne_Prio_Niedrig" 5 "Lehne_Prio_Mittel" 6 "Lehne_Prio_Hoch" ;
VAL_ 1649 KL_ZZ_Status_Timer 0 "Timer_n_aktiv_bzw_loeschen" 1 "Timer_aktiv_bzw_aktivieren" ;
VAL_ 1649 KL_ZZ_Monat 0 "Init" ;
VAL_ 1649 KL_ErwVK_Scheibenheizung 0 "nicht_aktiv" 1 "Scheibenheizung_aktiv" ;
VAL_ 1649 KL_ErwVK_Heckzone2_links 0 "nicht_angefordert" 1 "Heckzone2_rechts_angefordert" ;
VAL_ 1649 KL_ErwVK_Heckzone2_rechts 0 "nicht_angefordert" 1 "Heckzone2_rechts_angefordert" ;
VAL_ 1649 KL_ZZ_Betriebsmodus 0 "Do_not_Care" 1 "ECO" 2 "Standard" 3 "Standard_plus" 4 "Comfort" ;
VAL_ 1649 KL_ZZ_Tag 0 "Init" ;
VAL_ 1649 KL_Betriebsmodus_FH 0 "undefined__init" 1 "Klemme15" 2 "Standheizung" 3 "Restwaerme" 4 "Nachlauf" 5 "Standlueften" 6 "Betriebsart_X" 7 "Betriebsart_Y" ;
VAL_ 1649 KL_Stopp_Wiederstart_Anz_01 0 "keine_Anzeige" 1 "Geblaese" ;
VAL_ 1649 KL_Stopp_Wiederstart_Anz_02 0 "keine_Anzeige" 1 "Differenz_Soll_Ausblas_zu_Ist_Ausblastemperatur" ;
VAL_ 1649 KL_Stopp_Wiederstart_Anz_03 0 "keine_Anzeige" 1 "Beschlagsgefahr" ;
VAL_ 1649 KL_Stopp_Wiederstart_Anz_04 0 "keine_Anzeige" 1 "Differenz_Soll_Innentemperatur_zu_Ist_Innenraumtemperatur" ;
VAL_ 1649 KL_Stopp_Wiederstart_Anz_05 0 "keine_Anzeige" 1 "Komfortfeuchte" ;
VAL_ 1649 KL_Stopp_Wiederstart_Anz_06 0 "keine_Anzeige" 1 "Aussentemperatur" ;
VAL_ 1649 KL_Stopp_Wiederstart_Anz_07 0 "keine_Anzeige" 1 "Defrost" ;
VAL_ 1649 KL_Stopp_Wiederstart_Anz_08 0 "keine_Anzeige" 1 "High_Low" ;
VAL_ 1649 KL_Stopp_Wiederstart_Anz_09 0 "keine_Anzeige" 1 "Frontscheibenheizung" ;
VAL_ 1649 KL_Stopp_Wiederstart_Anz_Std1 0 "keine_Anzeige" 1 "maxA/C" ;
VAL_ 1649 KL_Stopp_Wiederstart_Anz_Std2 0 "keine_Anzeige" 1 "Sitzlueftung" ;
VAL_ 1649 KL_Meldung_Status 0 "keine_notification" 1 "Klima_eingeschraenkt" 2 "Klima_Warnung" 3 "Service_Klima" 4 "Fahrzeug_Lueften_Gelb" 5 "Fahrzeug_Lueften_Rot" 6 "Fahrzeug_Lueften_3" 7 "Klima_Abwurf" 8 "reserve_1" 9 "reserve_2" ;
VAL_ 1649 KL_ErwVK_Status 0 "nicht_angefordert" 1 "Fahrerzone_aktiv" 2 "Beifahrerzone_aktiv" 3 "Heckzone_links_aktiv" 4 "Heckzone_recht_aktiv" 5 "Scheibenheizung_aktiv" ;
VAL_ 1649 KL_Hinweis_Kuehlmodus 0 "aus" 1 "Stufe1" 2 "Stufe2" 3 "Stufe3" ;
VAL_ 1649 KL_ErwVK_Beifahrerzone 0 "nicht_aktiv" 1 "Beifahrerzone_aktiv" ;
VAL_ 1649 KL_ErwVK_Fahrerzone 0 "nicht_aktiv" 1 "Fahrerzone_aktiv" ;
VAL_ 1649 KL_ErwVK_Heckzone_links 0 "nicht_aktiv" 1 "Heckzone_links_aktiv" ;
VAL_ 1649 Kl_ErwVK_Heckzone_rechts 0 "nicht_aktiv" 1 "Heckzone_rechts_aktiv" ;
VAL_ 949 KL_Drehz_Anh 0 "keine_Anhebung" 1 "Drehzahlanhebung_vom_Motor_angefordert" ;
VAL_ 949 KL_Vorwarn_Komp_ein 0 "Init" 1 "Vorwarnung_Kompressor_ein" ;
VAL_ 949 KL_AC_Schalter 0 "aus" 1 "ein" ;
VAL_ 949 KL_Komp_Moment_alt 1 "veraltet_bzw_Ermittlung_des_Moments_nicht_moeglich__zB_keine_Drehzahl_kein_Kaeltemitteldruck" ;
VAL_ 949 KL_Vorwarn_Zuheizer_ein 0 "keine_Vorwarnung" 1 "Vorwarnung_Zuheizer_ein" ;
VAL_ 949 KL_Zustand 0 "Aus" 1 "Ein" ;
VAL_ 949 KL_Kompressorkupplung_linear 253 "volle_Ansteuerung" 254 "Init__nicht_bedient" ;
VAL_ 949 KL_Charisma_FahrPr 0 "keine_Funktion" 1 "Programm_1" 2 "Programm_2" 3 "Programm_3" 4 "Programm_4" 5 "Programm_5" 6 "Programm_6" 7 "Programm_7" 8 "Programm_8" 9 "Programm_9" 10 "Programm_10" 11 "Programm_11" 12 "Programm_12" 13 "Programm_13" 14 "Programm_14" 15 "Programm_15" ;
VAL_ 949 KL_Charisma_Status 0 "Init" 1 "verfuegbar" 2 "nicht_verfuegbar" 3 "asynchron_durch_Fahrerwunsch" ;
VAL_ 949 KL_nachtr_Stopp_Anf 0 "nicht_angefordert" 1 "angefordert" ;
VAL_ 949 KL_T_Charge 0 "Taster_nicht_betaetigt" 1 "Taster_betaetigt" ;
VAL_ 949 KL_Last_Kompr 255 "Fehler" ;
VAL_ 949 KL_Spannungs_Anf 0 "keine_Anforderung" 1 "Anforderung_Stufe_1" 2 "Anforderung_Stufe_2" 3 "Anforderung_Stufe_3" ;
VAL_ 949 KL_Thermomanagement 0 "keine_Freigabe_TMM__max_Heizbedarf" 1 "kleine_Freigabe_TMM" 2 "mittlere_Freigabe_TMM" 3 "volle_Freigabe_TMM__kein_Heizbedarf" ;
VAL_ 949 KL_StartStopp_Info 0 "Motorlauf_nicht_notwendig_(Stoppfreigabe)" 1 "Motoranlauf_nicht_zwingend_notwendig_(Stoppverbot,keine_Startanforderung)" 2 "Motoranlauf_zwingend_notwendig_(Startanforderung)" 3 "Systemfehler" ;
VAL_ 949 KL_Freilauf_Info 0 "Freilauf_freigegeben" 1 "Uebergang_in_Freilauf_unzulaessig" 2 "Freilauf_nicht_freigegeben_Abbruch" 3 "Freilauf_Anforderung" ;
VAL_ 949 KL_Anf_KL 255 "Fehler" ;
VAL_ 949 KL_el_Zuheizer_Stufe 0 "Aus" 1 "Stufe_1" 2 "Stufe_2" 3 "Stufe_3" ;
VAL_ 949 KL_Ausstattung_Klima 0 "Heizung_elektrisch" 1 "Klimamanuell_elektrisch" 2 "Climatic__1_Zone" 3 "Climatronic__1_Zone" 4 "Climatronic__2_Zonen" 5 "Climatronic__3_Zonen" 6 "Climatronic__4_Zonen" 7 "reserviert" ;
VAL_ 949 KL_Variante_Standheizung 0 "Wasserstandheizung_60_min_Laufzeit" 1 "Luftstandheizung_120_min_Laufzeit" 2 "Wasserstandheizung_120_min_Laufzeit" 3 "Wasser_und_Luftstandheizung_120_min_Laufzeit" ;
VAL_ 949 KL_AirCleaner_aktiv 0 "AirCleaner_nicht_aktiv" 1 "AirCleaner_aktiv" ;
VAL_ 949 KL_Anf_KV 126 "Init" ;
VAL_ 1640 KL_LRH_Taster 0 "nicht_betaetigt" 1 "betaetigt" ;
VAL_ 1640 KL_LRH_Stufe 0 "Stufe_niedrig" 1 "Stufe_mittel" 2 "Stufe_hoch" 3 "AUS" ;
VAL_ 1640 HSH_Taster 0 "nicht_betaetigt" 1 "short_push" 2 "long_push" 3 "tbd" ;
VAL_ 1640 FSH_Taster 0 "nicht_betaetigt" 1 "betaetigt" ;
VAL_ 1640 KL_Zuheizer_Freigabe 0 "keine_Freigabe_Zuheizer" 1 "Zuheizerfreigabe" ;
VAL_ 1640 KL_Beschlagsgefahr 0 "keine_Beschlagsgefahr" 1 "Beschlagsgefahr" ;
VAL_ 1640 KRH_Soll_li 0 "aus" 1 "Stufe_1" 2 "Stufe_2" 3 "Stufe_3" ;
VAL_ 1640 KRH_Soll_re 0 "aus" 1 "Stufe_1" 2 "Stufe_2" 3 "Stufe_3" ;
VAL_ 1640 KL_Geblspng_Soll 0 "0V_Motorspannung" 252 "0V_sofort_Abschalten" 253 "0V_senken_mit_Rampe" 254 "reserviert" 255 "Fehler" ;
VAL_ 1640 KL_Geblspng_Fond_Soll 0 "0V_Motorspannung" 252 "0V_sofort_Abschalten" 253 "0V_senken_mit_Rampe" 254 "reserviert" 255 "Fehler" ;
VAL_ 1640 KL_I_Geblaese 255 "Fehler" ;
VAL_ 1640 KL_Kompressorstrom_soll 1022 "Init" 1023 "Fehler" ;
VAL_ 1640 KL_Umluftklappe_Status 0 "Frischluft" 1 "Teilumluft_10" 2 "Teilumluft_20" 3 "Teilumluft_30" 4 "Teilumluft_40" 5 "Teilumluft_50" 6 "Teilumluft_60" 7 "Teilumluft_70" 8 "Teilumluft_80" 9 "Teilumluft_90" 10 "Umluft" 14 "Init" 15 "Fehler" ;
VAL_ 1640 KL_PTC_Verbauinfo 0 "kein_PTC" 1 "600W_geschaltet" 2 "1000W_geschaltet" 3 "1400W_LIN" ;
VAL_ 2527679635 KL_Voko_Status 0 "aus" 1 "ein" 14 "Init" 15 "Fehler" ;
VAL_ 2527679635 KL_LRH_Soll 0 "nicht_angefordert" 1 "angefordert" ;
VAL_ 2527679635 KL_AL_VR_Anf 0 "Init" 1 "waermer" 2 "kaelter" ;
VAL_ 2527679635 KL_AL_VL_Anf 0 "Init" 1 "waermer" 2 "kaelter" ;
VAL_ 2527679635 KL_AL_HR_Anf 0 "Init" 1 "waermer" 2 "kaelter" ;
VAL_ 2527679635 KL_AL_HL_Anf 0 "Init" 1 "waermer" 2 "kaelter" ;
VAL_ 2527679635 KL_HSH_Soll 0 "nicht_angefordert" 1 "angefordert" ;
VAL_ 2527679635 KL_FSH_Soll 0 "nicht_angefordert" 1 "angefordert" ;
VAL_ 2527679635 KL_ZR_Anforderung 0 "init" 1 "inaktiv" 2 "aktiv" 3 "reserviert" ;
VAL_ 2527679635 KL_VoKo_LED 0 "Aus" 1 "Ein" ;
VAL_ 2527679635 KL_Defrost_LED 0 "Aus" 1 "Ein" ;
VAL_ 2527679635 KL_HSH_LED 0 "Aus" 1 "Ein" ;
VAL_ 2527679635 HSH_Relais_Anf 0 "nicht_angefordert" 1 "angefordert" ;
VAL_ 2527679635 FSH_Status 0 "aus" 1 "ein" 2 "tbd" 3 "Fehler" ;
VAL_ 2527679635 SIH_Stufe_LED_li 0 "Aus" 2 "Stufe_2" 4 "Stufe_4" 6 "Stufe_6" ;
VAL_ 2527679635 SIH_Stufe_LED_re 0 "Aus" 2 "Stufe_2" 4 "Stufe_4" 6 "Stufe_6" ;
VAL_ 2527679635 KL_FSH_LED 0 "Aus" 1 "Ein" ;
VAL_ 2527679635 KL_HUP_aktiv 0 "Aus" 1 "Ein" ;
VAL_ 2527679635 KL_LSH_DBetr_Ein 0 "Dauerbetrieb_nicht_gefordert" 1 "Dauerbetrieb_gefordert" ;
VAL_ 2527679635 KL_LSH_DBetr_Bestaet 0 "kein_Dauerbetrieb" 1 "Dauerbetrieb_bestaetigt" ;
VAL_ 2527679635 KL_Klappe_Status 0 "Init" 1 "Front" 2 "Heck" 3 "Front_u_Heck" 4 "misch_Front_u_Heck" ;
VAL_ 2527679635 KL_LSH_Ansteuerung 0 "Aus" 1 "Ein" 2 "Kombi_Betrieb" 3 "Heizleistung_reduziert" ;
VAL_ 2527679635 KL_Heizstufe_LSH 0 "Init" 1 "Stufe_1" 2 "Stufe_2" 3 "Stufe_3" 4 "Stufe_4" 5 "Stufe_5" 6 "Stufe_6" 7 "Stufe_7" 8 "Stufe_8" 9 "Stufe_9" 10 "Stufe_10" 15 "Fehler" ;
VAL_ 2527679635 KL_LSH_Betriebsdauer 127 "Dauerbetrieb" ;
VAL_ 2527679635 KL_Temp_ZH_Soll 0 "Funk_nicht_verbaut_nicht_aktiv" 255 "Fehler" ;
VAL_ 2589283627 KL_HVH_1_VerbautStatus 0 "nicht_verbaut" 1 "verbaut" ;
VAL_ 2589283627 KL_EKK_1_VerbautStatus 0 "nicht_verbaut" 1 "verbaut" ;
VAL_ 2589283627 KL_Texte 0 "keine_Anzeige" 1 "Heizleistung_zu_gering" 2 "Kuehlleistung_zu_gering" 3 "Text_3" ;
VAL_ 2589283627 KL_HVH_2_VerbautStatus 0 "nicht_verbaut" 1 "verbaut" ;
VAL_ 2589283627 KL_EKK_2_VerbautStatus 0 "nicht_verbaut" 1 "verbaut" ;
VAL_ 2589283627 KL_Leistung_Klima_Anf 254 "Init" ;
VAL_ 2589283627 KL_Heizen_Status 0 "Keine_Heizleistung_Anfgefordert" 1 "Max_Defrost" 2 "Kaltstart" 3 "Eingeschwungen_hohe_Last" 4 "Eingeschwungen_niedrige_Last" 14 "Init" 15 "Fehler" ;
VAL_ 2589283627 KL_K_Status 0 "Init" 1 "Lueften" 2 "Kuehlen_Innenraum" 3 "Kuehlen_Chiller" 4 "Kuehlen_kombiniert" 5 "Heizen_Luft_WP" 6 "Heizen_kombiniert_WP" 7 "Kuehlen_Innenraum_mit_HGK" 8 "Kuehlen_kombiniert_mit_HGK" 9 "Heizen_Wasser_WP" 10 "Shutdown" 11 "Enteisen" 14 "Fehler" ;
VAL_ 2589283627 KL_Status_Battkuehlung 0 "Init" 1 "Keine_Kuehlanforderung" 2 "Kuehlung_in_Ordnung" 3 "Kuehlung_temporaer_nicht_aktiv" 4 "Kuehlung_inaktiv_fuer_Komfort" 5 "Kuehlung_nicht_moeglich" ;
VAL_ 2589283627 Kl_Klima_Aktiv 0 "Nicht_aktiv_oder_Init" 1 "Klima_aktiv" ;
VAL_ 2589283627 KL_Kuehlungs_Status 0 "Klimatisierung_ausgeschaltet" 1 "Pulldown" 2 "Eingeschwungen_hohe_Last" 3 "Eingeschwungen_niedrige_Last" 4 "Eingeschwungen_mit_Drehzahlbegre" 5 "BattK_nicht_moeglich" 6 "BattK_temporaer_nicht_moeglich" 14 "Init" 15 "Fehler" ;
VAL_ 2589283627 KL_HV_Energie_Anf 253 "nicht_berechnet" 254 "Init" 255 "Fehler" ;
VAL_ 2589283627 TME_HVEM_HV_Anf 0 "INIT" 1 "HV_Netz_nicht_angefordert" 2 "HV_Netz_angefordert" 3 "Fehler" ;
VAL_ 2589283627 KL_IstLeistung 254 "Init" 255 "Fehler" ;
VAL_ 2589283627 KL_Temp_Kundenwunsch 0 "Init" 1 "LO" 30 "HI" 63 "Fehler" ;
VAL_ 1712 FS_Taupunkt 0 "nicht verfuegbar" 1023 "Fehler" ;
VAL_ 1712 FS_ResponseError 0 "normal" 1 "Fehler" ;
VAL_ 1712 FS_Temp_Scheibe 0 "nicht verfuegbar" 1023 "Fehler" ;
VAL_ 1712 FS_Temp_Sensor 0 "nicht verfuegbar" 255 "Fehler" ;
VAL_ 1712 FS_Luftfeuchte_rel 0 "nicht verfuegbar" 255 "Fehler" ;
VAL_ 1505 BCM1_Aussen_Temp_ungef 253 "nicht_verbaut" 254 "Initwert" 255 "Fehler" ;
VAL_ 1505 BCM_Heizungsabsperrventil_Status 0 "HAV_offen" 1 "HAV_geschlossen" 2 "Init_oder_nicht_verbaut" 3 "Fehler" ;
VAL_ 1505 BCM_Heizungspumpe_Status 0 "Pumpe_aus" 1 "Pumpe_aktiv_und_Stauts_iO" 2 "Init_oder_nicht_verbaut" 3 "Fehler" ;
VAL_ 1505 BCM_Kompressorkupplung_Status 0 "Kupplung_offen" 1 "Kupplung_geschlossen" 2 "Init_oder_nicht_verbaut" 3 "Fehler" ;
VAL_ 1505 BCM1_PTC_stufig_Status 0 "Aus" 1 "Stufe_1_aktiv" 2 "Stufe_2_aktiv" 3 "Stufe_3_aktiv" 6 "Init_oder_nicht_verbaut" 7 "Fehler" ;
VAL_ 1505 BCM1_FStatus_Aussentemp_ungef 0 "iO" 1 "niO" ;
VAL_ 1505 BCM1_Kompressorstrom_ist 254 "Init, bzw. nicht verfuegbar" 255 "Fehler" ;
VAL_ 1505 BCM1_OBD_FStatus_ATemp 0 "kein Fehler / Init / nicht verbaut" 1 "KS- (Kurzschluss nach minus)" 2 "KS+ (Kurzschluss nach plus)" 3 "OC (Leitungsunterbrechung)" 4 "OOR+ (Signal zu gross)" 5 "OOR- (Signal zu klein)" 6 "RC+ (Signal unplausibel zu gross)" 7 "RC- (Signal unplausibel zu klein)" 8 "KS+/OC (Kurzschluss nach plus/Unterbrechung)" 9 "KS-/OC  (Kurzschluss nach minus/Unterbrechung)" 10 "KS-/KS+  (Kurzschluss nach minus/plus)" 11 "KS-/KS+/OC (Kurzschluss nach minus/plus/Unterbrechung)" 12 "frei" 13 "frei" 14 "frei" 15 "frei" ;
VAL_ 1717 FSA_Taupunkt 1021 "nicht_verbaut" 1022 "Init" 1023 "Fehler" ;
VAL_ 1717 FSA_Err_Defekt_Tsens_TF 0 "inaktiv" 1 "aktiv" ;
VAL_ 1717 FSA_Luftfeuchte_TNCTOC 0 "Test_Completed_TOC" 1 "Test_Not_Completed_TOC" ;
VAL_ 1717 FSA_Luftfeuchte_TF 0 "inaktiv" 1 "aktiv" ;
VAL_ 1717 FSA_Err_Unterspannung_TF 0 "inaktiv" 1 "aktiv" ;
VAL_ 1717 FSA_Err_RAMROM_Check_TF 0 "inaktiv" 1 "aktiv" ;
VAL_ 1717 FSA_ResponseError 0 "normal" 1 "Fehler" ;
VAL_ 1717 FSA_Temp_Luft 1021 "nicht_verbaut" 1022 "Init" 1023 "Fehler" ;
VAL_ 1717 FSA_Err_RAMROM_Check_TNCTOC 0 "Test_Completed_TOC" 1 "Test_Not_Completed_TOC" ;
VAL_ 1717 FSA_Err_Ueberspannung_TF 0 "inaktiv" 1 "aktiv" ;
VAL_ 1717 FSA_Luftfeuchte_rel 253 "nicht_verbaut" 254 "Init" 255 "Fehler" ;
VAL_ 1717 FSA_Temp_Sensor 2045 "nicht_verbaut" 2046 "Init" 2047 "Fehler" ;
VAL_ 1717 FSA_Sensorheizung_Status 0 "inaktiv" 1 "aktiv" ;
VAL_ 1717 FSA_Err_Defekt_HumSense_TF 0 "inaktiv" 1 "aktiv" ;
VAL_ 1717 FSA_Err_Defekt_HumSens_TNCTOC 0 "Test_Completed_TOC" 1 "Test_Not_Completed_TOC" ;
VAL_ 1717 FSA_ErrMemState 0 "Init_Default" 1 "ErrMem_Active_State" 2 "ErrMem_InitProgress" 3 "ErrMem_Init_done" ;
VAL_ 2549088367 AMP_KompSchutz 0 "inaktiv" 1 "aktiv" ;
VAL_ 2549088367 AMP_Abschaltstufe 0 "keine_Einschraenkung" 1 "Funktionseinschraenkung" ;
VAL_ 2549088367 AMP_Transport_Mode 0 "keine_Einschraenkung" 1 "Funktionseinschraenkung" ;
VAL_ 2549088367 AMP_Nachlauftyp 0 "Komm_bei_KL15_EIN" 1 "Komm_nach_KL15_AUS" 2 "Komm_bei_KL15_AUS" 4 "Buskopplung" ;
VAL_ 2549088367 NM_AMP_Wakeup 0 "Peripherie_Wakeup__Ursache_nicht_bekannt" 1 "Bus_Wakeup" 2 "KL15_HW" ;
VAL_ 2549088367 KN_AMP_DiagPfad 0 "aktiv" 1 "inaktiv" ;
VAL_ 2549088367 AMP_KD_Fehler 0 "Kein KD_Fehler" 1 "KD_Fehler" ;
VAL_ 2549088564 BedienDisp_m_KompSchutz 0 "inaktiv" 1 "aktiv" ;
VAL_ 2549088564 BedienDisp_m_Abschaltstufe 0 "keine_Einschraenkung" 1 "Funktionseinschraenkung" ;
VAL_ 2549088564 BedienDisp_m_Transport_Mode 0 "keine_Einschraenkung" 1 "Funktionseinschraenkung" ;
VAL_ 2549088564 BedienDisp_m_Nachlauftyp 0 "Komm_bei_KL15_EIN" 1 "Komm_nach_KL15_AUS" 2 "Komm_bei_KL15_AUS" ;
VAL_ 2549088564 KN_BedienDisp_m_ECUKnockOutTimer 63 "ECUKnockOut_deaktiviert" ;
VAL_ 2549088564 KN_BedienDisp_m_BusKnockOut 0 "Funktion_nicht_ausgeloest" 1 "Veto_aktiv" 2 "Funktion_ausgeloest" 3 "Funktion_deaktiviert" ;
VAL_ 2549088564 KN_BedienDisp_m_BusKnockoutTimer 255 "BusKnockOut_deaktiviert" ;
VAL_ 2549088564 NM_BedienDisp_m_Wakeup 0 "Peripherie_Wakeup__Ursache_nicht_bekannt" 1 "Bus_Wakeup" 2 "KL15_HW" ;
VAL_ 2549088564 KN_BedienDisp_m_ECUKnockOut 0 "Funktion_nicht_ausgeloest" 1 "Veto_war_aktiv" 2 "Funktion_ausgeloest" 3 "Funktion_deaktiviert" ;
VAL_ 2549088564 KN_BedienDisp_m_DiagPfad 0 "aktiv" 1 "inaktiv" ;
VAL_ 2549088564 BedienDisp_m_KD_Fehler 0 "kein_KD_Fehler" 1 "KD_Fehler" ;
VAL_ 2549088418 BedienDisp_vm_KompSchutz 0 "inaktiv" 1 "aktiv" ;
VAL_ 2549088418 BedienDisp_vm_Abschaltstufe 0 "keine_Einschraenkung" 1 "Funktionseinschraenkung" ;
VAL_ 2549088418 BedienDisp_vm_Transport_Mode 0 "keine_Einschraenkung" 1 "Funktionseinschraenkung" ;
VAL_ 2549088418 BedienDisp_vm_Nachlauftyp 0 "Komm_bei_KL15_EIN" 1 "Komm_nach_KL15_AUS" 2 "Komm_bei_KL15_AUS" ;
VAL_ 2549088418 KN_BedienDisp_vm_ECUKnockOutTime 63 "ECUKnockOut_deaktiviert" ;
VAL_ 2549088418 KN_BedienDisp_vm_BusKnockOut 0 "Funktion_nicht_ausgeloest" 1 "Veto_aktiv" 2 "Funktion_ausgeloest" 3 "Funktion_deaktiviert" ;
VAL_ 2549088418 KN_BedienDisp_vm_BusKnockOutTime 255 "BusKnockOut_deaktiviert" ;
VAL_ 2549088418 NM_BedienDisp_vm_Wakeup 0 "Peripherie_Wakeup__Ursache_nicht_bekannt" 1 "Bus_Wakeup" 2 "KL15_HW" ;
VAL_ 2549088418 KN_BedienDisp_vm_ECUKnockOut 0 "Funktion_nicht_ausgeloest" 1 "Veto_war_aktiv" 2 "Funktion_ausgeloest" 3 "Funktion_deaktiviert" ;
VAL_ 2549088418 KN_BedienDisp_vm_DiagPfad 0 "aktiv" 1 "inaktiv" ;
VAL_ 2549088418 BedienDisp_vm_KD_Fehler 0 "kein_KD_Fehler" 1 "KD_Fehler" ;
VAL_ 2549088570 DCAM_KompSchutz 0 "inaktiv" 1 "aktiv" ;
VAL_ 2549088570 DCAM_Abschaltstufe 0 "keine_Einschraenkung" 1 "Funktionseinschraenkung" ;
VAL_ 2549088570 DCAM_Transport_Mode 0 "keine_Einschraenkung" 1 "Funktionseinschraenkung" ;
VAL_ 2549088570 DCAM_Nachlauftyp 0 "Komm_bei_KL15_EIN" 1 "Komm_nach_KL15_AUS" 2 "Komm_bei_KL15_AUS" ;
VAL_ 2549088570 KN_DCAM_ECUKnockOutTimer 63 "ECUKnockOut_deaktiviert" ;
VAL_ 2549088570 KN_DCAM_BusKnockOut 0 "Funktion_nicht_ausgeloest" 1 "Veto_aktiv" 2 "Funktion_ausgeloest" 3 "Funktion_deaktiviert" ;
VAL_ 2549088570 KN_DCAM_BusKnockOutTimer 255 "BusKnockOut_deaktiviert" ;
VAL_ 2549088570 NM_DCAM_Wakeup 0 "Peripherie_Wakeup__Ursache_nicht_bekannt" 1 "Bus_Wakeup" 2 "KL15_HW" ;
VAL_ 2549088570 KN_DCAM_ECUKnockOut 0 "Funktion_nicht_ausgeloest" 1 "Veto_war_aktiv" 2 "Funktion_ausgeloest" 3 "Funktion_deaktiviert" ;
VAL_ 2549088570 KN_DCAM_DiagPfad 0 "aktiv" 1 "inaktiv" ;
VAL_ 2549088570 DCAM_KD_Fehler 0 "kein_KD_Fehler" 1 "KD_Fehler" ;
VAL_ 2549088359 eCall_KompSchutz 0 "inaktiv" 1 "aktiv" ;
VAL_ 2549088359 eCall_Abschaltstufe 0 "keine_Einschraenkung" 1 "Funktionseinschraenkung" ;
VAL_ 2549088359 eCall_Transport_Mode 0 "keine_Einschraenkung" 1 "Funktionseinschraenkung" ;
VAL_ 2549088359 eCall_Nachlauftyp 0 "Komm_bei_KL15_EIN" 1 "Komm_nach_KL15_AUS" 2 "Komm_bei_KL15_AUS" ;
VAL_ 2549088359 KN_eCall_ECUKnockOutTimer 63 "ECUKnockOut_deaktiviert" ;
VAL_ 2549088359 KN_eCall_BusKnockOut 0 "Funktion_nicht_ausgeloest" 1 "Veto_aktiv" 2 "Funktion_ausgeloest" 3 "Funktion_deaktiviert" ;
VAL_ 2549088359 KN_eCall_BusKnockOutTimer 255 "BusKnockOut_deaktiviert" ;
VAL_ 2549088359 NM_eCall_Wakeup 0 "Peripherie_Wakeup__Ursache_nicht_bekannt" 1 "Bus_Wakeup" 2 "KL15_HW" 128 "start_charging" 129 "stop_charging" 130 "change_timers" 131 "change_profiles" 132 "change_basic_settings" 133 "start_clima" 134 "stop_clima" 135 "SOC_Car_Status" 136 "start_window_heating" 137 "stop_window_heating" 138 "unplug_charge_plug" 139 "Remote_Honk_Flash" 140 "Remote_Lock_Unlock" 141 "Remote_Vehicle_Tracking" 142 "MQTT_Internal_renew" 143 "MQTT_Core_data_Ping" 144 "VTS_GNSS" 145 "VTS_GPS_Disabled" 146 "VTS_Cell_ID_Pos" 147 "VTS_Backup_Pow_Cut" 148 "VTS_GSM_Ant_Cut" 149 "VTS_GPS_Ant_Cut" 150 "VTS_No_GPRS_Signal" 151 "VTS_GPRS_Signal_Back" 152 "VTS_GSM_Ant_Jamming" 153 "VTS_GPS_Ant_Jamming" 154 "RemoteStart" 155 "Digital_Key" 156 "MQTT_GW_Wakeup" 157 "IAA" 158 "aktiv_MicBias" 159 "Anforderung_ORU_PopUp" 160 "PSO" ;
VAL_ 2549088359 KN_eCall_ECUKnockOut 0 "Funktion_nicht_ausgeloest" 1 "Veto_war_aktiv" 2 "Funktion_ausgeloest" 3 "Funktion_deaktiviert" ;
VAL_ 2549088359 KN_eCall_DiagPfad 0 "aktiv" 1 "inaktiv" ;
VAL_ 2549088359 eCall_KD_Fehler 0 "kein_KD_Fehler" 1 "KD_Fehler" ;
VAL_ 2549088272 Gateway_KompSchutz 0 "inaktiv" 1 "aktiv" ;
VAL_ 2549088272 Gateway_Abschaltstufe 0 "keine_Einschraenkung" 1 "Funktionseinschraenkung" ;
VAL_ 2549088272 Gateway_Transport_Mode 0 "keine_Einschraenkung" 1 "Funktionseinschraenkung" ;
VAL_ 2549088272 Gateway_Nachlauftyp 0 "Komm_bei_KL15_EIN" 1 "Komm_nach_KL15_AUS" 2 "Komm_bei_KL15_AUS" ;
VAL_ 2549088272 NM_Gateway_Wakeup 0 "Peripherie_Wakeup__Ursache_nicht_bekannt" 1 "Bus_Wakeup" 2 "KL15_HW" 3 "ACAN_Wakeup" 4 "FCAN_Wakeup" 5 "KCAN_Wakeup" 6 "ICAN_Wakeup" 7 "DiagCAN_Wakeup" 8 "ECAN_Wakeup" 9 "Energie_LIN_Wakeup" 10 "Bedien_LIN_Wakeup" 11 "HybridCAN_Wakeup" 12 "Flexray_Wakeup" 13 "MFL_WakeUp" 14 "Ethernet" 15 "DCAN_Wakeup" 16 "K2CAN_Wakeup" 17 "CCAN" 18 "AFSCAN_Wakeup" 19 "LIN1" 20 "LIN2" 21 "LIN3" 22 "LIN4" 23 "LIN5" 24 "LIN6" 25 "FASCAN" 26 "FAS2CAN" 27 "MDKCAN" 32 "FlexRay_Branch1_WakeUp" 33 "FlexRay_Branch2_WakeUp" 34 "FlexRay_Branch3_WakeUp" 35 "FlexRay_Branch4_WakeUp" 36 "FlexRay_Branch5_WakeUp" 37 "FlexRay_Branch6_WakeUp" 38 "FlexRay_Branch7_WakeUp" 39 "FlexRay_Branch8_WakeUp" 40 "FlexRay_Branch9_WakeUp" 41 "FlexRay_Branch10_WakeUp" 42 "FlexRay_Branch11_WakeUp" 43 "FlexRay_Branch12_WakeUp" 44 "FlexRay_Branch13_WakeUp" 45 "FlexRay_Branch14_WakeUp" 46 "FlexRay_Branch15_WakeUp" 47 "FlexRay_Branch16_WakeUp" 128 "Energiemanagement" 129 "Funktionswakeup_OBDC" 130 "Hochvoltenergiemanagement" 131 "CWU_empfangen" 132 "Fuer_Bus_relevanten_FC_empfangen" 133 "OnlineDienst_empfangen" 134 "HV_Aktivieren" 135 "HV_Deaktivieren" 136 "VTS_Suche_DriverCard" 137 "VTS_Hupen_Blinken" 138 "Remote_Vehicle_Status" 139 "Plug_and_Charge" 140 "VTS_Wakeup_Infotainment" 141 "EMHLR" 142 "NFcGW_fordert_OTA_FC_an" 143 "Komponentenschutz" 144 "UserStateServer" 145 "Dimmung" 146 "Kessy" 147 "StandardAussenlicht" 148 "ParkKoordinator" 149 "HVLMDynamicChargingPOI" 150 "HVLMChargingManagementServer" 151 "HVLMExtendedChargingMonitoring" 152 "Zentralverriegelung" 153 "FunctionOnDemand" 154 "IAA" 155 "StandKlimatisierung" 156 "RealTimeMonitor" 157 "Klemmensteuerung" 158 "Fremdladung_erkannt" ;
VAL_ 2549088272 KN_GW_DiagPfad 0 "aktiv" 1 "inaktiv" ;
VAL_ 2549088272 GW_KD_Fehler 0 "kein_KD_Fehler" 1 "KD_Fehler" ;
